AUTOSAR XML (schema 4-2-2)
package /DBC_SysDesc_Can_Network/Pkg_Cluster
  can cluster Can_Network: baudrate=500000, protocol-name=CAN, protocol-version=2023_3_9_163737
    can physical channel Can_Network_Channel: comm-connectors=Conn_Can_Network_CANNODE_0_RDCU
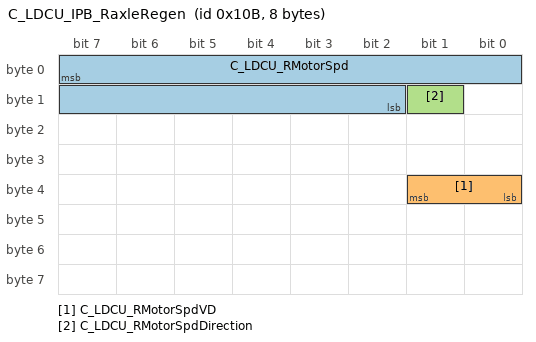
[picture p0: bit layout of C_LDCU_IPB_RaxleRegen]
      frame C_LDCU_IPB_RaxleRegen: id 0x10B, to RDCU, frame-length=8, can-addressing-mode=STANDARD, can-fd-frame-support=true, can-frame-rx-behavior=CAN-FD
        carries pdu C_LDCU_IPB_RaxleRegen: packing-byte-order=big-endian, start-position=7
        pdu C_LDCU_IPB_RaxleRegen: length=8
          transmission-mode-conditions:
            {data-filter={data-filter-type=NEW-IS-WITHIN, max=16000, min=0, offset=0}, i-signal-in-i-pdu=C_LDCU_RMotorSpd}
            {data-filter={data-filter-type=ALWAYS, max=1, min=0, offset=0}, i-signal-in-i-pdu=C_LDCU_RMotorSpdVD}
            {data-filter={data-filter-type=ALWAYS, max=1, min=0, offset=0}, i-signal-in-i-pdu=C_LDCU_RMotorSpdDirection}
            {data-filter={data-filter-type=NEW-IS-WITHIN, max=16000, min=0, offset=0}, i-signal-in-i-pdu=C_LDCU_RMotorSpd}
            {data-filter={data-filter-type=ALWAYS, max=1, min=0, offset=0}, i-signal-in-i-pdu=C_LDCU_RMotorSpdVD}
            {data-filter={data-filter-type=ALWAYS, max=1, min=0, offset=0}, i-signal-in-i-pdu=C_LDCU_RMotorSpdDirection}
          signal C_LDCU_RMotorSpd: start 7, 14 bit, big-endian, init-value=0, base-type=uint16, compu {raw=phys for phys 0..16000; unit rpm}, compu-method=CompuMethod_C_LDCU_RMotorSpd, update-indication-bit-position=-1, to RDCU(timeout 0.1 s)  # Motor speed request"
          signal C_LDCU_RMotorSpdVD: start 33, 2 bit, big-endian, init-value=0, base-type=uint8, compu {phys=raw for raw 0..1, 0=VALID, 1=INVALID}, compu-method=CompuMethod_C_LDCU_RMotorSpdVD, update-indication-bit-position=-1, to RDCU(timeout 0.1 s)
          signal C_LDCU_RMotorSpdDirection: start 9, 1 bit, big-endian, init-value=0, base-type=uint8, compu {phys=raw for raw 0..1, 0=NEGATIVE, 1=POSITIVE}, compu-method=CompuMethod_C_LDCU_RMotorSpdDirection, update-indication-bit-position=-1, to RDCU(timeout 0.1 s)
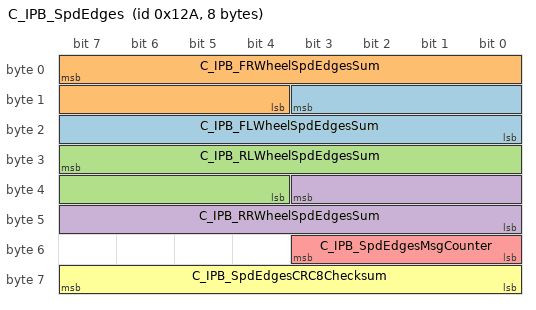
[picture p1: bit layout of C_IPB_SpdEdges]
      frame C_IPB_SpdEdges: id 0x12A, to RDCU, frame-length=8, can-addressing-mode=STANDARD, can-fd-frame-support=true, can-frame-rx-behavior=CAN-FD
        carries pdu C_IPB_SpdEdges: packing-byte-order=big-endian, start-position=7
        pdu C_IPB_SpdEdges: length=8
          transmission-mode-conditions:
            {data-filter={data-filter-type=NEW-IS-WITHIN, max=4095, min=0, offset=0}, i-signal-in-i-pdu=C_IPB_FLWheelSpdEdgesSum}
            {data-filter={data-filter-type=NEW-IS-WITHIN, max=4095, min=0, offset=0}, i-signal-in-i-pdu=C_IPB_FRWheelSpdEdgesSum}
            {data-filter={data-filter-type=NEW-IS-WITHIN, max=4095, min=0, offset=0}, i-signal-in-i-pdu=C_IPB_RLWheelSpdEdgesSum}
            {data-filter={data-filter-type=NEW-IS-WITHIN, max=4095, min=0, offset=0}, i-signal-in-i-pdu=C_IPB_RRWheelSpdEdgesSum}
            {data-filter={data-filter-type=ALWAYS, max=15, min=0, offset=0}, i-signal-in-i-pdu=C_IPB_SpdEdgesMsgCounter}
            {data-filter={data-filter-type=ALWAYS, max=255, min=0, offset=0}, i-signal-in-i-pdu=C_IPB_SpdEdgesCRC8Checksum}
            {data-filter={data-filter-type=NEW-IS-WITHIN, max=4095, min=0, offset=0}, i-signal-in-i-pdu=C_IPB_FLWheelSpdEdgesSum}
            {data-filter={data-filter-type=NEW-IS-WITHIN, max=4095, min=0, offset=0}, i-signal-in-i-pdu=C_IPB_FRWheelSpdEdgesSum}
            {data-filter={data-filter-type=NEW-IS-WITHIN, max=4095, min=0, offset=0}, i-signal-in-i-pdu=C_IPB_RLWheelSpdEdgesSum}
            {data-filter={data-filter-type=NEW-IS-WITHIN, max=4095, min=0, offset=0}, i-signal-in-i-pdu=C_IPB_RRWheelSpdEdgesSum}
            {data-filter={data-filter-type=ALWAYS, max=15, min=0, offset=0}, i-signal-in-i-pdu=C_IPB_SpdEdgesMsgCounter}
            {data-filter={data-filter-type=ALWAYS, max=255, min=0, offset=0}, i-signal-in-i-pdu=C_IPB_SpdEdgesCRC8Checksum}
          signal C_IPB_FLWheelSpdEdgesSum: start 11, 12 bit, big-endian, init-value=0, base-type=uint16, compu {raw=phys for phys 0..4095}, compu-method=CompuMethod_C_IPB_FLWheelSpdEdgesSum, update-indication-bit-position=-1, to RDCU(timeout 0.05 s)  # Accumulated sum of rising and falling edges of front left wheel speed sensor output¡¤since IGN ON,thevalidity/fault information of this signal is also judged by signal ESP_FLWheelSpdVD in ESP_SpdInfoF"
          signal C_IPB_FRWheelSpdEdgesSum: start 7, 12 bit, big-endian, init-value=0, base-type=uint16, compu {raw=phys for phys 0..4095}, compu-method=CompuMethod_C_IPB_FRWheelSpdEdgesSum, update-indication-bit-position=-1, to RDCU(timeout 0.05 s)  # Accumulated sum of rising and falling edges of front left wheel speed sensor output¡¤since IGN ON,thevalidity/fault information of this signal is also judged by signa ESP_FRWheelSpdVD in ESP_SpdInfoF"
          signal C_IPB_RLWheelSpdEdgesSum: start 31, 12 bit, big-endian, init-value=0, base-type=uint16, compu {raw=phys for phys 0..4095}, compu-method=CompuMethod_C_IPB_RLWheelSpdEdgesSum, update-indication-bit-position=-1, to RDCU(timeout 0.05 s)  # Accumulated sum of rising and falling edges of front left wheel speed sensor output¡¤since IGN ON,thevalidity/fault information of this signal is also judged by signa ESP_RLWheelSpdVD in ESP_SpdInfoR"
          signal C_IPB_RRWheelSpdEdgesSum: start 35, 12 bit, big-endian, init-value=0, base-type=uint16, compu {raw=phys for phys 0..4095}, compu-method=CompuMethod_C_IPB_RRWheelSpdEdgesSum, update-indication-bit-position=-1, to RDCU(timeout 0.05 s)  # Accumulated sum of rising and falling edges of front left wheel speed sensor output¡¤since IGN ON,thevalidity/fault information of this signal is also judged by signa ESP_RRWheelSpdVD in ESP_SpdInfoR"
          signal C_IPB_SpdEdgesMsgCounter: start 51, 4 bit, big-endian, init-value=0, base-type=uint8, compu {raw=phys for phys 0..15}, compu-method=CompuMethod_C_IPB_SpdEdgesMsgCounter, update-indication-bit-position=-1, to RDCU(timeout 0.05 s)  # The MessageCounter is a 0 _15 counter, increased of one unit on every message transmission"
          signal C_IPB_SpdEdgesCRC8Checksum: start 63, 8 bit, big-endian, init-value=0, base-type=uint8, compu {raw=phys for phys 0..255}, compu-method=CompuMethod_C_IPB_SpdEdgesCRC8Checksum, update-indication-bit-position=-1, to RDCU(timeout 0.05 s)  # CRC8"
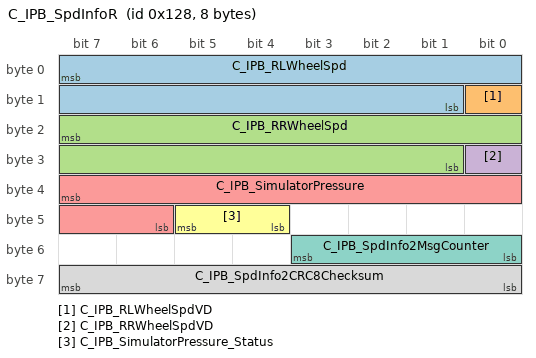
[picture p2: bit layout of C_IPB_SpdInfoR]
      frame C_IPB_SpdInfoR: id 0x128, to RDCU, frame-length=8, can-addressing-mode=STANDARD, can-fd-frame-support=true, can-frame-rx-behavior=CAN-FD
        carries pdu C_IPB_SpdInfoR: packing-byte-order=big-endian, start-position=7
        pdu C_IPB_SpdInfoR: length=8
          transmission-mode-conditions:
            {data-filter={data-filter-type=NEW-IS-WITHIN, max=23999, min=0, offset=0}, i-signal-in-i-pdu=C_IPB_RLWheelSpd}
            {data-filter={data-filter-type=ALWAYS, max=1, min=0, offset=0}, i-signal-in-i-pdu=C_IPB_RLWheelSpdVD}
            {data-filter={data-filter-type=NEW-IS-WITHIN, max=23999, min=0, offset=0}, i-signal-in-i-pdu=C_IPB_RRWheelSpd}
            {data-filter={data-filter-type=ALWAYS, max=1, min=0, offset=0}, i-signal-in-i-pdu=C_IPB_RRWheelSpdVD}
            {data-filter={data-filter-type=NEW-IS-WITHIN, max=1023, min=0}, i-signal-in-i-pdu=C_IPB_SimulatorPressure}
            {data-filter={data-filter-type=ALWAYS, max=3, min=0, offset=0}, i-signal-in-i-pdu=C_IPB_SimulatorPressure_Status}
            {data-filter={data-filter-type=ALWAYS, max=15, min=0, offset=0}, i-signal-in-i-pdu=C_IPB_SpdInfo2MsgCounter}
            {data-filter={data-filter-type=ALWAYS, max=255, min=0, offset=0}, i-signal-in-i-pdu=C_IPB_SpdInfo2CRC8Checksum}
            {data-filter={data-filter-type=NEW-IS-WITHIN, max=23999, min=0, offset=0}, i-signal-in-i-pdu=C_IPB_RLWheelSpd}
            {data-filter={data-filter-type=ALWAYS, max=1, min=0, offset=0}, i-signal-in-i-pdu=C_IPB_RLWheelSpdVD}
            {data-filter={data-filter-type=NEW-IS-WITHIN, max=23999, min=0, offset=0}, i-signal-in-i-pdu=C_IPB_RRWheelSpd}
            {data-filter={data-filter-type=ALWAYS, max=1, min=0, offset=0}, i-signal-in-i-pdu=C_IPB_RRWheelSpdVD}
            {data-filter={data-filter-type=NEW-IS-WITHIN, max=1023, min=0}, i-signal-in-i-pdu=C_IPB_SimulatorPressure}
            {data-filter={data-filter-type=ALWAYS, max=3, min=0, offset=0}, i-signal-in-i-pdu=C_IPB_SimulatorPressure_Status}
            {data-filter={data-filter-type=ALWAYS, max=15, min=0, offset=0}, i-signal-in-i-pdu=C_IPB_SpdInfo2MsgCounter}
            {data-filter={data-filter-type=ALWAYS, max=255, min=0, offset=0}, i-signal-in-i-pdu=C_IPB_SpdInfo2CRC8Checksum}
          signal C_IPB_RLWheelSpd: start 7, 15 bit, big-endian, init-value=0, base-type=uint16, compu {raw=phys*100 for phys 0..239.99; unit kmph}, compu-method=CompuMethod_C_IPB_RLWheelSpd, update-indication-bit-position=-1, to RDCU(timeout 0.05 s)  # valid:0x0~0x5DBF invalid valve/Default value: 7FFF"
          signal C_IPB_RLWheelSpdVD: start 8, 1 bit, big-endian, init-value=0, base-type=uint8, compu {phys=raw for raw 0..1, 0=NOTVALID, 1=VALID}, compu-method=CompuMethod_C_IPB_RLWheelSpdVD, update-indication-bit-position=-1, to RDCU(timeout 0.05 s)
          signal C_IPB_RRWheelSpd: start 23, 15 bit, big-endian, init-value=0, base-type=uint16, compu {raw=phys*100 for phys 0..239.99; unit kmph}, compu-method=CompuMethod_C_IPB_RRWheelSpd, update-indication-bit-position=-1, to RDCU(timeout 0.05 s)  # valid:0x0~0x5DBF invalid valve/Default value: 7FFF"
          signal C_IPB_RRWheelSpdVD: start 24, 1 bit, big-endian, init-value=0, base-type=uint8, compu {phys=raw for raw 0..1, 0=NOTVALID, 1=VALID}, compu-method=CompuMethod_C_IPB_RRWheelSpdVD, update-indication-bit-position=-1, to RDCU(timeout 0.05 s)
          signal C_IPB_SimulatorPressure: start 39, 10 bit, big-endian, init-value=17, base-type=uint16, compu {raw=phys*3.333333333+16.66666667 for phys -5..301.9; unit bar}, compu-method=CompuMethod_C_IPB_SimulatorPressure, update-indication-bit-position=-1, to RDCU(timeout 0.05 s)  # Master cylinder pressure Valid:0x00-0x0x3FE; invalid valve/Default value: 0x3FF;"
          signal C_IPB_SimulatorPressure_Status: start 45, 2 bit, big-endian, init-value=0, base-type=uint8, compu {phys=raw for raw 0..3, 1=VALID, 2=INVALID}, compu-method=CompuMethod_C_IPB_SimulatorPressure_Status, update-indication-bit-position=-1, to RDCU(timeout 0.05 s)
          signal C_IPB_SpdInfo2MsgCounter: start 51, 4 bit, big-endian, init-value=0, base-type=uint8, compu {raw=phys for phys 0..15}, compu-method=CompuMethod_C_IPB_SpdInfo2MsgCounter, update-indication-bit-position=-1, to RDCU(timeout 0.05 s)  # The MessageCounter is a 0 ~ 15 counter, increased of one unit on every message transmission"
          signal C_IPB_SpdInfo2CRC8Checksum: start 63, 8 bit, big-endian, init-value=0, base-type=uint8, compu {raw=phys for phys 0..255}, compu-method=CompuMethod_C_IPB_SpdInfo2CRC8Checksum, update-indication-bit-position=-1, to RDCU(timeout 0.05 s)  # CRC8"
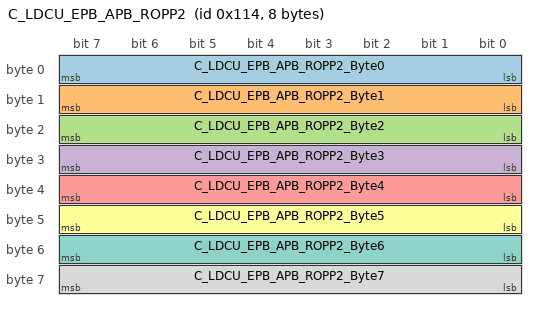
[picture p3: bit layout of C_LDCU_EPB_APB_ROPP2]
      frame C_LDCU_EPB_APB_ROPP2: id 0x114, to RDCU, frame-length=8, can-addressing-mode=STANDARD, can-fd-frame-support=true, can-frame-rx-behavior=CAN-FD  # E2E Profile1 Message"
        carries pdu C_LDCU_EPB_APB_ROPP2: packing-byte-order=big-endian, start-position=7
        pdu C_LDCU_EPB_APB_ROPP2: length=8  # E2E Profile1 Message
          transmission-mode-conditions:
            C_LDCU_EPB_APB_ROPP2_Byte{0..7}
            C_LDCU_EPB_APB_ROPP2_Byte{0..7}
          signal C_LDCU_EPB_APB_ROPP2_Byte0: start 7, 8 bit, big-endian, init-value=0, base-type=uint8, compu {raw=phys for phys 0..255}, compu-method=CompuMethod_C_LDCU_EPB_APB_ROPP2_Byte0, update-indication-bit-position=-1, to RDCU(timeout 0.1 s)
          signal C_LDCU_EPB_APB_ROPP2_Byte1: start 15, 8 bit, big-endian, init-value=0, base-type=uint8, compu {raw=phys for phys 0..255}, compu-method=CompuMethod_C_LDCU_EPB_APB_ROPP2_Byte1, update-indication-bit-position=-1, to RDCU(timeout 0.1 s)
          signal C_LDCU_EPB_APB_ROPP2_Byte2: start 23, 8 bit, big-endian, init-value=128, base-type=uint8, compu {raw=phys for phys 0..255}, compu-method=CompuMethod_C_LDCU_EPB_APB_ROPP2_Byte2, update-indication-bit-position=-1, to RDCU(timeout 0.1 s)
          signal C_LDCU_EPB_APB_ROPP2_Byte3: start 31, 8 bit, big-endian, init-value=0, base-type=uint8, compu {raw=phys for phys 0..255}, compu-method=CompuMethod_C_LDCU_EPB_APB_ROPP2_Byte3, update-indication-bit-position=-1, to RDCU(timeout 0.1 s)
          signal C_LDCU_EPB_APB_ROPP2_Byte4: start 39, 8 bit, big-endian, init-value=4, base-type=uint8, compu {raw=phys for phys 0..255}, compu-method=CompuMethod_C_LDCU_EPB_APB_ROPP2_Byte4, update-indication-bit-position=-1, to RDCU(timeout 0.1 s)
          signal C_LDCU_EPB_APB_ROPP2_Byte5: start 47, 8 bit, big-endian, init-value=0, base-type=uint8, compu {raw=phys for phys 0..255}, compu-method=CompuMethod_C_LDCU_EPB_APB_ROPP2_Byte5, update-indication-bit-position=-1, to RDCU(timeout 0.1 s)
          signal C_LDCU_EPB_APB_ROPP2_Byte6: start 55, 8 bit, big-endian, init-value=0, base-type=uint8, compu {raw=phys for phys 0..255}, compu-method=CompuMethod_C_LDCU_EPB_APB_ROPP2_Byte6, update-indication-bit-position=-1, to RDCU(timeout 0.1 s)
          signal C_LDCU_EPB_APB_ROPP2_Byte7: start 63, 8 bit, big-endian, init-value=0, base-type=uint8, compu {raw=phys for phys 0..255}, compu-method=CompuMethod_C_LDCU_EPB_APB_ROPP2_Byte7, update-indication-bit-position=-1, to RDCU(timeout 0.1 s)
          mapping ISignalToIPduMapping_ISigGrp_C_LDCU_EPB_APB_ROPP2: i-signal-group=ISigGrp_C_LDCU_EPB_APB_ROPP2
      frame C_IPB_SysSt_E2E: id 0x1A6, to RDCU, frame-length=12, can-addressing-mode=STANDARD, can-fd-frame-support=true, can-frame-rx-behavior=CAN-FD  # E2E Profile1 Message"
        carries pdu C_IPB_SysSt_E2E: packing-byte-order=big-endian, start-position=7
        pdu C_IPB_SysSt_E2E: length=12  # E2E Profile1 Message
          transmission-mode-conditions:
            C_IPB_SysSt_E2E_Byte{0..11}
            C_IPB_SysSt_E2E_Byte{0..11}
          signal C_IPB_SysSt_E2E_Byte0: start 7, 8 bit, big-endian, init-value=4, base-type=uint8, compu {raw=phys for phys 0..255}, compu-method=CompuMethod_C_IPB_SysSt_E2E_Byte0, update-indication-bit-position=-1, to RDCU(timeout 0.2 s)
          signal C_IPB_SysSt_E2E_Byte1: start 15, 8 bit, big-endian, init-value=34, base-type=uint8, compu {raw=phys for phys 0..255}, compu-method=CompuMethod_C_IPB_SysSt_E2E_Byte1, update-indication-bit-position=-1, to RDCU(timeout 0.2 s)
          signal C_IPB_SysSt_E2E_Byte2: start 23, 8 bit, big-endian, init-value=113, base-type=uint8, compu {raw=phys for phys 0..255}, compu-method=CompuMethod_C_IPB_SysSt_E2E_Byte2, update-indication-bit-position=-1, to RDCU(timeout 0.2 s)
          signal C_IPB_SysSt_E2E_Byte3: start 31, 8 bit, big-endian, init-value=39, base-type=uint8, compu {raw=phys for phys 0..255}, compu-method=CompuMethod_C_IPB_SysSt_E2E_Byte3, update-indication-bit-position=-1, to RDCU(timeout 0.2 s)
          signal C_IPB_SysSt_E2E_Byte4: start 39, 8 bit, big-endian, init-value=17, base-type=uint8, compu {raw=phys for phys 0..255}, compu-method=CompuMethod_C_IPB_SysSt_E2E_Byte4, update-indication-bit-position=-1, to RDCU(timeout 0.2 s)
          signal C_IPB_SysSt_E2E_Byte5: start 47, 8 bit, big-endian, init-value=116, base-type=uint8, compu {raw=phys for phys 0..255}, compu-method=CompuMethod_C_IPB_SysSt_E2E_Byte5, update-indication-bit-position=-1, to RDCU(timeout 0.2 s)
          signal C_IPB_SysSt_E2E_Byte6: start 55, 8 bit, big-endian, init-value=0, base-type=uint8, compu {raw=phys for phys 0..255}, compu-method=CompuMethod_C_IPB_SysSt_E2E_Byte6, update-indication-bit-position=-1, to RDCU(timeout 0.2 s)
          signal C_IPB_SysSt_E2E_Byte7: start 63, 8 bit, big-endian, init-value=0, base-type=uint8, compu {raw=phys for phys 0..255}, compu-method=CompuMethod_C_IPB_SysSt_E2E_Byte7, update-indication-bit-position=-1, to RDCU(timeout 0.2 s)
          signal C_IPB_SysSt_E2E_Byte8: start 71, 8 bit, big-endian, init-value=0, base-type=uint8, compu {raw=phys for phys 0..255}, compu-method=CompuMethod_C_IPB_SysSt_E2E_Byte8, update-indication-bit-position=-1, to RDCU(timeout 0.2 s)
          signal C_IPB_SysSt_E2E_Byte9: start 79, 8 bit, big-endian, init-value=0, base-type=uint8, compu {raw=phys for phys 0..255}, compu-method=CompuMethod_C_IPB_SysSt_E2E_Byte9, update-indication-bit-position=-1, to RDCU(timeout 0.2 s)
          signal C_IPB_SysSt_E2E_Byte10: start 87, 8 bit, big-endian, init-value=0, base-type=uint8, compu {raw=phys for phys 0..255}, compu-method=CompuMethod_C_IPB_SysSt_E2E_Byte10, update-indication-bit-position=-1, to RDCU(timeout 0.2 s)
          signal C_IPB_SysSt_E2E_Byte11: start 95, 8 bit, big-endian, init-value=0, base-type=uint8, compu {raw=phys for phys 0..255}, compu-method=CompuMethod_C_IPB_SysSt_E2E_Byte11, update-indication-bit-position=-1, to RDCU(timeout 0.2 s)
          mapping ISignalToIPduMapping_ISigGrp_C_IPB_SysSt_E2E: i-signal-group=ISigGrp_C_IPB_SysSt_E2E
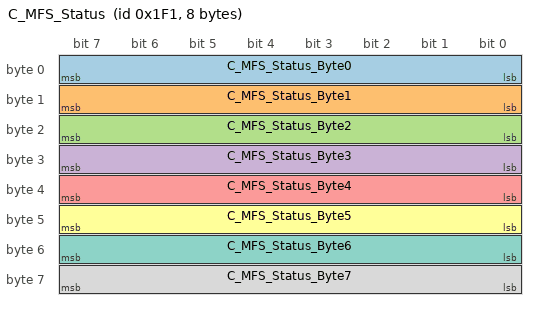
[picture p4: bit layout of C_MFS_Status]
      frame C_MFS_Status: id 0x1F1, to RDCU, frame-length=8, can-addressing-mode=STANDARD, can-fd-frame-support=true, can-frame-rx-behavior=CAN-FD  # E2E Profile1 Message"
        carries pdu C_MFS_Status: packing-byte-order=big-endian, start-position=7
        pdu C_MFS_Status: length=8  # E2E Profile1 Message
          transmission-mode-conditions:
            C_MFS_Status_Byte{0..7}
            C_MFS_Status_Byte{0..7}
          signal C_MFS_Status_Byte0: start 7, 8 bit, big-endian, init-value=0, base-type=uint8, compu {raw=phys for phys 0..255}, compu-method=CompuMethod_C_MFS_Status_Byte0, update-indication-bit-position=-1, to RDCU(timeout 0.2 s)
          signal C_MFS_Status_Byte1: start 15, 8 bit, big-endian, init-value=0, base-type=uint8, compu {raw=phys for phys 0..255}, compu-method=CompuMethod_C_MFS_Status_Byte1, update-indication-bit-position=-1, to RDCU(timeout 0.2 s)
          signal C_MFS_Status_Byte2: start 23, 8 bit, big-endian, init-value=0, base-type=uint8, compu {raw=phys for phys 0..255}, compu-method=CompuMethod_C_MFS_Status_Byte2, update-indication-bit-position=-1, to RDCU(timeout 0.2 s)
          signal C_MFS_Status_Byte3: start 31, 8 bit, big-endian, init-value=0, base-type=uint8, compu {raw=phys for phys 0..255}, compu-method=CompuMethod_C_MFS_Status_Byte3, update-indication-bit-position=-1, to RDCU(timeout 0.2 s)
          signal C_MFS_Status_Byte4: start 39, 8 bit, big-endian, init-value=0, base-type=uint8, compu {raw=phys for phys 0..255}, compu-method=CompuMethod_C_MFS_Status_Byte4, update-indication-bit-position=-1, to RDCU(timeout 0.2 s)
          signal C_MFS_Status_Byte5: start 47, 8 bit, big-endian, init-value=0, base-type=uint8, compu {raw=phys for phys 0..255}, compu-method=CompuMethod_C_MFS_Status_Byte5, update-indication-bit-position=-1, to RDCU(timeout 0.2 s)
          signal C_MFS_Status_Byte6: start 55, 8 bit, big-endian, init-value=0, base-type=uint8, compu {raw=phys for phys 0..255}, compu-method=CompuMethod_C_MFS_Status_Byte6, update-indication-bit-position=-1, to RDCU(timeout 0.2 s)
          signal C_MFS_Status_Byte7: start 63, 8 bit, big-endian, init-value=0, base-type=uint8, compu {raw=phys for phys 0..255}, compu-method=CompuMethod_C_MFS_Status_Byte7, update-indication-bit-position=-1, to RDCU(timeout 0.2 s)
          mapping ISignalToIPduMapping_ISigGrp_C_MFS_Status: i-signal-group=ISigGrp_C_MFS_Status
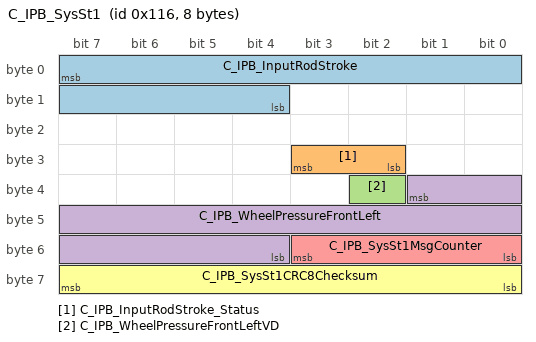
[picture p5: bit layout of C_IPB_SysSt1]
      frame C_IPB_SysSt1: id 0x116, to RDCU, frame-length=8, can-addressing-mode=STANDARD, can-fd-frame-support=true, can-frame-rx-behavior=CAN-FD
        carries pdu C_IPB_SysSt1: packing-byte-order=big-endian, start-position=7
        pdu C_IPB_SysSt1: length=8
          transmission-mode-conditions:
            {data-filter={data-filter-type=NEW-IS-WITHIN, max=1022, min=0}, i-signal-in-i-pdu=C_IPB_InputRodStroke}
            {data-filter={data-filter-type=ALWAYS, max=1, min=0, offset=0}, i-signal-in-i-pdu=C_IPB_InputRodStroke_Status}
            {data-filter={data-filter-type=ALWAYS, max=1, min=0, offset=0}, i-signal-in-i-pdu=C_IPB_WheelPressureFrontLeftVD}
            {data-filter={data-filter-type=NEW-IS-WITHIN, max=13440, min=0}, i-signal-in-i-pdu=C_IPB_WheelPressureFrontLeft}
            {data-filter={data-filter-type=ALWAYS, max=15, min=0, offset=0}, i-signal-in-i-pdu=C_IPB_SysSt1MsgCounter}
            {data-filter={data-filter-type=ALWAYS, max=255, min=0, offset=0}, i-signal-in-i-pdu=C_IPB_SysSt1CRC8Checksum}
            {data-filter={data-filter-type=NEW-IS-WITHIN, max=1022, min=0}, i-signal-in-i-pdu=C_IPB_InputRodStroke}
            {data-filter={data-filter-type=ALWAYS, max=1, min=0, offset=0}, i-signal-in-i-pdu=C_IPB_InputRodStroke_Status}
            {data-filter={data-filter-type=ALWAYS, max=1, min=0, offset=0}, i-signal-in-i-pdu=C_IPB_WheelPressureFrontLeftVD}
            {data-filter={data-filter-type=NEW-IS-WITHIN, max=13440, min=0}, i-signal-in-i-pdu=C_IPB_WheelPressureFrontLeft}
            {data-filter={data-filter-type=ALWAYS, max=15, min=0, offset=0}, i-signal-in-i-pdu=C_IPB_SysSt1MsgCounter}
            {data-filter={data-filter-type=ALWAYS, max=255, min=0, offset=0}, i-signal-in-i-pdu=C_IPB_SysSt1CRC8Checksum}
          signal C_IPB_InputRodStroke: start 7, 12 bit, big-endian, init-value=100, base-type=uint16, compu {raw=phys*20+100 for phys -5..46.15; unit mm}, compu-method=CompuMethod_C_IPB_InputRodStroke, update-indication-bit-position=-1, to RDCU(timeout 0.1 s)
          signal C_IPB_InputRodStroke_Status: start 27, 2 bit, big-endian, init-value=0, base-type=uint8, compu {phys=raw for raw 0..1, 0=VALID, 1=INVALID}, compu-method=CompuMethod_C_IPB_InputRodStroke_Status, update-indication-bit-position=-1, to RDCU(timeout 0.1 s)
          signal C_IPB_WheelPressureFrontLeftVD: start 34, 1 bit, big-endian, init-value=0, base-type=uint8, compu {phys=raw for raw 0..1, 0=NOTVALID, 1=VALID}, compu-method=CompuMethod_C_IPB_WheelPressureFrontLeftVD, update-indication-bit-position=-1, to RDCU(timeout 0.1 s)
          signal C_IPB_WheelPressureFrontLeft: start 33, 14 bit, big-endian, init-value=640, base-type=uint16, compu {raw=phys*32+640 for phys -20..400; unit bar}, compu-method=CompuMethod_C_IPB_WheelPressureFrontLeft, update-indication-bit-position=-1, to RDCU(timeout 0.1 s)  # Estimated or modeled wheel pressure of the rIPBective wheel brake. Modeled wheel pressure is needed in case of active hydraulic control"
          signal C_IPB_SysSt1MsgCounter: start 51, 4 bit, big-endian, init-value=0, base-type=uint8, compu {raw=phys for phys 0..15}, compu-method=CompuMethod_C_IPB_SysSt1MsgCounter, update-indication-bit-position=-1, to RDCU(timeout 0.1 s)  # Be incremented by 1 each time a CAN message has been transmitted by the sensor"
          signal C_IPB_SysSt1CRC8Checksum: start 63, 8 bit, big-endian, init-value=0, base-type=uint8, compu {raw=phys for phys 0..255}, compu-method=CompuMethod_C_IPB_SysSt1CRC8Checksum, update-indication-bit-position=-1, to RDCU(timeout 0.1 s)  # CRC8"
      frame C_AS_SysSt2: id 0x292, to RDCU, frame-length=48, can-addressing-mode=STANDARD, can-fd-frame-support=true, can-frame-rx-behavior=CAN-FD
        carries pdu C_AS_SysSt2: packing-byte-order=big-endian, start-position=7
        pdu C_AS_SysSt2: length=48
          transmission-mode-conditions:
            {data-filter={data-filter-type=NEW-IS-WITHIN, max=2000, min=0}, i-signal-in-i-pdu=C_AS_wheelPosFLFilt_mm}
            {data-filter={data-filter-type=NEW-IS-WITHIN, max=2000, min=0}, i-signal-in-i-pdu=C_AS_wheelPosFRFilt_mm}
            {data-filter={data-filter-type=NEW-IS-WITHIN, max=2000, min=0}, i-signal-in-i-pdu=C_AS_wheelPosRLFilt_mm}
            {data-filter={data-filter-type=NEW-IS-WITHIN, max=2000, min=0}, i-signal-in-i-pdu=C_AS_wheelPosRRFilt_mm}
            {data-filter={data-filter-type=NEW-IS-WITHIN, max=2000, min=0}, i-signal-in-i-pdu=C_AS_wheelPosFLFilt_mm}
            {data-filter={data-filter-type=NEW-IS-WITHIN, max=2000, min=0}, i-signal-in-i-pdu=C_AS_wheelPosFRFilt_mm}
            {data-filter={data-filter-type=NEW-IS-WITHIN, max=2000, min=0}, i-signal-in-i-pdu=C_AS_wheelPosRLFilt_mm}
            {data-filter={data-filter-type=NEW-IS-WITHIN, max=2000, min=0}, i-signal-in-i-pdu=C_AS_wheelPosRRFilt_mm}
          signal C_AS_wheelPosFLFilt_mm: start 7, 11 bit, big-endian, init-value=1000, base-type=uint16, compu {raw=phys+1000 for phys -1000..1000; unit mm}, compu-method=CompuMethod_C_AS_wheelPosFLFilt_mm, update-indication-bit-position=-1, to RDCU(timeout 0.2 s)  # Wheel position FL"
          signal C_AS_wheelPosFRFilt_mm: start 12, 11 bit, big-endian, init-value=1000, base-type=uint16, compu {raw=phys+1000 for phys -1000..1000; unit mm}, compu-method=CompuMethod_C_AS_wheelPosFRFilt_mm, update-indication-bit-position=-1, to RDCU(timeout 0.2 s)  # Wheel position FR"
          signal C_AS_wheelPosRLFilt_mm: start 17, 11 bit, big-endian, init-value=1000, base-type=uint16, compu {raw=phys+1000 for phys -1000..1000; unit mm}, compu-method=CompuMethod_C_AS_wheelPosRLFilt_mm, update-indication-bit-position=-1, to RDCU(timeout 0.2 s)  # Wheel position RL"
          signal C_AS_wheelPosRRFilt_mm: start 38, 11 bit, big-endian, init-value=1000, base-type=uint16, compu {raw=phys+1000 for phys -1000..1000; unit mm}, compu-method=CompuMethod_C_AS_wheelPosRRFilt_mm, update-indication-bit-position=-1, to RDCU(timeout 0.2 s)  # Wheel position RR"
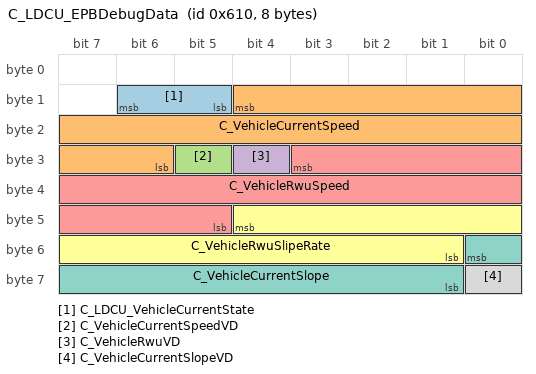
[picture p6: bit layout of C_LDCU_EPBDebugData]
      frame C_LDCU_EPBDebugData: id 0x610, to RDCU, frame-length=8, can-addressing-mode=STANDARD, can-fd-frame-support=true, can-frame-rx-behavior=CAN-FD
        carries pdu C_LDCU_EPBDebugData: packing-byte-order=big-endian, start-position=7
        pdu C_LDCU_EPBDebugData: length=8
          transmission-mode-conditions:
            {data-filter={data-filter-type=ALWAYS, max=3, min=0, offset=0}, i-signal-in-i-pdu=C_LDCU_VehicleCurrentState}
            {data-filter={data-filter-type=NEW-IS-WITHIN, max=23999, min=0, offset=0}, i-signal-in-i-pdu=C_VehicleCurrentSpeed}
            {data-filter={data-filter-type=ALWAYS, max=1, min=0, offset=0}, i-signal-in-i-pdu=C_VehicleCurrentSpeedVD}
            {data-filter={data-filter-type=ALWAYS, max=1, min=0, offset=0}, i-signal-in-i-pdu=C_VehicleRwuVD}
            {data-filter={data-filter-type=NEW-IS-WITHIN, max=23999, min=0, offset=0}, i-signal-in-i-pdu=C_VehicleRwuSpeed}
            {data-filter={data-filter-type=NEW-IS-WITHIN, max=1000, min=0, offset=0}, i-signal-in-i-pdu=C_VehicleRwuSlipeRate}
            {data-filter={data-filter-type=ALWAYS, max=80, min=0}, i-signal-in-i-pdu=C_VehicleCurrentSlope}
            {data-filter={data-filter-type=ALWAYS, max=1, min=0, offset=0}, i-signal-in-i-pdu=C_VehicleCurrentSlopeVD}
            {data-filter={data-filter-type=ALWAYS, max=3, min=0, offset=0}, i-signal-in-i-pdu=C_LDCU_VehicleCurrentState}
            {data-filter={data-filter-type=NEW-IS-WITHIN, max=23999, min=0, offset=0}, i-signal-in-i-pdu=C_VehicleCurrentSpeed}
            {data-filter={data-filter-type=ALWAYS, max=1, min=0, offset=0}, i-signal-in-i-pdu=C_VehicleCurrentSpeedVD}
            {data-filter={data-filter-type=ALWAYS, max=1, min=0, offset=0}, i-signal-in-i-pdu=C_VehicleRwuVD}
            {data-filter={data-filter-type=NEW-IS-WITHIN, max=23999, min=0, offset=0}, i-signal-in-i-pdu=C_VehicleRwuSpeed}
            {data-filter={data-filter-type=NEW-IS-WITHIN, max=1000, min=0, offset=0}, i-signal-in-i-pdu=C_VehicleRwuSlipeRate}
            {data-filter={data-filter-type=ALWAYS, max=80, min=0}, i-signal-in-i-pdu=C_VehicleCurrentSlope}
            {data-filter={data-filter-type=ALWAYS, max=1, min=0, offset=0}, i-signal-in-i-pdu=C_VehicleCurrentSlopeVD}
          signal C_LDCU_VehicleCurrentState: start 14, 2 bit, big-endian, init-value=0, base-type=uint8, compu {phys=raw for raw 0..3, 0=INVALID, 1=STANDSTILL, 2=MOTION, 3=RESERVED}, compu-method=CompuMethod_C_LDCU_VehicleCurrentState, update-indication-bit-position=-1, to RDCU(timeout 1 s)
          signal C_VehicleCurrentSpeed: start 12, 15 bit, big-endian, init-value=0, base-type=uint16, compu {raw=phys*100 for phys 0..239.99; unit kmph}, compu-method=CompuMethod_C_VehicleCurrentSpeed, update-indication-bit-position=-1, to RDCU(timeout 1 s)
          signal C_VehicleCurrentSpeedVD: start 29, 1 bit, big-endian, init-value=0, base-type=uint8, compu {phys=raw for raw 0..1, 0=NOTVALID, 1=VALID}, compu-method=CompuMethod_C_VehicleCurrentSpeedVD, update-indication-bit-position=-1, to RDCU(timeout 1 s)
          signal C_VehicleRwuVD: start 28, 1 bit, big-endian, init-value=0, base-type=uint8, compu {phys=raw for raw 0..1, 0=NOTVALID, 1=VALID}, compu-method=CompuMethod_C_VehicleRwuVD, update-indication-bit-position=-1, to RDCU(timeout 1 s)
          signal C_VehicleRwuSpeed: start 27, 15 bit, big-endian, init-value=0, base-type=uint16, compu {raw=phys*100 for phys 0..239.99; unit kmph}, compu-method=CompuMethod_C_VehicleRwuSpeed, update-indication-bit-position=-1, to RDCU(timeout 1 s)
          signal C_VehicleRwuSlipeRate: start 44, 12 bit, big-endian, init-value=0, base-type=uint16, compu {raw=phys*10 for phys 0..100; unit percent}, compu-method=CompuMethod_C_VehicleRwuSlipeRate, update-indication-bit-position=-1, to RDCU(timeout 1 s)
          signal C_VehicleCurrentSlope: start 48, 8 bit, big-endian, init-value=40, base-type=uint8, compu {raw=phys+40 for phys -40..40; unit percent}, compu-method=CompuMethod_C_VehicleCurrentSlope, update-indication-bit-position=-1, to RDCU(timeout 1 s)
          signal C_VehicleCurrentSlopeVD: start 56, 1 bit, big-endian, init-value=0, base-type=uint8, compu {phys=raw for raw 0..1, 0=NOTVALID, 1=VALID}, compu-method=CompuMethod_C_VehicleCurrentSlopeVD, update-indication-bit-position=-1, to RDCU(timeout 1 s)
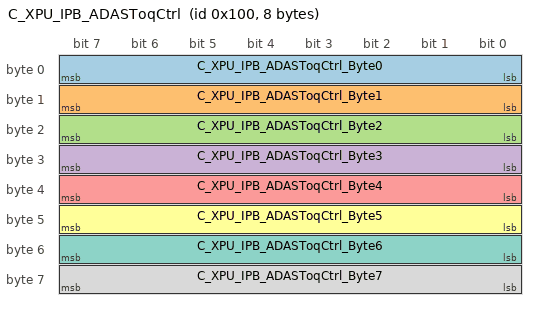
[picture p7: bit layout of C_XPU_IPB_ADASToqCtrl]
      frame C_XPU_IPB_ADASToqCtrl: id 0x100, to RDCU, frame-length=8, can-addressing-mode=STANDARD, can-fd-frame-support=true, can-frame-rx-behavior=CAN-FD  # E2E Profile1 Message"
        carries pdu C_XPU_IPB_ADASToqCtrl: packing-byte-order=big-endian, start-position=7
        pdu C_XPU_IPB_ADASToqCtrl: length=8  # E2E Profile1 Message
          transmission-mode-conditions:
            C_XPU_IPB_ADASToqCtrl_Byte{0..7}
            C_XPU_IPB_ADASToqCtrl_Byte{0..7}
          signal C_XPU_IPB_ADASToqCtrl_Byte0: start 7, 8 bit, big-endian, init-value=0, base-type=uint8, compu {raw=phys for phys 0..255}, compu-method=CompuMethod_C_XPU_IPB_ADASToqCtrl_Byte0, update-indication-bit-position=-1, to RDCU(timeout 0.1 s)
          signal C_XPU_IPB_ADASToqCtrl_Byte1: start 15, 8 bit, big-endian, init-value=4, base-type=uint8, compu {raw=phys for phys 0..255}, compu-method=CompuMethod_C_XPU_IPB_ADASToqCtrl_Byte1, update-indication-bit-position=-1, to RDCU(timeout 0.1 s)
          signal C_XPU_IPB_ADASToqCtrl_Byte2: start 23, 8 bit, big-endian, init-value=0, base-type=uint8, compu {raw=phys for phys 0..255}, compu-method=CompuMethod_C_XPU_IPB_ADASToqCtrl_Byte2, update-indication-bit-position=-1, to RDCU(timeout 0.1 s)
          signal C_XPU_IPB_ADASToqCtrl_Byte3: start 31, 8 bit, big-endian, init-value=0, base-type=uint8, compu {raw=phys for phys 0..255}, compu-method=CompuMethod_C_XPU_IPB_ADASToqCtrl_Byte3, update-indication-bit-position=-1, to RDCU(timeout 0.1 s)
          signal C_XPU_IPB_ADASToqCtrl_Byte4: start 39, 8 bit, big-endian, init-value=0, base-type=uint8, compu {raw=phys for phys 0..255}, compu-method=CompuMethod_C_XPU_IPB_ADASToqCtrl_Byte4, update-indication-bit-position=-1, to RDCU(timeout 0.1 s)
          signal C_XPU_IPB_ADASToqCtrl_Byte5: start 47, 8 bit, big-endian, init-value=0, base-type=uint8, compu {raw=phys for phys 0..255}, compu-method=CompuMethod_C_XPU_IPB_ADASToqCtrl_Byte5, update-indication-bit-position=-1, to RDCU(timeout 0.1 s)
          signal C_XPU_IPB_ADASToqCtrl_Byte6: start 55, 8 bit, big-endian, init-value=0, base-type=uint8, compu {raw=phys for phys 0..255}, compu-method=CompuMethod_C_XPU_IPB_ADASToqCtrl_Byte6, update-indication-bit-position=-1, to RDCU(timeout 0.1 s)
          signal C_XPU_IPB_ADASToqCtrl_Byte7: start 63, 8 bit, big-endian, init-value=0, base-type=uint8, compu {raw=phys for phys 0..255}, compu-method=CompuMethod_C_XPU_IPB_ADASToqCtrl_Byte7, update-indication-bit-position=-1, to RDCU(timeout 0.1 s)
          mapping ISignalToIPduMapping_ISigGrp_C_XPU_IPB_ADASToqCtrl: i-signal-group=ISigGrp_C_XPU_IPB_ADASToqCtrl
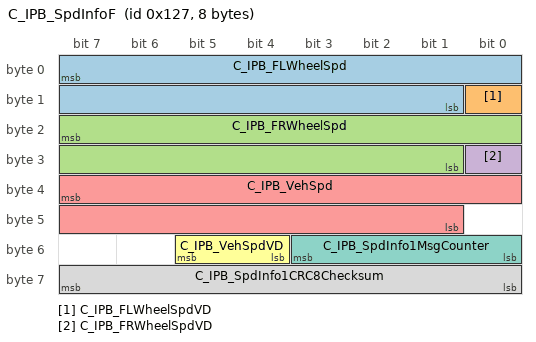
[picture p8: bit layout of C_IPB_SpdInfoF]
      frame C_IPB_SpdInfoF: id 0x127, to RDCU, frame-length=8, can-addressing-mode=STANDARD, can-fd-frame-support=true, can-frame-rx-behavior=CAN-FD  # IDS"
        carries pdu C_IPB_SpdInfoF: packing-byte-order=big-endian, start-position=7
        pdu C_IPB_SpdInfoF: length=8  # IDS
          transmission-mode-conditions:
            {data-filter={data-filter-type=NEW-IS-WITHIN, max=23999, min=0, offset=0}, i-signal-in-i-pdu=C_IPB_FLWheelSpd}
            {data-filter={data-filter-type=ALWAYS, max=1, min=0, offset=0}, i-signal-in-i-pdu=C_IPB_FLWheelSpdVD}
            {data-filter={data-filter-type=NEW-IS-WITHIN, max=23999, min=0, offset=0}, i-signal-in-i-pdu=C_IPB_FRWheelSpd}
            {data-filter={data-filter-type=ALWAYS, max=1, min=0, offset=0}, i-signal-in-i-pdu=C_IPB_FRWheelSpdVD}
            {data-filter={data-filter-type=NEW-IS-WITHIN, max=23999, min=0, offset=0}, i-signal-in-i-pdu=C_IPB_VehSpd}
            {data-filter={data-filter-type=ALWAYS, max=3, min=0, offset=0}, i-signal-in-i-pdu=C_IPB_VehSpdVD}
            {data-filter={data-filter-type=ALWAYS, max=15, min=0, offset=0}, i-signal-in-i-pdu=C_IPB_SpdInfo1MsgCounter}
            {data-filter={data-filter-type=ALWAYS, max=255, min=0, offset=0}, i-signal-in-i-pdu=C_IPB_SpdInfo1CRC8Checksum}
            {data-filter={data-filter-type=NEW-IS-WITHIN, max=23999, min=0, offset=0}, i-signal-in-i-pdu=C_IPB_FLWheelSpd}
            {data-filter={data-filter-type=ALWAYS, max=1, min=0, offset=0}, i-signal-in-i-pdu=C_IPB_FLWheelSpdVD}
            {data-filter={data-filter-type=NEW-IS-WITHIN, max=23999, min=0, offset=0}, i-signal-in-i-pdu=C_IPB_FRWheelSpd}
            {data-filter={data-filter-type=ALWAYS, max=1, min=0, offset=0}, i-signal-in-i-pdu=C_IPB_FRWheelSpdVD}
            {data-filter={data-filter-type=NEW-IS-WITHIN, max=23999, min=0, offset=0}, i-signal-in-i-pdu=C_IPB_VehSpd}
            {data-filter={data-filter-type=ALWAYS, max=3, min=0, offset=0}, i-signal-in-i-pdu=C_IPB_VehSpdVD}
            {data-filter={data-filter-type=ALWAYS, max=15, min=0, offset=0}, i-signal-in-i-pdu=C_IPB_SpdInfo1MsgCounter}
            {data-filter={data-filter-type=ALWAYS, max=255, min=0, offset=0}, i-signal-in-i-pdu=C_IPB_SpdInfo1CRC8Checksum}
          signal C_IPB_FLWheelSpd: start 7, 15 bit, big-endian, init-value=0, base-type=uint16, compu {raw=phys*100 for phys 0..239.99; unit kmph}, compu-method=CompuMethod_C_IPB_FLWheelSpd, update-indication-bit-position=-1, to RDCU(timeout 0.05 s)  # valid:0x0~0x5DBF invalid valve/Default value: 7FFF"
          signal C_IPB_FLWheelSpdVD: start 8, 1 bit, big-endian, init-value=0, base-type=uint8, compu {phys=raw for raw 0..1, 0=NOTVALID, 1=VALID}, compu-method=CompuMethod_C_IPB_FLWheelSpdVD, update-indication-bit-position=-1, to RDCU(timeout 0.05 s)
          signal C_IPB_FRWheelSpd: start 23, 15 bit, big-endian, init-value=0, base-type=uint16, compu {raw=phys*100 for phys 0..239.99; unit kmph}, compu-method=CompuMethod_C_IPB_FRWheelSpd, update-indication-bit-position=-1, to RDCU(timeout 0.05 s)  # valid:0x0~0x5DBF invalid valve/Default value: 7FFF"
          signal C_IPB_FRWheelSpdVD: start 24, 1 bit, big-endian, init-value=0, base-type=uint8, compu {phys=raw for raw 0..1, 0=NOTVALID, 1=VALID}, compu-method=CompuMethod_C_IPB_FRWheelSpdVD, update-indication-bit-position=-1, to RDCU(timeout 0.05 s)
          signal C_IPB_VehSpd: start 39, 15 bit, big-endian, init-value=0, base-type=uint16, compu {raw=phys*100 for phys 0..239.99; unit kmph}, compu-method=CompuMethod_C_IPB_VehSpd, update-indication-bit-position=-1, to RDCU(timeout 0.05 s)  # valid:0x0~0x5DBF invalid valve/Default value: 7FFF"
          signal C_IPB_VehSpdVD: start 53, 2 bit, big-endian, init-value=0, base-type=uint8, compu {phys=raw for raw 0..3, 0=NOTINITIALIZED, 1=VALID, 2=INVALID, 3=RESERVED}, compu-method=CompuMethod_C_IPB_VehSpdVD, update-indication-bit-position=-1, to RDCU(timeout 0.05 s)
          signal C_IPB_SpdInfo1MsgCounter: start 51, 4 bit, big-endian, init-value=0, base-type=uint8, compu {raw=phys for phys 0..15}, compu-method=CompuMethod_C_IPB_SpdInfo1MsgCounter, update-indication-bit-position=-1, to RDCU(timeout 0.05 s)  # The MessageCounter is a 0 ~ 15 counter, increased of one unit on every message transmission"
          signal C_IPB_SpdInfo1CRC8Checksum: start 63, 8 bit, big-endian, init-value=0, base-type=uint8, compu {raw=phys for phys 0..255}, compu-method=CompuMethod_C_IPB_SpdInfo1CRC8Checksum, update-indication-bit-position=-1, to RDCU(timeout 0.05 s)  # CRC8"
      frame C_IPB_SpdInfo_E2E: id 0x126, to RDCU, frame-length=16, can-addressing-mode=STANDARD, can-fd-frame-support=true, can-frame-rx-behavior=CAN-FD  # E2E Profile1 Message"
        carries pdu C_IPB_SpdInfo_E2E: packing-byte-order=big-endian, start-position=7
        pdu C_IPB_SpdInfo_E2E: length=16  # E2E Profile1 Message
          transmission-mode-conditions:
            C_IPB_SpdInfo_E2E_Byte{0..15}
            C_IPB_SpdInfo_E2E_Byte{0..15}
          signal C_IPB_SpdInfo_E2E_Byte0: start 7, 8 bit, big-endian, init-value=0, base-type=uint8, compu {raw=phys for phys 0..255}, compu-method=CompuMethod_C_IPB_SpdInfo_E2E_Byte0, update-indication-bit-position=-1, to RDCU(timeout 0.05 s)
          signal C_IPB_SpdInfo_E2E_Byte1: start 15, 8 bit, big-endian, init-value=0, base-type=uint8, compu {raw=phys for phys 0..255}, compu-method=CompuMethod_C_IPB_SpdInfo_E2E_Byte1, update-indication-bit-position=-1, to RDCU(timeout 0.05 s)
          signal C_IPB_SpdInfo_E2E_Byte2: start 23, 8 bit, big-endian, init-value=0, base-type=uint8, compu {raw=phys for phys 0..255}, compu-method=CompuMethod_C_IPB_SpdInfo_E2E_Byte2, update-indication-bit-position=-1, to RDCU(timeout 0.05 s)
          signal C_IPB_SpdInfo_E2E_Byte3: start 31, 8 bit, big-endian, init-value=0, base-type=uint8, compu {raw=phys for phys 0..255}, compu-method=CompuMethod_C_IPB_SpdInfo_E2E_Byte3, update-indication-bit-position=-1, to RDCU(timeout 0.05 s)
          signal C_IPB_SpdInfo_E2E_Byte4: start 39, 8 bit, big-endian, init-value=0, base-type=uint8, compu {raw=phys for phys 0..255}, compu-method=CompuMethod_C_IPB_SpdInfo_E2E_Byte4, update-indication-bit-position=-1, to RDCU(timeout 0.05 s)
          signal C_IPB_SpdInfo_E2E_Byte5: start 47, 8 bit, big-endian, init-value=0, base-type=uint8, compu {raw=phys for phys 0..255}, compu-method=CompuMethod_C_IPB_SpdInfo_E2E_Byte5, update-indication-bit-position=-1, to RDCU(timeout 0.05 s)
          signal C_IPB_SpdInfo_E2E_Byte6: start 55, 8 bit, big-endian, init-value=0, base-type=uint8, compu {raw=phys for phys 0..255}, compu-method=CompuMethod_C_IPB_SpdInfo_E2E_Byte6, update-indication-bit-position=-1, to RDCU(timeout 0.05 s)
          signal C_IPB_SpdInfo_E2E_Byte7: start 63, 8 bit, big-endian, init-value=0, base-type=uint8, compu {raw=phys for phys 0..255}, compu-method=CompuMethod_C_IPB_SpdInfo_E2E_Byte7, update-indication-bit-position=-1, to RDCU(timeout 0.05 s)
          signal C_IPB_SpdInfo_E2E_Byte8: start 71, 8 bit, big-endian, init-value=0, base-type=uint8, compu {raw=phys for phys 0..255}, compu-method=CompuMethod_C_IPB_SpdInfo_E2E_Byte8, update-indication-bit-position=-1, to RDCU(timeout 0.05 s)
          signal C_IPB_SpdInfo_E2E_Byte9: start 79, 8 bit, big-endian, init-value=0, base-type=uint8, compu {raw=phys for phys 0..255}, compu-method=CompuMethod_C_IPB_SpdInfo_E2E_Byte9, update-indication-bit-position=-1, to RDCU(timeout 0.05 s)
          signal C_IPB_SpdInfo_E2E_Byte10: start 87, 8 bit, big-endian, init-value=0, base-type=uint8, compu {raw=phys for phys 0..255}, compu-method=CompuMethod_C_IPB_SpdInfo_E2E_Byte10, update-indication-bit-position=-1, to RDCU(timeout 0.05 s)
          signal C_IPB_SpdInfo_E2E_Byte11: start 95, 8 bit, big-endian, init-value=0, base-type=uint8, compu {raw=phys for phys 0..255}, compu-method=CompuMethod_C_IPB_SpdInfo_E2E_Byte11, update-indication-bit-position=-1, to RDCU(timeout 0.05 s)
          signal C_IPB_SpdInfo_E2E_Byte12: start 103, 8 bit, big-endian, init-value=0, base-type=uint8, compu {raw=phys for phys 0..255}, compu-method=CompuMethod_C_IPB_SpdInfo_E2E_Byte12, update-indication-bit-position=-1, to RDCU(timeout 0.05 s)
          signal C_IPB_SpdInfo_E2E_Byte13: start 111, 8 bit, big-endian, init-value=0, base-type=uint8, compu {raw=phys for phys 0..255}, compu-method=CompuMethod_C_IPB_SpdInfo_E2E_Byte13, update-indication-bit-position=-1, to RDCU(timeout 0.05 s)
          signal C_IPB_SpdInfo_E2E_Byte14: start 119, 8 bit, big-endian, init-value=0, base-type=uint8, compu {raw=phys for phys 0..255}, compu-method=CompuMethod_C_IPB_SpdInfo_E2E_Byte14, update-indication-bit-position=-1, to RDCU(timeout 0.05 s)
          signal C_IPB_SpdInfo_E2E_Byte15: start 127, 8 bit, big-endian, init-value=0, base-type=uint8, compu {raw=phys for phys 0..255}, compu-method=CompuMethod_C_IPB_SpdInfo_E2E_Byte15, update-indication-bit-position=-1, to RDCU(timeout 0.05 s)
          mapping ISignalToIPduMapping_ISigGrp_C_IPB_SpdInfo_E2E: i-signal-group=ISigGrp_C_IPB_SpdInfo_E2E
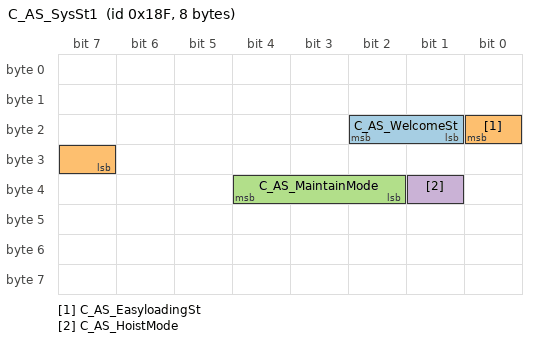
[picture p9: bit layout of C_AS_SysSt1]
      frame C_AS_SysSt1: id 0x18F, to RDCU, frame-length=8, can-addressing-mode=STANDARD, can-fd-frame-support=true, can-frame-rx-behavior=CAN-FD
        carries pdu C_AS_SysSt1: packing-byte-order=big-endian, start-position=7
        pdu C_AS_SysSt1: length=8
          transmission-mode-conditions:
            {data-filter={data-filter-type=ALWAYS, max=3, min=0, offset=0}, i-signal-in-i-pdu=C_AS_WelcomeSt}
            {data-filter={data-filter-type=ALWAYS, max=3, min=0, offset=0}, i-signal-in-i-pdu=C_AS_EasyloadingSt}
            {data-filter={data-filter-type=ALWAYS, max=7, min=0, offset=0}, i-signal-in-i-pdu=C_AS_MaintainMode}
            {data-filter={data-filter-type=ALWAYS, max=1, min=0, offset=0}, i-signal-in-i-pdu=C_AS_HoistMode}
            {data-filter={data-filter-type=ALWAYS, max=3, min=0, offset=0}, i-signal-in-i-pdu=C_AS_WelcomeSt}
            {data-filter={data-filter-type=ALWAYS, max=3, min=0, offset=0}, i-signal-in-i-pdu=C_AS_EasyloadingSt}
            {data-filter={data-filter-type=ALWAYS, max=7, min=0, offset=0}, i-signal-in-i-pdu=C_AS_MaintainMode}
            {data-filter={data-filter-type=ALWAYS, max=1, min=0, offset=0}, i-signal-in-i-pdu=C_AS_HoistMode}
          signal C_AS_WelcomeSt: start 18, 2 bit, big-endian, init-value=0, base-type=uint8, compu {phys=raw for raw 0..3, 0=INVALID, 1=NOTACTIVE, 2=ACTIVE, 3=RESERVED}, compu-method=CompuMethod_C_AS_WelcomeSt, update-indication-bit-position=-1, to RDCU(timeout 0.2 s)
          signal C_AS_EasyloadingSt: start 16, 2 bit, big-endian, init-value=0, base-type=uint8, compu {phys=raw for raw 0..3, 0=INVALID, 1=NOTACTIVE, 2=ACTIVE, 3=RESERVED}, compu-method=CompuMethod_C_AS_EasyloadingSt, update-indication-bit-position=-1, to RDCU(timeout 0.2 s)
          signal C_AS_MaintainMode: start 36, 3 bit, big-endian, init-value=4, base-type=uint8, compu {phys=raw for raw 0..7, 0=NOREQUEST, 1=MAINTENANCEMODE, 2=TRANSPORTMODE, 3=TRAILERMODE, 4=RESERVED, 5=RESERVED, 6=CAMPINGMODE}, compu-method=CompuMethod_C_AS_MaintainMode, update-indication-bit-position=-1, to RDCU(timeout 0.2 s)
          signal C_AS_HoistMode: start 33, 1 bit, big-endian, init-value=0, base-type=uint8, compu {phys=raw for raw 0..1, 0=NOTACTIVE, 1=ACTIVE}, compu-method=CompuMethod_C_AS_HoistMode, update-indication-bit-position=-1, to RDCU(timeout 0.2 s)
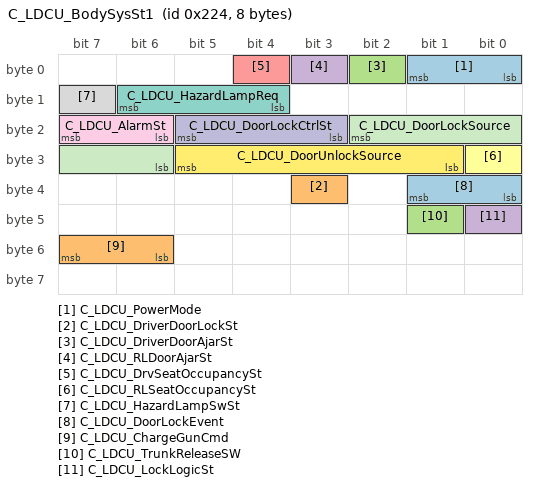
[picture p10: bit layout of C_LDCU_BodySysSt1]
      frame C_LDCU_BodySysSt1: id 0x224, to RDCU, frame-length=8, can-addressing-mode=STANDARD, can-fd-frame-support=true, can-frame-rx-behavior=CAN-FD
        carries pdu C_LDCU_BodySysSt1: packing-byte-order=big-endian, start-position=7
        pdu C_LDCU_BodySysSt1: length=8
          transmission-mode-conditions:
            {data-filter={data-filter-type=ALWAYS, max=3, min=0, offset=0}, i-signal-in-i-pdu=C_LDCU_PowerMode}
            {data-filter={data-filter-type=ALWAYS, max=1, min=0, offset=0}, i-signal-in-i-pdu=C_LDCU_DriverDoorLockSt}
            {data-filter={data-filter-type=ALWAYS, max=1, min=0, offset=0}, i-signal-in-i-pdu=C_LDCU_DriverDoorAjarSt}
            {data-filter={data-filter-type=ALWAYS, max=1, min=0, offset=0}, i-signal-in-i-pdu=C_LDCU_RLDoorAjarSt}
            {data-filter={data-filter-type=ALWAYS, max=1, min=0, offset=0}, i-signal-in-i-pdu=C_LDCU_DrvSeatOccupancySt}
            {data-filter={data-filter-type=ALWAYS, max=1, min=0, offset=0}, i-signal-in-i-pdu=C_LDCU_RLSeatOccupancySt}
            {data-filter={data-filter-type=ALWAYS, max=7, min=0, offset=0}, i-signal-in-i-pdu=C_LDCU_HazardLampReq}
            {data-filter={data-filter-type=ALWAYS, max=1, min=0, offset=0}, i-signal-in-i-pdu=C_LDCU_HazardLampSwSt}
            {data-filter={data-filter-type=ALWAYS, max=3, min=0, offset=0}, i-signal-in-i-pdu=C_LDCU_AlarmSt}
            {data-filter={data-filter-type=ALWAYS, max=7, min=0, offset=0}, i-signal-in-i-pdu=C_LDCU_DoorLockCtrlSt}
            {data-filter={data-filter-type=ALWAYS, max=31, min=0, offset=0}, i-signal-in-i-pdu=C_LDCU_DoorLockSource}
            {data-filter={data-filter-type=ALWAYS, max=31, min=0, offset=0}, i-signal-in-i-pdu=C_LDCU_DoorUnlockSource}
            {data-filter={data-filter-type=ALWAYS, max=3, min=0, offset=0}, i-signal-in-i-pdu=C_LDCU_DoorLockEvent}
            {data-filter={data-filter-type=ALWAYS, max=3, min=0, offset=0}, i-signal-in-i-pdu=C_LDCU_ChargeGunCmd}
            {data-filter={data-filter-type=ALWAYS, max=1, min=0, offset=0}, i-signal-in-i-pdu=C_LDCU_TrunkReleaseSW}
            {data-filter={data-filter-type=ALWAYS, max=1, min=0, offset=0}, i-signal-in-i-pdu=C_LDCU_LockLogicSt}
            {data-filter={data-filter-type=ALWAYS, max=3, min=0, offset=0}, i-signal-in-i-pdu=C_LDCU_PowerMode}
            {data-filter={data-filter-type=ALWAYS, max=1, min=0, offset=0}, i-signal-in-i-pdu=C_LDCU_DriverDoorLockSt}
            {data-filter={data-filter-type=ALWAYS, max=1, min=0, offset=0}, i-signal-in-i-pdu=C_LDCU_DriverDoorAjarSt}
            {data-filter={data-filter-type=ALWAYS, max=1, min=0, offset=0}, i-signal-in-i-pdu=C_LDCU_RLDoorAjarSt}
            {data-filter={data-filter-type=ALWAYS, max=1, min=0, offset=0}, i-signal-in-i-pdu=C_LDCU_DrvSeatOccupancySt}
            {data-filter={data-filter-type=ALWAYS, max=1, min=0, offset=0}, i-signal-in-i-pdu=C_LDCU_RLSeatOccupancySt}
            {data-filter={data-filter-type=ALWAYS, max=7, min=0, offset=0}, i-signal-in-i-pdu=C_LDCU_HazardLampReq}
            {data-filter={data-filter-type=ALWAYS, max=1, min=0, offset=0}, i-signal-in-i-pdu=C_LDCU_HazardLampSwSt}
            {data-filter={data-filter-type=ALWAYS, max=3, min=0, offset=0}, i-signal-in-i-pdu=C_LDCU_AlarmSt}
            {data-filter={data-filter-type=ALWAYS, max=7, min=0, offset=0}, i-signal-in-i-pdu=C_LDCU_DoorLockCtrlSt}
            {data-filter={data-filter-type=ALWAYS, max=31, min=0, offset=0}, i-signal-in-i-pdu=C_LDCU_DoorLockSource}
            {data-filter={data-filter-type=ALWAYS, max=31, min=0, offset=0}, i-signal-in-i-pdu=C_LDCU_DoorUnlockSource}
            {data-filter={data-filter-type=ALWAYS, max=3, min=0, offset=0}, i-signal-in-i-pdu=C_LDCU_DoorLockEvent}
            {data-filter={data-filter-type=ALWAYS, max=3, min=0, offset=0}, i-signal-in-i-pdu=C_LDCU_ChargeGunCmd}
            {data-filter={data-filter-type=ALWAYS, max=1, min=0, offset=0}, i-signal-in-i-pdu=C_LDCU_TrunkReleaseSW}
            {data-filter={data-filter-type=ALWAYS, max=1, min=0, offset=0}, i-signal-in-i-pdu=C_LDCU_LockLogicSt}
          signal C_LDCU_PowerMode: start 1, 2 bit, big-endian, init-value=0, base-type=uint8, compu {phys=raw for raw 0..3, 0=OFF, 1=LOCALON, 2=REMOTEON, 3=RESERVED}, compu-method=CompuMethod_C_LDCU_PowerMode, update-indication-bit-position=-1, to RDCU(timeout 0.4 s)
          signal C_LDCU_DriverDoorLockSt: start 35, 1 bit, big-endian, init-value=0, base-type=uint8, compu {phys=raw for raw 0..1, 0=UNLOCK, 1=LOCK}, compu-method=CompuMethod_C_LDCU_DriverDoorLockSt, update-indication-bit-position=-1, to RDCU(timeout 0.4 s)
          signal C_LDCU_DriverDoorAjarSt: start 2, 1 bit, big-endian, init-value=0, base-type=uint8, compu {phys=raw for raw 0..1, 0=CLOSED, 1=OPEN}, compu-method=CompuMethod_C_LDCU_DriverDoorAjarSt, update-indication-bit-position=-1, to RDCU(timeout 0.4 s)
          signal C_LDCU_RLDoorAjarSt: start 3, 1 bit, big-endian, init-value=0, base-type=uint8, compu {phys=raw for raw 0..1, 0=CLOSED, 1=OPEN}, compu-method=CompuMethod_C_LDCU_RLDoorAjarSt, update-indication-bit-position=-1, to RDCU(timeout 0.4 s)
          signal C_LDCU_DrvSeatOccupancySt: start 4, 1 bit, big-endian, init-value=0, base-type=uint8, compu {phys=raw for raw 0..1, 0=NOTOCCUPIED, 1=OCCUPIED}, compu-method=CompuMethod_C_LDCU_DrvSeatOccupancySt, update-indication-bit-position=-1, to RDCU(timeout 0.4 s)
          signal C_LDCU_RLSeatOccupancySt: start 24, 1 bit, big-endian, init-value=0, base-type=uint8, compu {phys=raw for raw 0..1, 0=NOTOCCUPIED, 1=OCCUPIED}, compu-method=CompuMethod_C_LDCU_RLSeatOccupancySt, update-indication-bit-position=-1, to RDCU(timeout 0.4 s)
          signal C_LDCU_HazardLampReq: start 14, 3 bit, big-endian, init-value=0, base-type=uint8, compu {phys=raw for raw 0..7, 0=NOCOMMAND, 1=ONCE, 2=TWICE, 3..7=RESERVED}, compu-method=CompuMethod_C_LDCU_HazardLampReq, update-indication-bit-position=-1, to RDCU(timeout 0.4 s)
          signal C_LDCU_HazardLampSwSt: start 15, 1 bit, big-endian, init-value=0, base-type=uint8, compu {phys=raw for raw 0..1, 0=OFF, 1=ON}, compu-method=CompuMethod_C_LDCU_HazardLampSwSt, update-indication-bit-position=-1, to RDCU(timeout 0.4 s)
          signal C_LDCU_AlarmSt: start 23, 2 bit, big-endian, init-value=0, base-type=uint8, compu {phys=raw for raw 0..3, 0=ARMED, 1=PREARMED, 2=DISARMED, 3=ALARM}, compu-method=CompuMethod_C_LDCU_AlarmSt, update-indication-bit-position=-1, to RDCU(timeout 0.4 s)  # Anti-theft warning status"
          signal C_LDCU_DoorLockCtrlSt: start 21, 3 bit, big-endian, init-value=0, base-type=uint8, compu {phys=raw for raw 0..7, 0=NOCOMMAND, 1=DRIVERDOORUNLOCK, 2=ALLUNLOCK, 3=ALLLOCK, 4..7=RESERVED}, compu-method=CompuMethod_C_LDCU_DoorLockCtrlSt, update-indication-bit-position=-1, to RDCU(timeout 0.4 s)
          signal C_LDCU_DoorLockSource: start 18, 5 bit, big-endian, init-value=0, base-type=uint8, compu {phys=raw for raw 0..31, 22..31=RESERVED, 10=SPEEDLOCK, 11=BLEPOLLINGLOCK, 12=OTALOCK, 13=XPULOCK, 14=FOURGTMPYLOCK, 15=BLETMPYLOCK, 16=SILENTLOCK, 17=UWBPELOCK, 18=UWBPOLLINGLOCK, 19=BLEWATCHLOCK, 0=NOCOMMAND, 1=RKELOCK, 2=POLLINGLOCK, 3=NFCLOCK, 4=BLELOCK, 5=FOURGLOCK, 6=CENTERSWLOCK, 7=CDCUSWLOCK, 8=PHYSICALLOCK, 9=SECONDLOCK, 20=SOALOCK, 21=RESERVED}, compu-method=CompuMethod_C_LDCU_DoorLockSource, update-indication-bit-position=-1, to RDCU(timeout 0.4 s)
          signal C_LDCU_DoorUnlockSource: start 29, 5 bit, big-endian, init-value=0, base-type=uint8, compu {phys=raw for raw 0..31, 22=FOURGREADYUNLOCK, 23=SOAUNLOCK, 24..31=RESERVED, 10=CRASHUNLOCK, 11=XPUUNLOCK, 12=BLEPOLLINGUNLOCK, 13=THERMALRUNAWAYUNLOCK, 14=ALM_UNLOCK, 15=MECHANICALANTI_MISLOCK, 16=DOOROPENUNLOCK, 17=SILENTUNLOCK, 18=BLEENABLEUNLOCK, 19=UWBPEUNLOCK, 0=NOCOMMAND, 1=RKEUNLOCK, 2=POLLINGUNLOCK, 3=NFCUNLOCK, 4=BLEUNLOCK, 5=FOURGUNLOCK, 6=CENTERSWUNLOCK, 7=CDCUSWUNLOCK, 8=PHYSICALUNLOCK, 9=PARKINGUNLOCK, 20=UWBPOLLINGUNLOCK, 21=BLEWATCHUNLOCK}, compu-method=CompuMethod_C_LDCU_DoorUnlockSource, update-indication-bit-position=-1, to RDCU(timeout 0.4 s)
          signal C_LDCU_DoorLockEvent: start 33, 2 bit, big-endian, init-value=0, base-type=uint8, compu {phys=raw for raw 0..3, 0=NOEVENT, 1=LOCK, 2=UNLOCK, 3=RESERVED}, compu-method=CompuMethod_C_LDCU_DoorLockEvent, update-indication-bit-position=-1, to RDCU(timeout 0.4 s)
          signal C_LDCU_ChargeGunCmd: start 55, 2 bit, big-endian, init-value=0, base-type=uint8, compu {phys=raw for raw 0..3, 0=NOCOMMAND, 1=LOCKT, 2=UNLOCK, 3=NOTUSED}, compu-method=CompuMethod_C_LDCU_ChargeGunCmd, update-indication-bit-position=-1, to RDCU(timeout 0.4 s)
          signal C_LDCU_TrunkReleaseSW: start 41, 1 bit, big-endian, init-value=0, base-type=uint8, compu {phys=raw for raw 0..1, 0=NOTPRESSED, 1=PRESSED}, compu-method=CompuMethod_C_LDCU_TrunkReleaseSW, update-indication-bit-position=-1, to RDCU(timeout 0.4 s)
          signal C_LDCU_LockLogicSt: start 40, 1 bit, big-endian, init-value=0, base-type=uint8, compu {phys=raw for raw 0..1, 0=UNLOCK, 1=LOCK}, compu-method=CompuMethod_C_LDCU_LockLogicSt, update-indication-bit-position=-1, to RDCU(timeout 0.4 s)
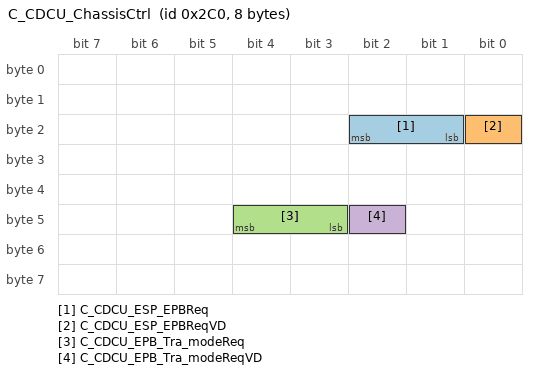
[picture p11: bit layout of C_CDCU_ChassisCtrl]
      frame C_CDCU_ChassisCtrl: id 0x2C0, to RDCU, frame-length=8, can-addressing-mode=STANDARD, can-fd-frame-support=true, can-frame-rx-behavior=CAN-FD
        carries pdu C_CDCU_ChassisCtrl: packing-byte-order=big-endian, start-position=7
        pdu C_CDCU_ChassisCtrl: length=8
          transmission-mode-conditions:
            {data-filter={data-filter-type=ALWAYS, max=3, min=0, offset=0}, i-signal-in-i-pdu=C_CDCU_ESP_EPBReq}
            {data-filter={data-filter-type=ALWAYS, max=1, min=0, offset=0}, i-signal-in-i-pdu=C_CDCU_ESP_EPBReqVD}
            {data-filter={data-filter-type=ALWAYS, max=3, min=0, offset=0}, i-signal-in-i-pdu=C_CDCU_EPB_Tra_modeReq}
            {data-filter={data-filter-type=ALWAYS, max=1, min=0, offset=0}, i-signal-in-i-pdu=C_CDCU_EPB_Tra_modeReqVD}
            {data-filter={data-filter-type=ALWAYS, max=3, min=0, offset=0}, i-signal-in-i-pdu=C_CDCU_ESP_EPBReq}
            {data-filter={data-filter-type=ALWAYS, max=1, min=0, offset=0}, i-signal-in-i-pdu=C_CDCU_ESP_EPBReqVD}
            {data-filter={data-filter-type=ALWAYS, max=3, min=0, offset=0}, i-signal-in-i-pdu=C_CDCU_EPB_Tra_modeReq}
            {data-filter={data-filter-type=ALWAYS, max=1, min=0, offset=0}, i-signal-in-i-pdu=C_CDCU_EPB_Tra_modeReqVD}
          signal C_CDCU_ESP_EPBReq: start 18, 2 bit, big-endian, init-value=0, base-type=uint8, compu {phys=raw for raw 0..3, 0=NOCOMMAND, 1=RELEASE, 2=APPLY, 3=RESERVED}, compu-method=CompuMethod_C_CDCU_ESP_EPBReq, update-indication-bit-position=-1, to RDCU(timeout 1 s)
          signal C_CDCU_ESP_EPBReqVD: start 16, 1 bit, big-endian, init-value=1, base-type=uint8, compu {phys=raw for raw 0..1, 0=NOTVALID, 1=VALID}, compu-method=CompuMethod_C_CDCU_ESP_EPBReqVD, update-indication-bit-position=-1, to RDCU(timeout 1 s)
          signal C_CDCU_EPB_Tra_modeReq: start 44, 2 bit, big-endian, init-value=0, base-type=uint8, compu {phys=raw for raw 0..3, 0=NOCOMMAND, 1=TRAMODE, 2=RESERVED, 3=RESERVED}, compu-method=CompuMethod_C_CDCU_EPB_Tra_modeReq, update-indication-bit-position=-1, to RDCU(timeout 1 s)
          signal C_CDCU_EPB_Tra_modeReqVD: start 42, 1 bit, big-endian, init-value=0, base-type=uint8, compu {phys=raw for raw 0..1, 0=NOTVALID, 1=VALID}, compu-method=CompuMethod_C_CDCU_EPB_Tra_modeReqVD, update-indication-bit-position=-1, to RDCU(timeout 1 s)
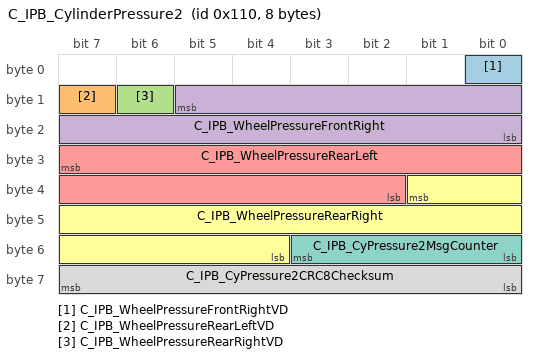
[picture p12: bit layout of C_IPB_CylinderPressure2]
      frame C_IPB_CylinderPressure2: id 0x110, to RDCU, frame-length=8, can-addressing-mode=STANDARD, can-fd-frame-support=true, can-frame-rx-behavior=CAN-FD
        carries pdu C_IPB_CylinderPressure2: packing-byte-order=big-endian, start-position=7
        pdu C_IPB_CylinderPressure2: length=8
          transmission-mode-conditions:
            {data-filter={data-filter-type=ALWAYS, max=1, min=0, offset=0}, i-signal-in-i-pdu=C_IPB_WheelPressureFrontRightVD}
            {data-filter={data-filter-type=ALWAYS, max=1, min=0, offset=0}, i-signal-in-i-pdu=C_IPB_WheelPressureRearLeftVD}
            {data-filter={data-filter-type=ALWAYS, max=1, min=0, offset=0}, i-signal-in-i-pdu=C_IPB_WheelPressureRearRightVD}
            {data-filter={data-filter-type=NEW-IS-WITHIN, max=13440, min=0}, i-signal-in-i-pdu=C_IPB_WheelPressureFrontRight}
            {data-filter={data-filter-type=NEW-IS-WITHIN, max=13440, min=0}, i-signal-in-i-pdu=C_IPB_WheelPressureRearLeft}
            {data-filter={data-filter-type=NEW-IS-WITHIN, max=13440, min=0}, i-signal-in-i-pdu=C_IPB_WheelPressureRearRight}
            {data-filter={data-filter-type=ALWAYS, max=15, min=0, offset=0}, i-signal-in-i-pdu=C_IPB_CyPressure2MsgCounter}
            {data-filter={data-filter-type=ALWAYS, max=255, min=0, offset=0}, i-signal-in-i-pdu=C_IPB_CyPressure2CRC8Checksum}
            {data-filter={data-filter-type=ALWAYS, max=1, min=0, offset=0}, i-signal-in-i-pdu=C_IPB_WheelPressureFrontRightVD}
            {data-filter={data-filter-type=ALWAYS, max=1, min=0, offset=0}, i-signal-in-i-pdu=C_IPB_WheelPressureRearLeftVD}
            {data-filter={data-filter-type=ALWAYS, max=1, min=0, offset=0}, i-signal-in-i-pdu=C_IPB_WheelPressureRearRightVD}
            {data-filter={data-filter-type=NEW-IS-WITHIN, max=13440, min=0}, i-signal-in-i-pdu=C_IPB_WheelPressureFrontRight}
            {data-filter={data-filter-type=NEW-IS-WITHIN, max=13440, min=0}, i-signal-in-i-pdu=C_IPB_WheelPressureRearLeft}
            {data-filter={data-filter-type=NEW-IS-WITHIN, max=13440, min=0}, i-signal-in-i-pdu=C_IPB_WheelPressureRearRight}
            {data-filter={data-filter-type=ALWAYS, max=15, min=0, offset=0}, i-signal-in-i-pdu=C_IPB_CyPressure2MsgCounter}
            {data-filter={data-filter-type=ALWAYS, max=255, min=0, offset=0}, i-signal-in-i-pdu=C_IPB_CyPressure2CRC8Checksum}
          signal C_IPB_WheelPressureFrontRightVD: start 0, 1 bit, big-endian, init-value=0, base-type=uint8, compu {phys=raw for raw 0..1, 0=NOTVALID, 1=VALID}, compu-method=CompuMethod_C_IPB_WheelPressureFrontRightVD, update-indication-bit-position=-1, to RDCU(timeout 0.1 s)
          signal C_IPB_WheelPressureRearLeftVD: start 15, 1 bit, big-endian, init-value=0, base-type=uint8, compu {phys=raw for raw 0..1, 0=NOTVALID, 1=VALID}, compu-method=CompuMethod_C_IPB_WheelPressureRearLeftVD, update-indication-bit-position=-1, to RDCU(timeout 0.1 s)
          signal C_IPB_WheelPressureRearRightVD: start 14, 1 bit, big-endian, init-value=0, base-type=uint8, compu {phys=raw for raw 0..1, 0=NOTVALID, 1=VALID}, compu-method=CompuMethod_C_IPB_WheelPressureRearRightVD, update-indication-bit-position=-1, to RDCU(timeout 0.1 s)
          signal C_IPB_WheelPressureFrontRight: start 13, 14 bit, big-endian, init-value=640, base-type=uint16, compu {raw=phys*32+640 for phys -20..400; unit bar}, compu-method=CompuMethod_C_IPB_WheelPressureFrontRight, update-indication-bit-position=-1, to RDCU(timeout 0.1 s)  # Estimated or modeled wheel pressure of the rIPBective wheel brake. Modeled wheel pressure is needed in case of active hydraulic control"
          signal C_IPB_WheelPressureRearLeft: start 31, 14 bit, big-endian, init-value=640, base-type=uint16, compu {raw=phys*32+640 for phys -20..400; unit bar}, compu-method=CompuMethod_C_IPB_WheelPressureRearLeft, update-indication-bit-position=-1, to RDCU(timeout 0.1 s)  # Estimated or modeled wheel pressure of the rIPBective wheel brake. Modeled wheel pressure is needed in case of active hydraulic control"
          signal C_IPB_WheelPressureRearRight: start 33, 14 bit, big-endian, init-value=640, base-type=uint16, compu {raw=phys*32+640 for phys -20..400; unit bar}, compu-method=CompuMethod_C_IPB_WheelPressureRearRight, update-indication-bit-position=-1, to RDCU(timeout 0.1 s)  # Estimated or modeled wheel pressure of the rIPBective wheel brake. Modeled wheel pressure is needed in case of active hydraulic control"
          signal C_IPB_CyPressure2MsgCounter: start 51, 4 bit, big-endian, init-value=0, base-type=uint8, compu {raw=phys for phys 0..15}, compu-method=CompuMethod_C_IPB_CyPressure2MsgCounter, update-indication-bit-position=-1, to RDCU(timeout 0.1 s)  # The MessageCounter is a 0 _15 counter, increased of one unit on every message transmission"
          signal C_IPB_CyPressure2CRC8Checksum: start 63, 8 bit, big-endian, init-value=0, base-type=uint8, compu {raw=phys for phys 0..255}, compu-method=CompuMethod_C_IPB_CyPressure2CRC8Checksum, update-indication-bit-position=-1, to RDCU(timeout 0.1 s)  # CRC8"
      frame C_IPB_SysSt: id 0x1A7, to RDCU, frame-length=8, can-addressing-mode=STANDARD, can-fd-frame-support=true, can-frame-rx-behavior=CAN-FD  # IDS"
        carries pdu C_IPB_SysSt: packing-byte-order=big-endian, start-position=7
        pdu C_IPB_SysSt: length=8  # IDS
          transmission-mode-conditions:
            {data-filter={data-filter-type=ALWAYS, max=1, min=0, offset=0}, i-signal-in-i-pdu=C_IPB_ABSFault}
            {data-filter={data-filter-type=ALWAYS, max=1, min=0, offset=0}, i-signal-in-i-pdu=C_IPB_ABSActSt}
            {data-filter={data-filter-type=ALWAYS, max=1, min=0, offset=0}, i-signal-in-i-pdu=C_IPB_EBDFault}
            {data-filter={data-filter-type=ALWAYS, max=1, min=0, offset=0}, i-signal-in-i-pdu=C_IPB_EBDActSt}
            {data-filter={data-filter-type=ALWAYS, max=1, min=0, offset=0}, i-signal-in-i-pdu=C_IPB_VDCActSt}
            {data-filter={data-filter-type=ALWAYS, max=3, min=0, offset=0}, i-signal-in-i-pdu=C_IPB_XPedalAVHActSt}
            {data-filter={data-filter-type=ALWAYS, max=1, min=0, offset=0}, i-signal-in-i-pdu=C_IPB_BrkLightOnReq}
            {data-filter={data-filter-type=ALWAYS, max=1, min=0, offset=0}, i-signal-in-i-pdu=C_IPB_TCSActSt}
            {data-filter={data-filter-type=ALWAYS, max=1, min=0, offset=0}, i-signal-in-i-pdu=C_IPB_HHCFault}
            {data-filter={data-filter-type=ALWAYS, max=1, min=0, offset=0}, i-signal-in-i-pdu=C_IPB_HHCActSt}
            {data-filter={data-filter-type=ALWAYS, max=1, min=0, offset=0}, i-signal-in-i-pdu=C_IPB_AVHFault}
            {data-filter={data-filter-type=ALWAYS, max=1, min=0, offset=0}, i-signal-in-i-pdu=C_IPB_EBAAct}
            {data-filter={data-filter-type=ALWAYS, max=3, min=0, offset=0}, i-signal-in-i-pdu=C_IPB_AVHActSt}
            {data-filter={data-filter-type=ALWAYS, max=1, min=0, offset=0}, i-signal-in-i-pdu=C_IPB_HpsAcknowledge}
            {data-filter={data-filter-type=ALWAYS, max=1, min=0, offset=0}, i-signal-in-i-pdu=C_IPB_HpsAvailability}
            {data-filter={data-filter-type=ALWAYS, max=3, min=0, offset=0}, i-signal-in-i-pdu=C_IPB_ESPPATA}
            {data-filter={data-filter-type=ALWAYS, max=1, min=0, offset=0}, i-signal-in-i-pdu=C_IPB_ESPFault}
            {data-filter={data-filter-type=ALWAYS, max=1, min=0, offset=0}, i-signal-in-i-pdu=C_IPB_CDPAvl}
            {data-filter={data-filter-type=ALWAYS, max=1, min=0, offset=0}, i-signal-in-i-pdu=C_IPB_CDPIntervention}
            {data-filter={data-filter-type=ALWAYS, max=1, min=0, offset=0}, i-signal-in-i-pdu=C_IPB_AEBAvl}
            {data-filter={data-filter-type=ALWAYS, max=1, min=0, offset=0}, i-signal-in-i-pdu=C_IPB_AEBAct}
            {data-filter={data-filter-type=ALWAYS, max=1, min=0, offset=0}, i-signal-in-i-pdu=C_IPB_CddSt}
            {data-filter={data-filter-type=ALWAYS, max=1, min=0, offset=0}, i-signal-in-i-pdu=C_IPB_CddAvl}
            {data-filter={data-filter-type=ALWAYS, max=3, min=0, offset=0}, i-signal-in-i-pdu=C_IPB_StandStillSt}
            {data-filter={data-filter-type=ALWAYS, max=1, min=0, offset=0}, i-signal-in-i-pdu=C_IPB_ABAAvl}
            {data-filter={data-filter-type=ALWAYS, max=1, min=0, offset=0}, i-signal-in-i-pdu=C_IPB_ABAAct}
            {data-filter={data-filter-type=ALWAYS, max=1, min=0, offset=0}, i-signal-in-i-pdu=C_IPB_ABPAvl}
            {data-filter={data-filter-type=ALWAYS, max=1, min=0, offset=0}, i-signal-in-i-pdu=C_IPB_ABPAct}
            {data-filter={data-filter-type=ALWAYS, max=1, min=0, offset=0}, i-signal-in-i-pdu=C_IPB_AWBAvl}
            {data-filter={data-filter-type=ALWAYS, max=1, min=0, offset=0}, i-signal-in-i-pdu=C_IPB_AWBAct}
            {data-filter={data-filter-type=ALWAYS, max=1, min=0, offset=0}, i-signal-in-i-pdu=C_IPB_CDDBrkTempOff}
            {data-filter={data-filter-type=ALWAYS, max=1, min=0, offset=0}, i-signal-in-i-pdu=C_IPB_CDDFaultSt}
            {data-filter={data-filter-type=ALWAYS, max=1, min=0, offset=0}, i-signal-in-i-pdu=C_IPB_BrkPedalSt}
            {data-filter={data-filter-type=ALWAYS, max=1, min=0, offset=0}, i-signal-in-i-pdu=C_IPB_BrkPedalStVD}
            {data-filter={data-filter-type=ALWAYS, max=1, min=0, offset=0}, i-signal-in-i-pdu=C_IPB_EmerLightReq}
            {data-filter={data-filter-type=ALWAYS, max=1, min=0, offset=0}, i-signal-in-i-pdu=C_IPB_DTCActSt}
            {data-filter={data-filter-type=ALWAYS, max=1, min=0, offset=0}, i-signal-in-i-pdu=C_IPB_DTCFault}
            {data-filter={data-filter-type=ALWAYS, max=1, min=0, offset=0}, i-signal-in-i-pdu=C_IPB_SCMSt}
            {data-filter={data-filter-type=ALWAYS, max=1, min=0, offset=0}, i-signal-in-i-pdu=C_IPB_SCMFault}
            {data-filter={data-filter-type=ALWAYS, max=1, min=0, offset=0}, i-signal-in-i-pdu=C_IPB_EBAAvl}
            {data-filter={data-filter-type=ALWAYS, max=15, min=0, offset=0}, i-signal-in-i-pdu=C_IPB_SysStMsgCounter}
            {data-filter={data-filter-type=ALWAYS, max=255, min=0, offset=0}, i-signal-in-i-pdu=C_IPB_SysStCRC8Checksum}
            {data-filter={data-filter-type=ALWAYS, max=1, min=0, offset=0}, i-signal-in-i-pdu=C_IPB_ABSFault}
            {data-filter={data-filter-type=ALWAYS, max=1, min=0, offset=0}, i-signal-in-i-pdu=C_IPB_ABSActSt}
            {data-filter={data-filter-type=ALWAYS, max=1, min=0, offset=0}, i-signal-in-i-pdu=C_IPB_EBDFault}
            {data-filter={data-filter-type=ALWAYS, max=1, min=0, offset=0}, i-signal-in-i-pdu=C_IPB_EBDActSt}
            {data-filter={data-filter-type=ALWAYS, max=1, min=0, offset=0}, i-signal-in-i-pdu=C_IPB_VDCActSt}
            {data-filter={data-filter-type=ALWAYS, max=3, min=0, offset=0}, i-signal-in-i-pdu=C_IPB_XPedalAVHActSt}
            {data-filter={data-filter-type=ALWAYS, max=1, min=0, offset=0}, i-signal-in-i-pdu=C_IPB_BrkLightOnReq}
            {data-filter={data-filter-type=ALWAYS, max=1, min=0, offset=0}, i-signal-in-i-pdu=C_IPB_TCSActSt}
            {data-filter={data-filter-type=ALWAYS, max=1, min=0, offset=0}, i-signal-in-i-pdu=C_IPB_HHCFault}
            {data-filter={data-filter-type=ALWAYS, max=1, min=0, offset=0}, i-signal-in-i-pdu=C_IPB_HHCActSt}
            {data-filter={data-filter-type=ALWAYS, max=1, min=0, offset=0}, i-signal-in-i-pdu=C_IPB_AVHFault}
            {data-filter={data-filter-type=ALWAYS, max=1, min=0, offset=0}, i-signal-in-i-pdu=C_IPB_EBAAct}
            {data-filter={data-filter-type=ALWAYS, max=3, min=0, offset=0}, i-signal-in-i-pdu=C_IPB_AVHActSt}
            {data-filter={data-filter-type=ALWAYS, max=1, min=0, offset=0}, i-signal-in-i-pdu=C_IPB_HpsAcknowledge}
            {data-filter={data-filter-type=ALWAYS, max=1, min=0, offset=0}, i-signal-in-i-pdu=C_IPB_HpsAvailability}
            {data-filter={data-filter-type=ALWAYS, max=3, min=0, offset=0}, i-signal-in-i-pdu=C_IPB_ESPPATA}
            {data-filter={data-filter-type=ALWAYS, max=1, min=0, offset=0}, i-signal-in-i-pdu=C_IPB_ESPFault}
            {data-filter={data-filter-type=ALWAYS, max=1, min=0, offset=0}, i-signal-in-i-pdu=C_IPB_CDPAvl}
            {data-filter={data-filter-type=ALWAYS, max=1, min=0, offset=0}, i-signal-in-i-pdu=C_IPB_CDPIntervention}
            {data-filter={data-filter-type=ALWAYS, max=1, min=0, offset=0}, i-signal-in-i-pdu=C_IPB_AEBAvl}
            {data-filter={data-filter-type=ALWAYS, max=1, min=0, offset=0}, i-signal-in-i-pdu=C_IPB_AEBAct}
            {data-filter={data-filter-type=ALWAYS, max=1, min=0, offset=0}, i-signal-in-i-pdu=C_IPB_CddSt}
            {data-filter={data-filter-type=ALWAYS, max=1, min=0, offset=0}, i-signal-in-i-pdu=C_IPB_CddAvl}
            {data-filter={data-filter-type=ALWAYS, max=3, min=0, offset=0}, i-signal-in-i-pdu=C_IPB_StandStillSt}
            {data-filter={data-filter-type=ALWAYS, max=1, min=0, offset=0}, i-signal-in-i-pdu=C_IPB_ABAAvl}
            {data-filter={data-filter-type=ALWAYS, max=1, min=0, offset=0}, i-signal-in-i-pdu=C_IPB_ABAAct}
            {data-filter={data-filter-type=ALWAYS, max=1, min=0, offset=0}, i-signal-in-i-pdu=C_IPB_ABPAvl}
            {data-filter={data-filter-type=ALWAYS, max=1, min=0, offset=0}, i-signal-in-i-pdu=C_IPB_ABPAct}
            {data-filter={data-filter-type=ALWAYS, max=1, min=0, offset=0}, i-signal-in-i-pdu=C_IPB_AWBAvl}
            {data-filter={data-filter-type=ALWAYS, max=1, min=0, offset=0}, i-signal-in-i-pdu=C_IPB_AWBAct}
            {data-filter={data-filter-type=ALWAYS, max=1, min=0, offset=0}, i-signal-in-i-pdu=C_IPB_CDDBrkTempOff}
            {data-filter={data-filter-type=ALWAYS, max=1, min=0, offset=0}, i-signal-in-i-pdu=C_IPB_CDDFaultSt}
            {data-filter={data-filter-type=ALWAYS, max=1, min=0, offset=0}, i-signal-in-i-pdu=C_IPB_BrkPedalSt}
            {data-filter={data-filter-type=ALWAYS, max=1, min=0, offset=0}, i-signal-in-i-pdu=C_IPB_BrkPedalStVD}
            {data-filter={data-filter-type=ALWAYS, max=1, min=0, offset=0}, i-signal-in-i-pdu=C_IPB_EmerLightReq}
            {data-filter={data-filter-type=ALWAYS, max=1, min=0, offset=0}, i-signal-in-i-pdu=C_IPB_DTCActSt}
            {data-filter={data-filter-type=ALWAYS, max=1, min=0, offset=0}, i-signal-in-i-pdu=C_IPB_DTCFault}
            {data-filter={data-filter-type=ALWAYS, max=1, min=0, offset=0}, i-signal-in-i-pdu=C_IPB_SCMSt}
            {data-filter={data-filter-type=ALWAYS, max=1, min=0, offset=0}, i-signal-in-i-pdu=C_IPB_SCMFault}
            {data-filter={data-filter-type=ALWAYS, max=1, min=0, offset=0}, i-signal-in-i-pdu=C_IPB_EBAAvl}
            {data-filter={data-filter-type=ALWAYS, max=15, min=0, offset=0}, i-signal-in-i-pdu=C_IPB_SysStMsgCounter}
            {data-filter={data-filter-type=ALWAYS, max=255, min=0, offset=0}, i-signal-in-i-pdu=C_IPB_SysStCRC8Checksum}
          signal C_IPB_ABSFault: start 7, 1 bit, big-endian, init-value=1, base-type=uint8, compu {phys=raw for raw 0..1, 0=NOTFAULT, 1=FAULT}, compu-method=CompuMethod_C_IPB_ABSFault, update-indication-bit-position=-1, to RDCU(timeout 0.2 s)  # ABS system has detected a failure which does no allow a reliable ABS regulation and is therefore switched off"
          signal C_IPB_ABSActSt: start 6, 1 bit, big-endian, init-value=0, base-type=uint8, compu {phys=raw for raw 0..1, 0=NOTACTIVE, 1=ACTIVE}, compu-method=CompuMethod_C_IPB_ABSActSt, update-indication-bit-position=-1, to RDCU(timeout 0.2 s)  # Indication that ABS system currently performs a brake intervention"
          signal C_IPB_EBDFault: start 5, 1 bit, big-endian, init-value=1, base-type=uint8, compu {phys=raw for raw 0..1, 0=NOTFAULT, 1=FAULT}, compu-method=CompuMethod_C_IPB_EBDFault, update-indication-bit-position=-1, to RDCU(timeout 0.2 s)  # EBD system has detected a heavy fault, which does not even allow a reliable electronic brake distribution and is therefore completely shut down"
          signal C_IPB_EBDActSt: start 4, 1 bit, big-endian, init-value=1, base-type=uint8, compu {phys=raw for raw 0..1, 0=NOTACTIVE, 1=ACTIVE}, compu-method=CompuMethod_C_IPB_EBDActSt, update-indication-bit-position=-1, to RDCU(timeout 0.2 s)  # Indication that EBD system currently performs a brakeorengine intervention"
          signal C_IPB_VDCActSt: start 3, 1 bit, big-endian, init-value=0, base-type=uint8, compu {phys=raw for raw 0..1, 0=NOTACTIVE, 1=ACTIVE}, compu-method=CompuMethod_C_IPB_VDCActSt, update-indication-bit-position=-1, to RDCU(timeout 0.2 s)  # Indicates VDC in active or not"
          signal C_IPB_XPedalAVHActSt: start 2, 2 bit, big-endian, init-value=0, base-type=uint8, compu {phys=raw for raw 0..3, 0=NOTACTIVE, 1=HOLDING, 2=ACTIVE, 3=NOTAVAILABLE}, compu-method=CompuMethod_C_IPB_XPedalAVHActSt, update-indication-bit-position=-1, to RDCU(timeout 0.2 s)
          signal C_IPB_BrkLightOnReq: start 0, 1 bit, big-endian, init-value=0, base-type=uint8, compu {phys=raw for raw 0..1, 0=OFF, 1=ON}, compu-method=CompuMethod_C_IPB_BrkLightOnReq, update-indication-bit-position=-1, to RDCU(timeout 0.2 s)  # Request to ignite the brake light"
          signal C_IPB_TCSActSt: start 15, 1 bit, big-endian, init-value=0, base-type=uint8, compu {phys=raw for raw 0..1, 0=NOTACTIVE, 1=ACTIVE}, compu-method=CompuMethod_C_IPB_TCSActSt, update-indication-bit-position=-1, to RDCU(timeout 0.2 s)  # Indicates TCS in active or not"
          signal C_IPB_HHCFault: start 13, 1 bit, big-endian, init-value=1, base-type=uint8, compu {phys=raw for raw 0..1, 0=NOTFAULT, 1=FAULT}, compu-method=CompuMethod_C_IPB_HHCFault, update-indication-bit-position=-1, to RDCU(timeout 0.2 s)  # HHC(Hill Hold Control) error status"
          signal C_IPB_HHCActSt: start 12, 1 bit, big-endian, init-value=0, base-type=uint8, compu {phys=raw for raw 0..1, 0=NOTACTIVE, 1=ACTIVE}, compu-method=CompuMethod_C_IPB_HHCActSt, update-indication-bit-position=-1, to RDCU(timeout 0.2 s)  # HHC(Hill Hold Control) control status"
          signal C_IPB_AVHFault: start 23, 1 bit, big-endian, init-value=1, base-type=uint8, compu {phys=raw for raw 0..1, 0=NOTFAULT, 1=FAULT}, compu-method=CompuMethod_C_IPB_AVHFault, update-indication-bit-position=-1, to RDCU(timeout 0.2 s)  # HMI rESPonsible, can get degrate AVH(Auto Vehicle Hold) statement from DSW and send out"
          signal C_IPB_EBAAct: start 20, 1 bit, big-endian, init-value=0, base-type=uint8, compu {phys=raw for raw 0..1, 0=NOTACTIVE, 1=ACTIVE}, compu-method=CompuMethod_C_IPB_EBAAct, update-indication-bit-position=-1, to RDCU(timeout 0.2 s)  # indicates EBA is active or not"
          signal C_IPB_AVHActSt: start 22, 2 bit, big-endian, init-value=0, base-type=uint8, compu {phys=raw for raw 0..3, 0=NOTACTIVE, 1=STANDBY, 2=ACTIVE, 3=RESERVED}, compu-method=CompuMethod_C_IPB_AVHActSt, update-indication-bit-position=-1, to RDCU(timeout 0.2 s)  # Indicates AVH current status,including not active,standby,active"
          signal C_IPB_HpsAcknowledge: start 10, 1 bit, big-endian, init-value=0, base-type=uint8, compu {phys=raw for raw 0..1, 0=NOTACKNOWLEDGED, 1=ACKNOWLEDGED}, compu-method=CompuMethod_C_IPB_HpsAcknowledge, update-indication-bit-position=-1, to RDCU(timeout 0.2 s)  # Confirmation that hydraulic pressure support (HPS) is achieved by the hydraulics"
          signal C_IPB_HpsAvailability: start 11, 1 bit, big-endian, init-value=0, base-type=uint8, compu {phys=raw for raw 0..1, 0=NOTAVAILABLE, 1=AVAILABLE}, compu-method=CompuMethod_C_IPB_HpsAvailability, update-indication-bit-position=-1, to RDCU(timeout 0.2 s)  # Availability of hydraulic pressure support (HPS)"
          signal C_IPB_ESPPATA: start 19, 2 bit, big-endian, init-value=2, base-type=uint8, compu {phys=raw for raw 0..3, 0=NORMAL, 1=SPORT, 2=OFF, 3=RESERVED}, compu-method=CompuMethod_C_IPB_ESPPATA, update-indication-bit-position=-1, to RDCU(timeout 0.2 s)  # indicate PATA pressed,when ESP function is deactivated£¬ESP_ESPPATA=0x2:Off, when ESP function is in Sport Mode ESP_ESPPATA=0x1:sport;"
          signal C_IPB_ESPFault: start 17, 1 bit, big-endian, init-value=1, base-type=uint8, compu {phys=raw for raw 0..1, 0=NOTFAULT, 1=FAULT}, compu-method=CompuMethod_C_IPB_ESPFault, update-indication-bit-position=-1, to RDCU(timeout 0.2 s)  # indicate TCS/VDC/DTC is fault"
          signal C_IPB_CDPAvl: start 16, 1 bit, big-endian, init-value=0, base-type=uint8, compu {phys=raw for raw 0..1, 0=NOTAVAILABLE, 1=AVAILABLE}, compu-method=CompuMethod_C_IPB_CDPAvl, update-indication-bit-position=-1, to RDCU(timeout 0.2 s)  # CDP(Controlled Deceleration for Parking brake) interface available"
          signal C_IPB_CDPIntervention: start 31, 1 bit, big-endian, init-value=0, base-type=uint8, compu {phys=raw for raw 0..1, 0=NOTINTERVENTION, 1=INTERVENTION}, compu-method=CompuMethod_C_IPB_CDPIntervention, update-indication-bit-position=-1, to RDCU(timeout 0.2 s)  # CDP(Controlled Deceleration for Parking brake) intervention"
          signal C_IPB_AEBAvl: start 29, 1 bit, big-endian, init-value=0, base-type=uint8, compu {phys=raw for raw 0..1, 0=NOTAVAILABLE, 1=AVAILABLE}, compu-method=CompuMethod_C_IPB_AEBAvl, update-indication-bit-position=-1, to RDCU(timeout 0.2 s)  # indicates AEB is available or not"
          signal C_IPB_AEBAct: start 28, 1 bit, big-endian, init-value=0, base-type=uint8, compu {phys=raw for raw 0..1, 0=NOTACTIVE, 1=ACTIVE}, compu-method=CompuMethod_C_IPB_AEBAct, update-indication-bit-position=-1, to RDCU(timeout 0.2 s)  # indicates AEB is active or not"
          signal C_IPB_CddSt: start 27, 1 bit, big-endian, init-value=0, base-type=uint8, compu {phys=raw for raw 0..1, 0=NOTACTIVE, 1=ACTIVE}, compu-method=CompuMethod_C_IPB_CddSt, update-indication-bit-position=-1, to RDCU(timeout 0.2 s)  # indicates CDD is active or not"
          signal C_IPB_CddAvl: start 26, 1 bit, big-endian, init-value=0, base-type=uint8, compu {phys=raw for raw 0..1, 0=NOTAVAILABLE, 1=AVAILABLE}, compu-method=CompuMethod_C_IPB_CddAvl, update-indication-bit-position=-1, to RDCU(timeout 0.2 s)  # indicates CDD is available or not"
          signal C_IPB_StandStillSt: start 25, 2 bit, big-endian, init-value=0, base-type=uint8, compu {phys=raw for raw 0..3, 0=NOTSTANDSTILL, 1=STANDSTILL, 2=INVALID, 3=RESERVED}, compu-method=CompuMethod_C_IPB_StandStillSt, update-indication-bit-position=-1, to RDCU(timeout 0.2 s)  # ndicates if CDD-S can hold the vehicle in standstill"
          signal C_IPB_ABAAvl: start 39, 1 bit, big-endian, init-value=0, base-type=uint8, compu {phys=raw for raw 0..1, 0=NOTAVAILABLE, 1=AVAILABLE}, compu-method=CompuMethod_C_IPB_ABAAvl, update-indication-bit-position=-1, to RDCU(timeout 0.2 s)  # indicates ABA is available or not"
          signal C_IPB_ABAAct: start 38, 1 bit, big-endian, init-value=0, base-type=uint8, compu {phys=raw for raw 0..1, 0=NOTACTIVE, 1=ACTIVE}, compu-method=CompuMethod_C_IPB_ABAAct, update-indication-bit-position=-1, to RDCU(timeout 0.2 s)  # indicates ABA is active or not"
          signal C_IPB_ABPAvl: start 37, 1 bit, big-endian, init-value=0, base-type=uint8, compu {phys=raw for raw 0..1, 0=NOTAVAILABLE, 1=AVAILABLE}, compu-method=CompuMethod_C_IPB_ABPAvl, update-indication-bit-position=-1, to RDCU(timeout 0.2 s)  # indicates ABP is available or not"
          signal C_IPB_ABPAct: start 36, 1 bit, big-endian, init-value=0, base-type=uint8, compu {phys=raw for raw 0..1, 0=NOTACTIVE, 1=ACTIVE}, compu-method=CompuMethod_C_IPB_ABPAct, update-indication-bit-position=-1, to RDCU(timeout 0.2 s)  # indicates ABP is active or not"
          signal C_IPB_AWBAvl: start 35, 1 bit, big-endian, init-value=0, base-type=uint8, compu {phys=raw for raw 0..1, 0=NOTAVAILABLE, 1=AVAILABLE}, compu-method=CompuMethod_C_IPB_AWBAvl, update-indication-bit-position=-1, to RDCU(timeout 0.2 s)  # indicates AWB is available or not"
          signal C_IPB_AWBAct: start 34, 1 bit, big-endian, init-value=0, base-type=uint8, compu {phys=raw for raw 0..1, 0=NOTACTIVE, 1=ACTIVE}, compu-method=CompuMethod_C_IPB_AWBAct, update-indication-bit-position=-1, to RDCU(timeout 0.2 s)  # indicates AWB is active or not"
          signal C_IPB_CDDBrkTempOff: start 33, 1 bit, big-endian, init-value=0, base-type=uint8, compu {phys=raw for raw 0..1, 0=NOTTOOHIGH, 1=TEMPERATURETOOHIGH}, compu-method=CompuMethod_C_IPB_CDDBrkTempOff, update-indication-bit-position=-1, to RDCU(timeout 0.2 s)  # Indicating brake temperature too high or not"
          signal C_IPB_CDDFaultSt: start 32, 1 bit, big-endian, init-value=1, base-type=uint8, compu {phys=raw for raw 0..1, 0=NOTFAULT, 1=FAULT}, compu-method=CompuMethod_C_IPB_CDDFaultSt, update-indication-bit-position=-1, to RDCU(timeout 0.2 s)  # indicates CDD error"
          signal C_IPB_BrkPedalSt: start 54, 1 bit, big-endian, init-value=0, base-type=uint8, compu {phys=raw for raw 0..1, 0=NOTPRESSED, 1=PRESSED}, compu-method=CompuMethod_C_IPB_BrkPedalSt, update-indication-bit-position=-1, to RDCU(timeout 0.2 s)
          signal C_IPB_BrkPedalStVD: start 53, 1 bit, big-endian, init-value=0, base-type=uint8, compu {phys=raw for raw 0..1, 0=NOTVALID, 1=VALID}, compu-method=CompuMethod_C_IPB_BrkPedalStVD, update-indication-bit-position=-1, to RDCU(timeout 0.2 s)
          signal C_IPB_EmerLightReq: start 52, 1 bit, big-endian, init-value=0, base-type=uint8, compu {phys=raw for raw 0..1, 0=OFF, 1=ON}, compu-method=CompuMethod_C_IPB_EmerLightReq, update-indication-bit-position=-1, to RDCU(timeout 0.2 s)
          signal C_IPB_DTCActSt: start 47, 1 bit, big-endian, init-value=0, base-type=uint8, compu {phys=raw for raw 0..1, 0=NOTACTIVE, 1=ACTIVE}, compu-method=CompuMethod_C_IPB_DTCActSt, update-indication-bit-position=-1, to RDCU(timeout 0.2 s)
          signal C_IPB_DTCFault: start 46, 1 bit, big-endian, init-value=1, base-type=uint8, compu {phys=raw for raw 0..1, 0=NOTFAULT, 1=FAULT}, compu-method=CompuMethod_C_IPB_DTCFault, update-indication-bit-position=-1, to RDCU(timeout 0.2 s)
          signal C_IPB_SCMSt: start 45, 1 bit, big-endian, init-value=0, base-type=uint8, compu {phys=raw for raw 0..1, 0=NOTACTIVE, 1=ACTIVE}, compu-method=CompuMethod_C_IPB_SCMSt, update-indication-bit-position=-1, to RDCU(timeout 0.2 s)  # Indicates SCM in active or not"
          signal C_IPB_SCMFault: start 44, 1 bit, big-endian, init-value=0, base-type=uint8, compu {phys=raw for raw 0..1, 0=NOTAVAILABLE, 1=AVAILABLE}, compu-method=CompuMethod_C_IPB_SCMFault, update-indication-bit-position=-1, to RDCU(timeout 0.2 s)  # HMI Responsible,CAN get degrateAVH statement from DSW and send out"
          signal C_IPB_EBAAvl: start 43, 1 bit, big-endian, init-value=0, base-type=uint8, compu {phys=raw for raw 0..1, 0=NOTAVAILABLE, 1=AVAILABLE}, compu-method=CompuMethod_C_IPB_EBAAvl, update-indication-bit-position=-1, to RDCU(timeout 0.2 s)  # Indicates EBA is available or not"
          signal C_IPB_SysStMsgCounter: start 51, 4 bit, big-endian, init-value=0, base-type=uint8, compu {raw=phys for phys 0..15}, compu-method=CompuMethod_C_IPB_SysStMsgCounter, update-indication-bit-position=-1, to RDCU(timeout 0.2 s)  # The MessageCounter is a 0 ~ 15 counter, increased of one unit on every message transmission"
          signal C_IPB_SysStCRC8Checksum: start 63, 8 bit, big-endian, init-value=0, base-type=uint8, compu {raw=phys for phys 0..255}, compu-method=CompuMethod_C_IPB_SysStCRC8Checksum, update-indication-bit-position=-1, to RDCU(timeout 0.2 s)  # CRC8"
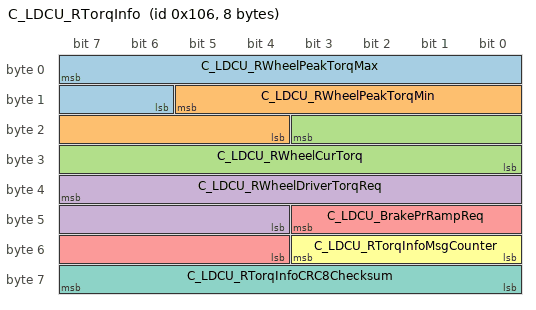
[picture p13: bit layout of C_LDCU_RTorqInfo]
      frame C_LDCU_RTorqInfo: id 0x106, to RDCU, frame-length=8, can-addressing-mode=STANDARD, can-fd-frame-support=true, can-frame-rx-behavior=CAN-FD
        carries pdu C_LDCU_RTorqInfo: packing-byte-order=big-endian, start-position=7
        pdu C_LDCU_RTorqInfo: length=8
          transmission-mode-conditions:
            {data-filter={data-filter-type=NEW-IS-WITHIN, max=1000, min=0, offset=0}, i-signal-in-i-pdu=C_LDCU_RWheelPeakTorqMax}
            {data-filter={data-filter-type=NEW-IS-WITHIN, max=875, min=0}, i-signal-in-i-pdu=C_LDCU_RWheelPeakTorqMin}
            {data-filter={data-filter-type=NEW-IS-WITHIN, max=3000, min=0}, i-signal-in-i-pdu=C_LDCU_RWheelCurTorq}
            {data-filter={data-filter-type=NEW-IS-WITHIN, max=3000, min=0}, i-signal-in-i-pdu=C_LDCU_RWheelDriverTorqReq}
            {data-filter={data-filter-type=ALWAYS, max=250, min=0, offset=0}, i-signal-in-i-pdu=C_LDCU_BrakePrRampReq}
            {data-filter={data-filter-type=ALWAYS, max=15, min=0, offset=0}, i-signal-in-i-pdu=C_LDCU_RTorqInfoMsgCounter}
            {data-filter={data-filter-type=ALWAYS, max=255, min=0, offset=0}, i-signal-in-i-pdu=C_LDCU_RTorqInfoCRC8Checksum}
            {data-filter={data-filter-type=NEW-IS-WITHIN, max=1000, min=0, offset=0}, i-signal-in-i-pdu=C_LDCU_RWheelPeakTorqMax}
            {data-filter={data-filter-type=NEW-IS-WITHIN, max=875, min=0}, i-signal-in-i-pdu=C_LDCU_RWheelPeakTorqMin}
            {data-filter={data-filter-type=NEW-IS-WITHIN, max=3000, min=0}, i-signal-in-i-pdu=C_LDCU_RWheelCurTorq}
            {data-filter={data-filter-type=NEW-IS-WITHIN, max=3000, min=0}, i-signal-in-i-pdu=C_LDCU_RWheelDriverTorqReq}
            {data-filter={data-filter-type=ALWAYS, max=250, min=0, offset=0}, i-signal-in-i-pdu=C_LDCU_BrakePrRampReq}
            {data-filter={data-filter-type=ALWAYS, max=15, min=0, offset=0}, i-signal-in-i-pdu=C_LDCU_RTorqInfoMsgCounter}
            {data-filter={data-filter-type=ALWAYS, max=255, min=0, offset=0}, i-signal-in-i-pdu=C_LDCU_RTorqInfoCRC8Checksum}
          signal C_LDCU_RWheelPeakTorqMax: start 7, 10 bit, big-endian, init-value=0, base-type=uint16, compu {raw=phys*0.2 for phys 0..5000; unit Nm}, compu-method=CompuMethod_C_LDCU_RWheelPeakTorqMax, update-indication-bit-position=-1, to RDCU(timeout 0.1 s)
          signal C_LDCU_RWheelPeakTorqMin: start 13, 10 bit, big-endian, init-value=875, base-type=uint16, compu {raw=phys*0.25+875 for phys -3500..0; unit Nm}, compu-method=CompuMethod_C_LDCU_RWheelPeakTorqMin, update-indication-bit-position=-1, to RDCU(timeout 0.1 s)
          signal C_LDCU_RWheelCurTorq: start 19, 12 bit, big-endian, init-value=1500, base-type=uint16, compu {raw=phys*0.25+1500 for phys -6000..6000; unit Nm}, compu-method=CompuMethod_C_LDCU_RWheelCurTorq, update-indication-bit-position=-1, to RDCU(timeout 0.1 s)  # 0x0~0xBB8:valid value 0xBB9~FFF:invalid valve Motor Current torque"
          signal C_LDCU_RWheelDriverTorqReq: start 39, 12 bit, big-endian, init-value=1500, base-type=uint16, compu {raw=phys*0.25+1500 for phys -6000..6000; unit Nm}, compu-method=CompuMethod_C_LDCU_RWheelDriverTorqReq, update-indication-bit-position=-1, to RDCU(timeout 0.1 s)  # 0x0~0xBB8:valid value 0xBB9~FFF:invalid valve Driver Request Motor torque"
          signal C_LDCU_BrakePrRampReq: start 43, 8 bit, big-endian, init-value=0, base-type=uint8, compu {raw=phys*0.25 for phys 0..1000; unit barps}, compu-method=CompuMethod_C_LDCU_BrakePrRampReq, update-indication-bit-position=-1, to RDCU(timeout 0.1 s)  # Pressure Ramp Request"
          signal C_LDCU_RTorqInfoMsgCounter: start 51, 4 bit, big-endian, init-value=0, base-type=uint8, compu {raw=phys for phys 0..15}, compu-method=CompuMethod_C_LDCU_RTorqInfoMsgCounter, update-indication-bit-position=-1, to RDCU(timeout 0.1 s)  # The MessageCounter is a 0 ~ 15 counter, increased of one unit on every message transmission"
          signal C_LDCU_RTorqInfoCRC8Checksum: start 63, 8 bit, big-endian, init-value=0, base-type=uint8, compu {raw=phys for phys 0..255}, compu-method=CompuMethod_C_LDCU_RTorqInfoCRC8Checksum, update-indication-bit-position=-1, to RDCU(timeout 0.1 s)  # CRC8"
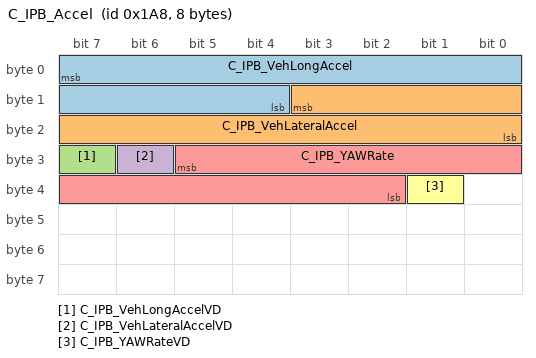
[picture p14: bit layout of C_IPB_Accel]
      frame C_IPB_Accel: id 0x1A8, to RDCU, frame-length=8, can-addressing-mode=STANDARD, can-fd-frame-support=true, can-frame-rx-behavior=CAN-FD
        carries pdu C_IPB_Accel: packing-byte-order=big-endian, start-position=7
        pdu C_IPB_Accel: length=8
          transmission-mode-conditions:
            {data-filter={data-filter-type=NEW-IS-WITHIN, max=1250, min=0}, i-signal-in-i-pdu=C_IPB_VehLongAccel}
            {data-filter={data-filter-type=NEW-IS-WITHIN, max=1250, min=0}, i-signal-in-i-pdu=C_IPB_VehLateralAccel}
            {data-filter={data-filter-type=ALWAYS, max=1, min=0, offset=0}, i-signal-in-i-pdu=C_IPB_VehLongAccelVD}
            {data-filter={data-filter-type=ALWAYS, max=1, min=0, offset=0}, i-signal-in-i-pdu=C_IPB_VehLateralAccelVD}
            {data-filter={data-filter-type=NEW-IS-WITHIN, max=2976, min=0}, i-signal-in-i-pdu=C_IPB_YAWRate}
            {data-filter={data-filter-type=ALWAYS, max=1, min=0, offset=0}, i-signal-in-i-pdu=C_IPB_YAWRateVD}
            {data-filter={data-filter-type=NEW-IS-WITHIN, max=1250, min=0}, i-signal-in-i-pdu=C_IPB_VehLongAccel}
            {data-filter={data-filter-type=NEW-IS-WITHIN, max=1250, min=0}, i-signal-in-i-pdu=C_IPB_VehLateralAccel}
            {data-filter={data-filter-type=ALWAYS, max=1, min=0, offset=0}, i-signal-in-i-pdu=C_IPB_VehLongAccelVD}
            {data-filter={data-filter-type=ALWAYS, max=1, min=0, offset=0}, i-signal-in-i-pdu=C_IPB_VehLateralAccelVD}
            {data-filter={data-filter-type=NEW-IS-WITHIN, max=2976, min=0}, i-signal-in-i-pdu=C_IPB_YAWRate}
            {data-filter={data-filter-type=ALWAYS, max=1, min=0, offset=0}, i-signal-in-i-pdu=C_IPB_YAWRateVD}
          signal C_IPB_VehLongAccel: start 7, 12 bit, big-endian, init-value=625, base-type=uint16, compu {raw=phys*361.2716763+625 for phys -1.73..1.73; unit g}, compu-method=CompuMethod_C_IPB_VehLongAccel, update-indication-bit-position=-1, to RDCU(timeout 0.2 s)  # 0x0~0x4E2:valid value invalid valve/Default value: FFF vehicle longitudinal acceleration after offset(the direction of vehicle move)when ESP_ActVehLongAccelVD=0x0:Not valid;ESP_VehLongAccel=0xFFF rear of vehicle=negative front of vehicle=positive"
          signal C_IPB_VehLateralAccel: start 11, 12 bit, big-endian, init-value=625, base-type=uint16, compu {raw=phys*361.2716763+625 for phys -1.73..1.73; unit g}, compu-method=CompuMethod_C_IPB_VehLateralAccel, update-indication-bit-position=-1, to RDCU(timeout 0.2 s)  # 0x0~0x4E2:valid value invalid valve/Default value: FFF vehicle longitudinal acceleration after offset(the direction of vehicle move)when ESP_ActVehLongAccelVD=0x0:Not valid;ESP_VehLongAccel=0xFFF Wheel position to left=negative Wheel position to right=positive Wheel position straightforward=0(positive)"
          signal C_IPB_VehLongAccelVD: start 31, 1 bit, big-endian, init-value=0, base-type=uint8, compu {phys=raw for raw 0..1, 0=NOTVALID, 1=VALID}, compu-method=CompuMethod_C_IPB_VehLongAccelVD, update-indication-bit-position=-1, to RDCU(timeout 0.2 s)
          signal C_IPB_VehLateralAccelVD: start 30, 1 bit, big-endian, init-value=0, base-type=uint8, compu {phys=raw for raw 0..1, 0=NOTVALID, 1=VALID}, compu-method=CompuMethod_C_IPB_VehLateralAccelVD, update-indication-bit-position=-1, to RDCU(timeout 0.2 s)
          signal C_IPB_YAWRate: start 29, 12 bit, big-endian, init-value=1488, base-type=uint16, compu {raw=phys*16+1488 for phys -93..93; unit degps}, compu-method=CompuMethod_C_IPB_YAWRate, update-indication-bit-position=-1, to RDCU(timeout 0.2 s)  # 0x0~0xBA0:valid value invalid valve/Default value: FFF this data indicates information regarding digital filtered yaw rate signal,when ESP_YAWVD=0x0:Not valid;ESP_YAW=0xFFF Wheel position to left=negative Wheel position to right=positive Wheel position straightforward=0(positive)"
          signal C_IPB_YAWRateVD: start 33, 1 bit, big-endian, init-value=0, base-type=uint8, compu {phys=raw for raw 0..1, 0=NOTVALID, 1=VALID}, compu-method=CompuMethod_C_IPB_YAWRateVD, update-indication-bit-position=-1, to RDCU(timeout 0.2 s)
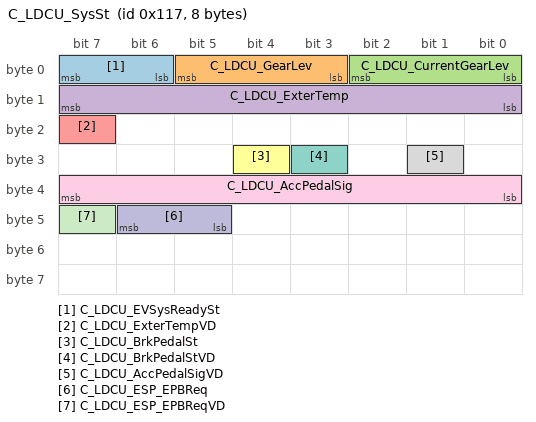
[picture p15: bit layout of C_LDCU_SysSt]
      frame C_LDCU_SysSt: id 0x117, to RDCU, frame-length=8, can-addressing-mode=STANDARD, can-fd-frame-support=true, can-frame-rx-behavior=CAN-FD  # IDS"
        carries pdu C_LDCU_SysSt: packing-byte-order=big-endian, start-position=7
        pdu C_LDCU_SysSt: length=8  # IDS
          transmission-mode-conditions:
            {data-filter={data-filter-type=ALWAYS, max=3, min=0, offset=0}, i-signal-in-i-pdu=C_LDCU_EVSysReadySt}
            {data-filter={data-filter-type=ALWAYS, max=7, min=0, offset=0}, i-signal-in-i-pdu=C_LDCU_GearLev}
            {data-filter={data-filter-type=ALWAYS, max=7, min=0, offset=0}, i-signal-in-i-pdu=C_LDCU_CurrentGearLev}
            {data-filter={data-filter-type=ALWAYS, max=255, min=0}, i-signal-in-i-pdu=C_LDCU_ExterTemp}
            {data-filter={data-filter-type=ALWAYS, max=1, min=0, offset=0}, i-signal-in-i-pdu=C_LDCU_ExterTempVD}
            {data-filter={data-filter-type=ALWAYS, max=1, min=0, offset=0}, i-signal-in-i-pdu=C_LDCU_BrkPedalSt}
            {data-filter={data-filter-type=ALWAYS, max=1, min=0, offset=0}, i-signal-in-i-pdu=C_LDCU_BrkPedalStVD}
            {data-filter={data-filter-type=ALWAYS, max=1, min=0, offset=0}, i-signal-in-i-pdu=C_LDCU_AccPedalSigVD}
            {data-filter={data-filter-type=ALWAYS, max=100, min=0, offset=0}, i-signal-in-i-pdu=C_LDCU_AccPedalSig}
            {data-filter={data-filter-type=ALWAYS, max=3, min=0, offset=0}, i-signal-in-i-pdu=C_LDCU_ESP_EPBReq}
            {data-filter={data-filter-type=ALWAYS, max=1, min=0, offset=0}, i-signal-in-i-pdu=C_LDCU_ESP_EPBReqVD}
            {data-filter={data-filter-type=ALWAYS, max=3, min=0, offset=0}, i-signal-in-i-pdu=C_LDCU_EVSysReadySt}
            {data-filter={data-filter-type=ALWAYS, max=7, min=0, offset=0}, i-signal-in-i-pdu=C_LDCU_GearLev}
            {data-filter={data-filter-type=ALWAYS, max=7, min=0, offset=0}, i-signal-in-i-pdu=C_LDCU_CurrentGearLev}
            {data-filter={data-filter-type=ALWAYS, max=255, min=0}, i-signal-in-i-pdu=C_LDCU_ExterTemp}
            {data-filter={data-filter-type=ALWAYS, max=1, min=0, offset=0}, i-signal-in-i-pdu=C_LDCU_ExterTempVD}
            {data-filter={data-filter-type=ALWAYS, max=1, min=0, offset=0}, i-signal-in-i-pdu=C_LDCU_BrkPedalSt}
            {data-filter={data-filter-type=ALWAYS, max=1, min=0, offset=0}, i-signal-in-i-pdu=C_LDCU_BrkPedalStVD}
            {data-filter={data-filter-type=ALWAYS, max=1, min=0, offset=0}, i-signal-in-i-pdu=C_LDCU_AccPedalSigVD}
            {data-filter={data-filter-type=ALWAYS, max=100, min=0, offset=0}, i-signal-in-i-pdu=C_LDCU_AccPedalSig}
            {data-filter={data-filter-type=ALWAYS, max=3, min=0, offset=0}, i-signal-in-i-pdu=C_LDCU_ESP_EPBReq}
            {data-filter={data-filter-type=ALWAYS, max=1, min=0, offset=0}, i-signal-in-i-pdu=C_LDCU_ESP_EPBReqVD}
          signal C_LDCU_EVSysReadySt: start 7, 2 bit, big-endian, init-value=0, base-type=uint8, compu {phys=raw for raw 0..3, 0=NOTREADY, 1=HIGHVOLTAGEON, 2=READY}, compu-method=CompuMethod_C_LDCU_EVSysReadySt, update-indication-bit-position=-1, to RDCU(timeout 0.1 s)  # EV system ready status"
          signal C_LDCU_GearLev: start 5, 3 bit, big-endian, init-value=0, base-type=uint8, compu {phys=raw for raw 0..7, 0=INVALID, 1=DGEAR, 2=NGEAR, 3=RGEAR, 4=PGEAR, 5=RESERVED, 6=RESERVED, 7=RESERVED}, compu-method=CompuMethod_C_LDCU_GearLev, update-indication-bit-position=-1, to RDCU(timeout 0.1 s)  # Gear lever "
          signal C_LDCU_CurrentGearLev: start 2, 3 bit, big-endian, init-value=0, base-type=uint8, compu {phys=raw for raw 0..7, 0=INVALID, 1=D, 2=N, 3=R, 4=P, 5=RESERVED, 6=RESERVED, 7=RESERVED}, compu-method=CompuMethod_C_LDCU_CurrentGearLev, update-indication-bit-position=-1, to RDCU(timeout 0.1 s)  # Current Gear lever"
          signal C_LDCU_ExterTemp: start 15, 8 bit, big-endian, init-value=120, base-type=uint8, compu {raw=phys*2+80 for phys -40..87.5; unit degC}, compu-method=CompuMethod_C_LDCU_ExterTemp, update-indication-bit-position=-1, to RDCU(timeout 0.1 s)  # External temperature"
          signal C_LDCU_ExterTempVD: start 23, 1 bit, big-endian, init-value=0, base-type=uint8, compu {phys=raw for raw 0..1, 0=NOTVALID, 1=VALID}, compu-method=CompuMethod_C_LDCU_ExterTempVD, update-indication-bit-position=-1, to RDCU(timeout 0.1 s)
          signal C_LDCU_BrkPedalSt: start 28, 1 bit, big-endian, init-value=0, base-type=uint8, compu {phys=raw for raw 0..1, 0=NOTPRESSED, 1=PRESSED}, compu-method=CompuMethod_C_LDCU_BrkPedalSt, update-indication-bit-position=-1, to RDCU(timeout 0.1 s)  # Braking Signal for APB"
          signal C_LDCU_BrkPedalStVD: start 27, 1 bit, big-endian, init-value=0, base-type=uint8, compu {phys=raw for raw 0..1, 0=NOTVALID, 1=VALID}, compu-method=CompuMethod_C_LDCU_BrkPedalStVD, update-indication-bit-position=-1, to RDCU(timeout 0.1 s)
          signal C_LDCU_AccPedalSigVD: start 25, 1 bit, big-endian, init-value=0, base-type=uint8, compu {phys=raw for raw 0..1, 0=NOTVALID, 1=VALID}, compu-method=CompuMethod_C_LDCU_AccPedalSigVD, update-indication-bit-position=-1, to RDCU(timeout 0.1 s)  # the validity of Accelerator Pedal Sensor Signal"
          signal C_LDCU_AccPedalSig: start 39, 8 bit, big-endian, init-value=0, base-type=uint8, compu {raw=phys for phys 0..100}, compu-method=CompuMethod_C_LDCU_AccPedalSig, update-indication-bit-position=-1, to RDCU(timeout 0.1 s)  # Accelerator Pedal Sensor Signal"
          signal C_LDCU_ESP_EPBReq: start 46, 2 bit, big-endian, init-value=0, base-type=uint8, compu {phys=raw for raw 0..3, 0=NOCOMMAND, 1=RELEASE, 2=APPLY, 3=RESERVED}, compu-method=CompuMethod_C_LDCU_ESP_EPBReq, update-indication-bit-position=-1, to RDCU(timeout 0.1 s)
          signal C_LDCU_ESP_EPBReqVD: start 47, 1 bit, big-endian, init-value=0, base-type=uint8, compu {phys=raw for raw 0..1, 0=NOTVALID, 1=VALID}, compu-method=CompuMethod_C_LDCU_ESP_EPBReqVD, update-indication-bit-position=-1, to RDCU(timeout 0.1 s)
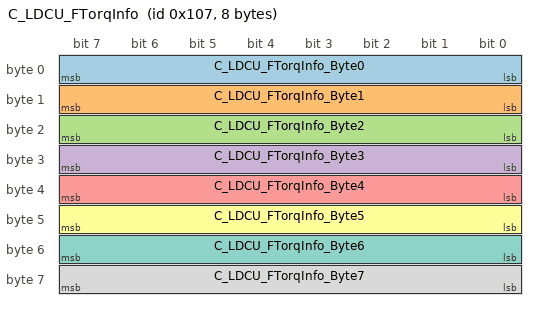
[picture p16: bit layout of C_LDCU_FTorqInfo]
      frame C_LDCU_FTorqInfo: id 0x107, to RDCU, frame-length=8, can-addressing-mode=STANDARD, can-fd-frame-support=true, can-frame-rx-behavior=CAN-FD  # E2E Profile1 Message"
        carries pdu C_LDCU_FTorqInfo: packing-byte-order=big-endian, start-position=7
        pdu C_LDCU_FTorqInfo: length=8  # E2E Profile1 Message
          transmission-mode-conditions:
            C_LDCU_FTorqInfo_Byte{0..7}
            C_LDCU_FTorqInfo_Byte{0..7}
          signal C_LDCU_FTorqInfo_Byte0: start 7, 8 bit, big-endian, init-value=0, base-type=uint8, compu {raw=phys for phys 0..255}, compu-method=CompuMethod_C_LDCU_FTorqInfo_Byte0, update-indication-bit-position=-1, to RDCU(timeout 0.1 s)
          signal C_LDCU_FTorqInfo_Byte1: start 15, 8 bit, big-endian, init-value=54, base-type=uint8, compu {raw=phys for phys 0..255}, compu-method=CompuMethod_C_LDCU_FTorqInfo_Byte1, update-indication-bit-position=-1, to RDCU(timeout 0.1 s)
          signal C_LDCU_FTorqInfo_Byte2: start 23, 8 bit, big-endian, init-value=181, base-type=uint8, compu {raw=phys for phys 0..255}, compu-method=CompuMethod_C_LDCU_FTorqInfo_Byte2, update-indication-bit-position=-1, to RDCU(timeout 0.1 s)
          signal C_LDCU_FTorqInfo_Byte3: start 31, 8 bit, big-endian, init-value=220, base-type=uint8, compu {raw=phys for phys 0..255}, compu-method=CompuMethod_C_LDCU_FTorqInfo_Byte3, update-indication-bit-position=-1, to RDCU(timeout 0.1 s)
          signal C_LDCU_FTorqInfo_Byte4: start 39, 8 bit, big-endian, init-value=93, base-type=uint8, compu {raw=phys for phys 0..255}, compu-method=CompuMethod_C_LDCU_FTorqInfo_Byte4, update-indication-bit-position=-1, to RDCU(timeout 0.1 s)
          signal C_LDCU_FTorqInfo_Byte5: start 47, 8 bit, big-endian, init-value=192, base-type=uint8, compu {raw=phys for phys 0..255}, compu-method=CompuMethod_C_LDCU_FTorqInfo_Byte5, update-indication-bit-position=-1, to RDCU(timeout 0.1 s)
          signal C_LDCU_FTorqInfo_Byte6: start 55, 8 bit, big-endian, init-value=0, base-type=uint8, compu {raw=phys for phys 0..255}, compu-method=CompuMethod_C_LDCU_FTorqInfo_Byte6, update-indication-bit-position=-1, to RDCU(timeout 0.1 s)
          signal C_LDCU_FTorqInfo_Byte7: start 63, 8 bit, big-endian, init-value=0, base-type=uint8, compu {raw=phys for phys 0..255}, compu-method=CompuMethod_C_LDCU_FTorqInfo_Byte7, update-indication-bit-position=-1, to RDCU(timeout 0.1 s)
          mapping ISignalToIPduMapping_ISigGrp_C_LDCU_FTorqInfo: i-signal-group=ISigGrp_C_LDCU_FTorqInfo
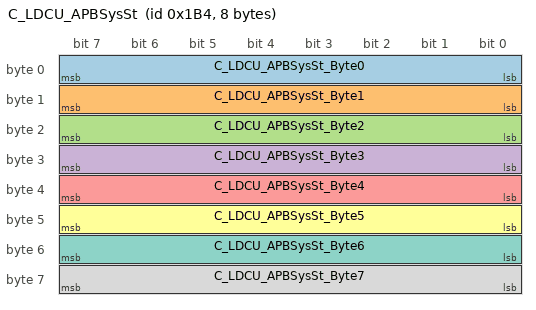
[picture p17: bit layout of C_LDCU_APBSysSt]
      frame C_LDCU_APBSysSt: id 0x1B4, to RDCU, frame-length=8, can-addressing-mode=STANDARD, can-fd-frame-support=true, can-frame-rx-behavior=CAN-FD  # E2E Profile1 Message"
        carries pdu C_LDCU_APBSysSt: packing-byte-order=big-endian, start-position=7
        pdu C_LDCU_APBSysSt: length=8  # E2E Profile1 Message
          transmission-mode-conditions:
            C_LDCU_APBSysSt_Byte{0..7}
            C_LDCU_APBSysSt_Byte{0..7}
          signal C_LDCU_APBSysSt_Byte0: start 7, 8 bit, big-endian, init-value=0, base-type=uint8, compu {raw=phys for phys 0..255}, compu-method=CompuMethod_C_LDCU_APBSysSt_Byte0, update-indication-bit-position=-1, to RDCU(timeout 0.2 s)
          signal C_LDCU_APBSysSt_Byte1: start 15, 8 bit, big-endian, init-value=0, base-type=uint8, compu {raw=phys for phys 0..255}, compu-method=CompuMethod_C_LDCU_APBSysSt_Byte1, update-indication-bit-position=-1, to RDCU(timeout 0.2 s)
          signal C_LDCU_APBSysSt_Byte2: start 23, 8 bit, big-endian, init-value=0, base-type=uint8, compu {raw=phys for phys 0..255}, compu-method=CompuMethod_C_LDCU_APBSysSt_Byte2, update-indication-bit-position=-1, to RDCU(timeout 0.2 s)
          signal C_LDCU_APBSysSt_Byte3: start 31, 8 bit, big-endian, init-value=0, base-type=uint8, compu {raw=phys for phys 0..255}, compu-method=CompuMethod_C_LDCU_APBSysSt_Byte3, update-indication-bit-position=-1, to RDCU(timeout 0.2 s)
          signal C_LDCU_APBSysSt_Byte4: start 39, 8 bit, big-endian, init-value=0, base-type=uint8, compu {raw=phys for phys 0..255}, compu-method=CompuMethod_C_LDCU_APBSysSt_Byte4, update-indication-bit-position=-1, to RDCU(timeout 0.2 s)
          signal C_LDCU_APBSysSt_Byte5: start 47, 8 bit, big-endian, init-value=0, base-type=uint8, compu {raw=phys for phys 0..255}, compu-method=CompuMethod_C_LDCU_APBSysSt_Byte5, update-indication-bit-position=-1, to RDCU(timeout 0.2 s)
          signal C_LDCU_APBSysSt_Byte6: start 55, 8 bit, big-endian, init-value=0, base-type=uint8, compu {raw=phys for phys 0..255}, compu-method=CompuMethod_C_LDCU_APBSysSt_Byte6, update-indication-bit-position=-1, to RDCU(timeout 0.2 s)
          signal C_LDCU_APBSysSt_Byte7: start 63, 8 bit, big-endian, init-value=0, base-type=uint8, compu {raw=phys for phys 0..255}, compu-method=CompuMethod_C_LDCU_APBSysSt_Byte7, update-indication-bit-position=-1, to RDCU(timeout 0.2 s)
          mapping ISignalToIPduMapping_ISigGrp_C_LDCU_APBSysSt: i-signal-group=ISigGrp_C_LDCU_APBSysSt
      frame C_IPB_SysSt2: id 0x18A, to RDCU, frame-length=8, can-addressing-mode=STANDARD, can-fd-frame-support=true, can-frame-rx-behavior=CAN-FD
        carries pdu C_IPB_SysSt2: packing-byte-order=big-endian, start-position=7
        pdu C_IPB_SysSt2: length=8
          transmission-mode-conditions:
            {data-filter={data-filter-type=NEW-IS-WITHIN, max=1022, min=0}, i-signal-in-i-pdu=C_IPB_PlungerPressure}
            {data-filter={data-filter-type=ALWAYS, max=1, min=0, offset=0}, i-signal-in-i-pdu=C_IPB_PlungerPressure_Status}
            {data-filter={data-filter-type=NEW-IS-WITHIN, max=1022, min=0}, i-signal-in-i-pdu=C_IPB_PlungerPressure}
            {data-filter={data-filter-type=ALWAYS, max=1, min=0, offset=0}, i-signal-in-i-pdu=C_IPB_PlungerPressure_Status}
          signal C_IPB_PlungerPressure: start 28, 12 bit, big-endian, init-value=17, base-type=uint16, compu {raw=phys*3.333333333+16.66666667 for phys -5..301.6; unit bar}, compu-method=CompuMethod_C_IPB_PlungerPressure, update-indication-bit-position=-1, to RDCU(timeout 0.2 s)  # Indicate plunger pressure"
          signal C_IPB_PlungerPressure_Status: start 32, 1 bit, big-endian, init-value=0, base-type=uint8, compu {phys=raw for raw 0..1, 0=NOTVALID, 1=VALID}, compu-method=CompuMethod_C_IPB_PlungerPressure_Status, update-indication-bit-position=-1, to RDCU(timeout 0.2 s)  # Indicate plunger pressure"
      frame C_AS_SysSt3: id 0x293, to RDCU, frame-length=8, can-addressing-mode=STANDARD, can-fd-frame-support=true, can-frame-rx-behavior=CAN-FD
        carries pdu C_AS_SysSt3: packing-byte-order=big-endian, start-position=7
        pdu C_AS_SysSt3: length=8
          transmission-mode-conditions:
            {data-filter={data-filter-type=ALWAYS, max=1, min=0, offset=0}, i-signal-in-i-pdu=C_AS_LvlSnsrCalSts}
            {data-filter={data-filter-type=ALWAYS, max=1, min=0, offset=0}, i-signal-in-i-pdu=C_AS_LvlSnsrCalSts}
          signal C_AS_LvlSnsrCalSts: start 18, 1 bit, big-endian, init-value=1, base-type=uint8, compu {phys=raw for raw 0..1, 0=INVALID, 1=VALID}, compu-method=CompuMethod_C_AS_LvlSnsrCalSts, update-indication-bit-position=-1, to RDCU(timeout 1 s)  # Level Sensor Calibration Status Signal"
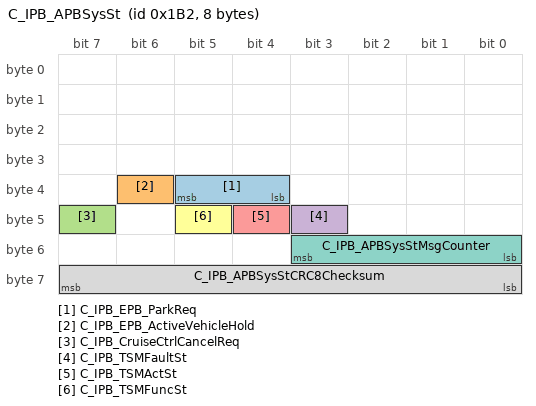
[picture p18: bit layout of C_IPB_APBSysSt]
      frame C_IPB_APBSysSt: id 0x1B2, to RDCU, frame-length=8, can-addressing-mode=STANDARD, can-fd-frame-support=true, can-frame-rx-behavior=CAN-FD  # IDS"
        carries pdu C_IPB_APBSysSt: packing-byte-order=big-endian, start-position=7
        pdu C_IPB_APBSysSt: length=8  # IDS
          transmission-mode-conditions:
            {data-filter={data-filter-type=ALWAYS, max=3, min=0, offset=0}, i-signal-in-i-pdu=C_IPB_EPB_ParkReq}
            {data-filter={data-filter-type=ALWAYS, max=1, min=0, offset=0}, i-signal-in-i-pdu=C_IPB_EPB_ActiveVehicleHold}
            {data-filter={data-filter-type=ALWAYS, max=1, min=0, offset=0}, i-signal-in-i-pdu=C_IPB_CruiseCtrlCancelReq}
            {data-filter={data-filter-type=ALWAYS, max=1, min=0, offset=0}, i-signal-in-i-pdu=C_IPB_TSMFaultSt}
            {data-filter={data-filter-type=ALWAYS, max=1, min=0, offset=0}, i-signal-in-i-pdu=C_IPB_TSMActSt}
            {data-filter={data-filter-type=ALWAYS, max=1, min=0, offset=0}, i-signal-in-i-pdu=C_IPB_TSMFuncSt}
            {data-filter={data-filter-type=ALWAYS, max=15, min=0, offset=0}, i-signal-in-i-pdu=C_IPB_APBSysStMsgCounter}
            {data-filter={data-filter-type=ALWAYS, max=255, min=0, offset=0}, i-signal-in-i-pdu=C_IPB_APBSysStCRC8Checksum}
            {data-filter={data-filter-type=ALWAYS, max=3, min=0, offset=0}, i-signal-in-i-pdu=C_IPB_EPB_ParkReq}
            {data-filter={data-filter-type=ALWAYS, max=1, min=0, offset=0}, i-signal-in-i-pdu=C_IPB_EPB_ActiveVehicleHold}
            {data-filter={data-filter-type=ALWAYS, max=1, min=0, offset=0}, i-signal-in-i-pdu=C_IPB_CruiseCtrlCancelReq}
            {data-filter={data-filter-type=ALWAYS, max=1, min=0, offset=0}, i-signal-in-i-pdu=C_IPB_TSMFaultSt}
            {data-filter={data-filter-type=ALWAYS, max=1, min=0, offset=0}, i-signal-in-i-pdu=C_IPB_TSMActSt}
            {data-filter={data-filter-type=ALWAYS, max=1, min=0, offset=0}, i-signal-in-i-pdu=C_IPB_TSMFuncSt}
            {data-filter={data-filter-type=ALWAYS, max=15, min=0, offset=0}, i-signal-in-i-pdu=C_IPB_APBSysStMsgCounter}
            {data-filter={data-filter-type=ALWAYS, max=255, min=0, offset=0}, i-signal-in-i-pdu=C_IPB_APBSysStCRC8Checksum}
          signal C_IPB_EPB_ParkReq: start 37, 2 bit, big-endian, init-value=0, base-type=uint8, compu {phys=raw for raw 0..3, 0=NOREQUEST, 1=RELESEBAKEREQUEST, 2=LOCKBAKEREQUEST, 3=INVAILID}, compu-method=CompuMethod_C_IPB_EPB_ParkReq, update-indication-bit-position=-1, to RDCU(timeout 0.2 s)
          signal C_IPB_EPB_ActiveVehicleHold: start 38, 1 bit, big-endian, init-value=0, base-type=uint8, compu {phys=raw for raw 0..1, 0=NOTACTIVEVEHICLEHOLD_, 1=ACTIVEVEHILCEHOLD_}, compu-method=CompuMethod_C_IPB_EPB_ActiveVehicleHold, update-indication-bit-position=-1, to RDCU(timeout 0.2 s)
          signal C_IPB_CruiseCtrlCancelReq: start 47, 1 bit, big-endian, init-value=0, base-type=uint8, compu {phys=raw for raw 0..1, 0=NOREQUEST, 1=REQUEST}, compu-method=CompuMethod_C_IPB_CruiseCtrlCancelReq, update-indication-bit-position=-1, to RDCU(timeout 0.2 s)  # ESP request LDCU to cancel cruise control"
          signal C_IPB_TSMFaultSt: start 43, 1 bit, big-endian, init-value=1, base-type=uint8, compu {phys=raw for raw 0..1, 0=NOTFAULT, 1=FAULT}, compu-method=CompuMethod_C_IPB_TSMFaultSt, update-indication-bit-position=-1, to RDCU(timeout 0.2 s)
          signal C_IPB_TSMActSt: start 44, 1 bit, big-endian, init-value=1, base-type=uint8, compu {phys=raw for raw 0..1, 0=NOTACTIVE, 1=ACTIVE}, compu-method=CompuMethod_C_IPB_TSMActSt, update-indication-bit-position=-1, to RDCU(timeout 0.2 s)
          signal C_IPB_TSMFuncSt: start 45, 1 bit, big-endian, init-value=1, base-type=uint8, compu {phys=raw for raw 0..1, 0=OFF, 1=ON}, compu-method=CompuMethod_C_IPB_TSMFuncSt, update-indication-bit-position=-1, to RDCU(timeout 0.2 s)
          signal C_IPB_APBSysStMsgCounter: start 51, 4 bit, big-endian, init-value=0, base-type=uint8, compu {raw=phys for phys 0..15}, compu-method=CompuMethod_C_IPB_APBSysStMsgCounter, update-indication-bit-position=-1, to RDCU(timeout 0.2 s)  # The MessageCounter is a 0 ~ 15 counter, increased of one unit on every message transmission"
          signal C_IPB_APBSysStCRC8Checksum: start 63, 8 bit, big-endian, init-value=0, base-type=uint8, compu {raw=phys for phys 0..255}, compu-method=CompuMethod_C_IPB_APBSysStCRC8Checksum, update-indication-bit-position=-1, to RDCU(timeout 0.2 s)  # CRC8"
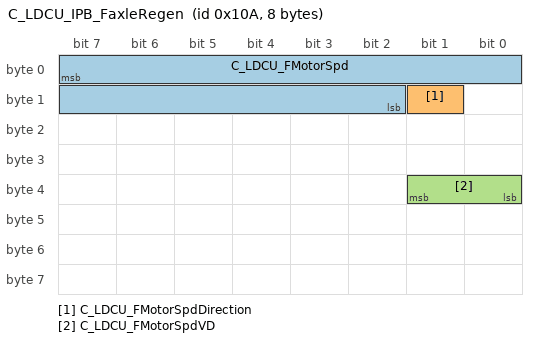
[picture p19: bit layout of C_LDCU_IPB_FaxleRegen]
      frame C_LDCU_IPB_FaxleRegen: id 0x10A, to RDCU, frame-length=8, can-addressing-mode=STANDARD, can-fd-frame-support=true, can-frame-rx-behavior=CAN-FD
        carries pdu C_LDCU_IPB_FaxleRegen: packing-byte-order=big-endian, start-position=7
        pdu C_LDCU_IPB_FaxleRegen: length=8
          transmission-mode-conditions:
            {data-filter={data-filter-type=NEW-IS-WITHIN, max=16000, min=0, offset=0}, i-signal-in-i-pdu=C_LDCU_FMotorSpd}
            {data-filter={data-filter-type=ALWAYS, max=1, min=0, offset=0}, i-signal-in-i-pdu=C_LDCU_FMotorSpdDirection}
            {data-filter={data-filter-type=ALWAYS, max=1, min=0, offset=0}, i-signal-in-i-pdu=C_LDCU_FMotorSpdVD}
            {data-filter={data-filter-type=NEW-IS-WITHIN, max=16000, min=0, offset=0}, i-signal-in-i-pdu=C_LDCU_FMotorSpd}
            {data-filter={data-filter-type=ALWAYS, max=1, min=0, offset=0}, i-signal-in-i-pdu=C_LDCU_FMotorSpdDirection}
            {data-filter={data-filter-type=ALWAYS, max=1, min=0, offset=0}, i-signal-in-i-pdu=C_LDCU_FMotorSpdVD}
          signal C_LDCU_FMotorSpd: start 7, 14 bit, big-endian, init-value=0, base-type=uint16, compu {raw=phys for phys 0..16000; unit rpm}, compu-method=CompuMethod_C_LDCU_FMotorSpd, update-indication-bit-position=-1, to RDCU(timeout 0.1 s)  # Motor speed request"
          signal C_LDCU_FMotorSpdDirection: start 9, 1 bit, big-endian, init-value=0, base-type=uint8, compu {phys=raw for raw 0..1, 0=NEGATIVE, 1=POSITIVE}, compu-method=CompuMethod_C_LDCU_FMotorSpdDirection, update-indication-bit-position=-1, to RDCU(timeout 0.1 s)
          signal C_LDCU_FMotorSpdVD: start 33, 2 bit, big-endian, init-value=0, base-type=uint8, compu {phys=raw for raw 0..1, 0=VALID, 1=INVALID}, compu-method=CompuMethod_C_LDCU_FMotorSpdVD, update-indication-bit-position=-1, to RDCU(timeout 0.1 s)
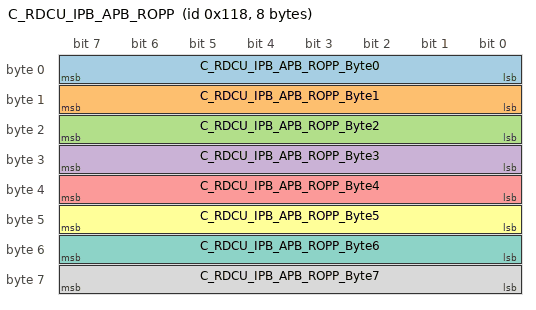
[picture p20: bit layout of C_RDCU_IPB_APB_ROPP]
      frame C_RDCU_IPB_APB_ROPP: id 0x118, from RDCU, frame-length=8, can-addressing-mode=STANDARD, can-fd-frame-support=true, can-frame-tx-behavior=CAN-FD  # E2E Profile1 Message"
        carries pdu C_RDCU_IPB_APB_ROPP: packing-byte-order=big-endian, start-position=7
        pdu C_RDCU_IPB_APB_ROPP: length=8  # E2E Profile1 Message
          transmission-mode-conditions:
            C_RDCU_IPB_APB_ROPP_Byte{0..7}
            C_RDCU_IPB_APB_ROPP_Byte{0..7}
          signal C_RDCU_IPB_APB_ROPP_Byte0: start 7, 8 bit, big-endian, init-value=0, base-type=uint8, compu {raw=phys for phys 0..255}, compu-method=CompuMethod_C_RDCU_IPB_APB_ROPP_Byte0, update-indication-bit-position=-1
          signal C_RDCU_IPB_APB_ROPP_Byte1: start 15, 8 bit, big-endian, init-value=0, base-type=uint8, compu {raw=phys for phys 0..255}, compu-method=CompuMethod_C_RDCU_IPB_APB_ROPP_Byte1, update-indication-bit-position=-1
          signal C_RDCU_IPB_APB_ROPP_Byte2: start 23, 8 bit, big-endian, init-value=0, base-type=uint8, compu {raw=phys for phys 0..255}, compu-method=CompuMethod_C_RDCU_IPB_APB_ROPP_Byte2, update-indication-bit-position=-1
          signal C_RDCU_IPB_APB_ROPP_Byte3: start 31, 8 bit, big-endian, init-value=128, base-type=uint8, compu {raw=phys for phys 0..255}, compu-method=CompuMethod_C_RDCU_IPB_APB_ROPP_Byte3, update-indication-bit-position=-1
          signal C_RDCU_IPB_APB_ROPP_Byte4: start 39, 8 bit, big-endian, init-value=0, base-type=uint8, compu {raw=phys for phys 0..255}, compu-method=CompuMethod_C_RDCU_IPB_APB_ROPP_Byte4, update-indication-bit-position=-1
          signal C_RDCU_IPB_APB_ROPP_Byte5: start 47, 8 bit, big-endian, init-value=0, base-type=uint8, compu {raw=phys for phys 0..255}, compu-method=CompuMethod_C_RDCU_IPB_APB_ROPP_Byte5, update-indication-bit-position=-1
          signal C_RDCU_IPB_APB_ROPP_Byte6: start 55, 8 bit, big-endian, init-value=0, base-type=uint8, compu {raw=phys for phys 0..255}, compu-method=CompuMethod_C_RDCU_IPB_APB_ROPP_Byte6, update-indication-bit-position=-1
          signal C_RDCU_IPB_APB_ROPP_Byte7: start 63, 8 bit, big-endian, init-value=0, base-type=uint8, compu {raw=phys for phys 0..255}, compu-method=CompuMethod_C_RDCU_IPB_APB_ROPP_Byte7, update-indication-bit-position=-1
          mapping ISignalToIPduMapping_ISigGrp_C_RDCU_IPB_APB_ROPP: i-signal-group=ISigGrp_C_RDCU_IPB_APB_ROPP
      frame C_RDCU_RLIN3Info: id 0x23F, from RDCU, frame-length=24, can-addressing-mode=STANDARD, can-fd-frame-support=true, can-frame-tx-behavior=CAN-FD
        carries pdu C_RDCU_RLIN3Info: packing-byte-order=big-endian, start-position=7
        pdu C_RDCU_RLIN3Info: length=24
          transmission-mode-conditions:
            {data-filter={data-filter-type=ALWAYS, max=255, min=0, offset=0}, i-signal-in-i-pdu=C_RDCU_FWiperAngle}
            {data-filter={data-filter-type=ALWAYS, max=255, min=0, offset=0}, i-signal-in-i-pdu=C_RDCU_FWiperMotorAngle}
            {data-filter={data-filter-type=ALWAYS, max=15, min=0, offset=0}, i-signal-in-i-pdu=C_RDCU_FWiperSpd}
            {data-filter={data-filter-type=ALWAYS, max=1, min=0, offset=0}, i-signal-in-i-pdu=C_RDCU_FWiperActiveSt}
            {data-filter={data-filter-type=ALWAYS, max=1, min=0, offset=0}, i-signal-in-i-pdu=C_RDCU_FWiperParkARSt}
            {data-filter={data-filter-type=ALWAYS, max=1, min=0, offset=0}, i-signal-in-i-pdu=C_RDCU_FWiperTurnPosSt}
            {data-filter={data-filter-type=ALWAYS, max=1, min=0, offset=0}, i-signal-in-i-pdu=C_RDCU_FWiperServicePosSt}
            {data-filter={data-filter-type=ALWAYS, max=1, min=0, offset=0}, i-signal-in-i-pdu=C_RDCU_FWiperBlkPosSt}
            {data-filter={data-filter-type=ALWAYS, max=3, min=0, offset=0}, i-signal-in-i-pdu=C_RDCU_FWiperMoveDir}
            {data-filter={data-filter-type=ALWAYS, max=3, min=0, offset=0}, i-signal-in-i-pdu=C_RDCU_FWiperVoltErr}
            {data-filter={data-filter-type=ALWAYS, max=1, min=0, offset=0}, i-signal-in-i-pdu=C_RDCU_FWiperMotorErr}
            {data-filter={data-filter-type=ALWAYS, max=1, min=0, offset=0}, i-signal-in-i-pdu=C_RDCU_FWiperLinErr}
            {data-filter={data-filter-type=ALWAYS, max=1, min=0, offset=0}, i-signal-in-i-pdu=C_RDCU_FWiperTempProtectSt}
            {data-filter={data-filter-type=ALWAYS, max=1, min=0, offset=0}, i-signal-in-i-pdu=C_RDCU_FWiperOverLoadSt}
            {data-filter={data-filter-type=ALWAYS, max=15, min=0, offset=0}, i-signal-in-i-pdu=C_RDCU_RLSRQWiperSPD}
            {data-filter={data-filter-type=ALWAYS, max=1, min=0, offset=0}, i-signal-in-i-pdu=C_RDCU_RLSFaultRain}
            {data-filter={data-filter-type=ALWAYS, max=1, min=0, offset=0}, i-signal-in-i-pdu=C_RDCU_RLSREPError}
            {data-filter={data-filter-type=ALWAYS, max=3, min=0, offset=0}, i-signal-in-i-pdu=C_RDCU_RLSVOLTError}
            {data-filter={data-filter-type=ALWAYS, max=50, min=0, offset=0}, i-signal-in-i-pdu=C_RDCU_RLSRainIntensity}
            {data-filter={data-filter-type=NEW-IS-WITHIN, max=1023, min=0, offset=0}, i-signal-in-i-pdu=C_RDCU_RLSBrightnessFW}
            {data-filter={data-filter-type=NEW-IS-WITHIN, max=65535, min=0, offset=0}, i-signal-in-i-pdu=C_RDCU_RLSDCbreA}
            {data-filter={data-filter-type=NEW-IS-WITHIN, max=65535, min=0, offset=0}, i-signal-in-i-pdu=C_RDCU_RLSADCA}
            {data-filter={data-filter-type=NEW-IS-WITHIN, max=65535, min=0, offset=0}, i-signal-in-i-pdu=C_RDCU_RLSDCbreB}
            {data-filter={data-filter-type=NEW-IS-WITHIN, max=65535, min=0, offset=0}, i-signal-in-i-pdu=C_RDCU_RLSADCB}
            {data-filter={data-filter-type=ALWAYS, max=1, min=0, offset=0}, i-signal-in-i-pdu=C_FWiperSysFaultWarning}
            {data-filter={data-filter-type=ALWAYS, max=255, min=0, offset=0}, i-signal-in-i-pdu=C_RDCU_FWiperAngle}
            {data-filter={data-filter-type=ALWAYS, max=255, min=0, offset=0}, i-signal-in-i-pdu=C_RDCU_FWiperMotorAngle}
            {data-filter={data-filter-type=ALWAYS, max=15, min=0, offset=0}, i-signal-in-i-pdu=C_RDCU_FWiperSpd}
            {data-filter={data-filter-type=ALWAYS, max=1, min=0, offset=0}, i-signal-in-i-pdu=C_RDCU_FWiperActiveSt}
            {data-filter={data-filter-type=ALWAYS, max=1, min=0, offset=0}, i-signal-in-i-pdu=C_RDCU_FWiperParkARSt}
            {data-filter={data-filter-type=ALWAYS, max=1, min=0, offset=0}, i-signal-in-i-pdu=C_RDCU_FWiperTurnPosSt}
            {data-filter={data-filter-type=ALWAYS, max=1, min=0, offset=0}, i-signal-in-i-pdu=C_RDCU_FWiperServicePosSt}
            {data-filter={data-filter-type=ALWAYS, max=1, min=0, offset=0}, i-signal-in-i-pdu=C_RDCU_FWiperBlkPosSt}
            {data-filter={data-filter-type=ALWAYS, max=3, min=0, offset=0}, i-signal-in-i-pdu=C_RDCU_FWiperMoveDir}
            {data-filter={data-filter-type=ALWAYS, max=3, min=0, offset=0}, i-signal-in-i-pdu=C_RDCU_FWiperVoltErr}
            {data-filter={data-filter-type=ALWAYS, max=1, min=0, offset=0}, i-signal-in-i-pdu=C_RDCU_FWiperMotorErr}
            {data-filter={data-filter-type=ALWAYS, max=1, min=0, offset=0}, i-signal-in-i-pdu=C_RDCU_FWiperLinErr}
            {data-filter={data-filter-type=ALWAYS, max=1, min=0, offset=0}, i-signal-in-i-pdu=C_RDCU_FWiperTempProtectSt}
            {data-filter={data-filter-type=ALWAYS, max=1, min=0, offset=0}, i-signal-in-i-pdu=C_RDCU_FWiperOverLoadSt}
            {data-filter={data-filter-type=ALWAYS, max=15, min=0, offset=0}, i-signal-in-i-pdu=C_RDCU_RLSRQWiperSPD}
            {data-filter={data-filter-type=ALWAYS, max=1, min=0, offset=0}, i-signal-in-i-pdu=C_RDCU_RLSFaultRain}
            {data-filter={data-filter-type=ALWAYS, max=1, min=0, offset=0}, i-signal-in-i-pdu=C_RDCU_RLSREPError}
            {data-filter={data-filter-type=ALWAYS, max=3, min=0, offset=0}, i-signal-in-i-pdu=C_RDCU_RLSVOLTError}
            {data-filter={data-filter-type=ALWAYS, max=50, min=0, offset=0}, i-signal-in-i-pdu=C_RDCU_RLSRainIntensity}
            {data-filter={data-filter-type=NEW-IS-WITHIN, max=1023, min=0, offset=0}, i-signal-in-i-pdu=C_RDCU_RLSBrightnessFW}
            {data-filter={data-filter-type=NEW-IS-WITHIN, max=65535, min=0, offset=0}, i-signal-in-i-pdu=C_RDCU_RLSDCbreA}
            {data-filter={data-filter-type=NEW-IS-WITHIN, max=65535, min=0, offset=0}, i-signal-in-i-pdu=C_RDCU_RLSADCA}
            {data-filter={data-filter-type=NEW-IS-WITHIN, max=65535, min=0, offset=0}, i-signal-in-i-pdu=C_RDCU_RLSDCbreB}
            {data-filter={data-filter-type=NEW-IS-WITHIN, max=65535, min=0, offset=0}, i-signal-in-i-pdu=C_RDCU_RLSADCB}
            {data-filter={data-filter-type=ALWAYS, max=1, min=0, offset=0}, i-signal-in-i-pdu=C_FWiperSysFaultWarning}
          signal C_RDCU_FWiperAngle: start 7, 8 bit, big-endian, init-value=0, base-type=uint8, compu {raw=phys for phys 0..255; unit deg}, compu-method=CompuMethod_C_RDCU_FWiperAngle, update-indication-bit-position=-1  # H93 doesn't use"
          signal C_RDCU_FWiperMotorAngle: start 15, 8 bit, big-endian, init-value=0, base-type=uint8, compu {raw=phys for phys 0..255; unit deg}, compu-method=CompuMethod_C_RDCU_FWiperMotorAngle, update-indication-bit-position=-1
          signal C_RDCU_FWiperSpd: start 23, 4 bit, big-endian, init-value=0, base-type=uint8, compu {phys=raw for raw 0..15, 0=SPEED0_MIN, 11=SPEED60_MIN_HIGHSPD_, 1=SPEED40_MIN_LOWSPD_, 2=SPEED42_MIN, 3=SPEED44_MIN, 4=SPEED46_MIN, 5=SPEED48_MIN, 6=SPEED50_MIN, 7=SPEED52_MIN, 8=SPEED54_MIN, 9=SPEED56_MIN, 10=SPEED58MIN}, compu-method=CompuMethod_C_RDCU_FWiperSpd, update-indication-bit-position=-1
          signal C_RDCU_FWiperActiveSt: start 19, 1 bit, big-endian, init-value=0, base-type=uint8, compu {phys=raw for raw 0..1, 0=NOTACTIVE, 1=ACTIVE}, compu-method=CompuMethod_C_RDCU_FWiperActiveSt, update-indication-bit-position=-1
          signal C_RDCU_FWiperParkARSt: start 18, 1 bit, big-endian, init-value=0, base-type=uint8, compu {phys=raw for raw 0..1, 0=NOTINPARKINGAREA, 1=INPARKINGAREA}, compu-method=CompuMethod_C_RDCU_FWiperParkARSt, update-indication-bit-position=-1
          signal C_RDCU_FWiperTurnPosSt: start 17, 1 bit, big-endian, init-value=0, base-type=uint8, compu {phys=raw for raw 0..1, 0=NOTINTURNINGAREA, 1=INTURNINGAREA}, compu-method=CompuMethod_C_RDCU_FWiperTurnPosSt, update-indication-bit-position=-1
          signal C_RDCU_FWiperServicePosSt: start 16, 1 bit, big-endian, init-value=0, base-type=uint8, compu {phys=raw for raw 0..1, 0=NOTINSERVICEPOSITION, 1=INSERVICEPOSITION}, compu-method=CompuMethod_C_RDCU_FWiperServicePosSt, update-indication-bit-position=-1
          signal C_RDCU_FWiperBlkPosSt: start 31, 1 bit, big-endian, init-value=0, base-type=uint8, compu {phys=raw for raw 0..1, 0=NOBLOCKDETECTED, 1=BLOCKDETECTED}, compu-method=CompuMethod_C_RDCU_FWiperBlkPosSt, update-indication-bit-position=-1
          signal C_RDCU_FWiperMoveDir: start 30, 2 bit, big-endian, init-value=0, base-type=uint8, compu {phys=raw for raw 0..3, 0=NOMOVE, 1=UPPER, 2=DOWN, 3=RESERVED}, compu-method=CompuMethod_C_RDCU_FWiperMoveDir, update-indication-bit-position=-1
          signal C_RDCU_FWiperVoltErr: start 28, 2 bit, big-endian, init-value=0, base-type=uint8, compu {phys=raw for raw 0..3, 0=NOERR, 1=OVERVOLTAGE, 2=UNDERVOLTAGE}, compu-method=CompuMethod_C_RDCU_FWiperVoltErr, update-indication-bit-position=-1
          signal C_RDCU_FWiperMotorErr: start 26, 1 bit, big-endian, init-value=0, base-type=uint8, compu {phys=raw for raw 0..1, 0=NOERR, 1=ERR}, compu-method=CompuMethod_C_RDCU_FWiperMotorErr, update-indication-bit-position=-1
          signal C_RDCU_FWiperLinErr: start 25, 1 bit, big-endian, init-value=0, base-type=uint8, compu {phys=raw for raw 0..1, 0=NOERR, 1=ERR}, compu-method=CompuMethod_C_RDCU_FWiperLinErr, update-indication-bit-position=-1
          signal C_RDCU_FWiperTempProtectSt: start 24, 1 bit, big-endian, init-value=0, base-type=uint8, compu {phys=raw for raw 0..1, 0=NOTACTIVE, 1=ACTIVE}, compu-method=CompuMethod_C_RDCU_FWiperTempProtectSt, update-indication-bit-position=-1
          signal C_RDCU_FWiperOverLoadSt: start 39, 1 bit, big-endian, init-value=0, base-type=uint8, compu {phys=raw for raw 0..1, 0=NOTACTIVE, 1=ACTIVE}, compu-method=CompuMethod_C_RDCU_FWiperOverLoadSt, update-indication-bit-position=-1
          signal C_RDCU_RLSRQWiperSPD: start 38, 4 bit, big-endian, init-value=0, base-type=uint8, compu {phys=raw for raw 0..15, 0=SPEED0_MIN, 11=SPEED60_MIN_HIGHSPD_, 1=SPEED40_MIN_LOWSPD_, 2=SPEED42_MIN, 3=SPEED44_MIN, 4=SPEED46_MIN, 5=SPEED48_MIN, 6=SPEED50_MIN, 7=SPEED52_MIN, 8=SPEED54_MIN, 9=SPEED56_MIN, 10=SPEED58MIN}, compu-method=CompuMethod_C_RDCU_RLSRQWiperSPD, update-indication-bit-position=-1
          signal C_RDCU_RLSFaultRain: start 34, 1 bit, big-endian, init-value=0, base-type=uint8, compu {phys=raw for raw 0..1, 0=NORMALSTATUS, 1=STATUSFAULT}, compu-method=CompuMethod_C_RDCU_RLSFaultRain, update-indication-bit-position=-1
          signal C_RDCU_RLSREPError: start 33, 1 bit, big-endian, init-value=0, base-type=uint8, compu {phys=raw for raw 0..1, 0=NOERROR, 1=ERROR}, compu-method=CompuMethod_C_RDCU_RLSREPError, update-indication-bit-position=-1
          signal C_RDCU_RLSVOLTError: start 32, 2 bit, big-endian, init-value=0, base-type=uint8, compu {phys=raw for raw 0..3, 0=NOERROR, 1=VOLT_LOW, 2=VOLT_HIGH, 3=NOTUSED}, compu-method=CompuMethod_C_RDCU_RLSVOLTError, update-indication-bit-position=-1
          signal C_RDCU_RLSRainIntensity: start 46, 6 bit, big-endian, init-value=0, base-type=uint8, compu {raw=phys*0.5 for phys 0..100; unit percent}, compu-method=CompuMethod_C_RDCU_RLSRainIntensity, update-indication-bit-position=-1
          signal C_RDCU_RLSBrightnessFW: start 48, 10 bit, big-endian, init-value=1023, base-type=uint16, compu {raw=phys/6 for phys 0..6138; unit LUX}, compu-method=CompuMethod_C_RDCU_RLSBrightnessFW, update-indication-bit-position=-1
          signal C_RDCU_RLSDCbreA: start 70, 16 bit, big-endian, init-value=0, base-type=uint16, compu {raw=phys for phys 0..65535}, compu-method=CompuMethod_C_RDCU_RLSDCbreA, update-indication-bit-position=-1
          signal C_RDCU_RLSADCA: start 86, 16 bit, big-endian, init-value=0, base-type=uint16, compu {raw=phys for phys 0..65535}, compu-method=CompuMethod_C_RDCU_RLSADCA, update-indication-bit-position=-1
          signal C_RDCU_RLSDCbreB: start 102, 16 bit, big-endian, init-value=0, base-type=uint16, compu {raw=phys for phys 0..65535}, compu-method=CompuMethod_C_RDCU_RLSDCbreB, update-indication-bit-position=-1
          signal C_RDCU_RLSADCB: start 118, 16 bit, big-endian, init-value=0, base-type=uint16, compu {raw=phys for phys 0..65535}, compu-method=CompuMethod_C_RDCU_RLSADCB, update-indication-bit-position=-1
          signal C_FWiperSysFaultWarning: start 40, 1 bit, big-endian, init-value=0, base-type=uint8, compu {phys=raw for raw 0..1, 0=NORMAL, 1=WARNING}, compu-method=CompuMethod_C_FWiperSysFaultWarning, update-indication-bit-position=-1
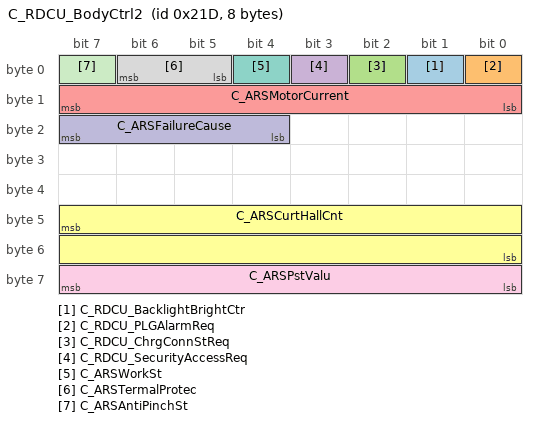
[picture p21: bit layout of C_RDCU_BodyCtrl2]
      frame C_RDCU_BodyCtrl2: id 0x21D, from RDCU, frame-length=8, can-addressing-mode=STANDARD, can-fd-frame-support=true, can-frame-tx-behavior=CAN-FD
        carries pdu C_RDCU_BodyCtrl2: packing-byte-order=big-endian, start-position=7
        pdu C_RDCU_BodyCtrl2: length=8
          transmission-mode-conditions:
            {data-filter={data-filter-type=ALWAYS, max=1, min=0, offset=0}, i-signal-in-i-pdu=C_RDCU_BacklightBrightCtr}
            {data-filter={data-filter-type=ALWAYS, max=1, min=0, offset=0}, i-signal-in-i-pdu=C_RDCU_PLGAlarmReq}
            {data-filter={data-filter-type=ALWAYS, max=1, min=0, offset=0}, i-signal-in-i-pdu=C_RDCU_ChrgConnStReq}
            {data-filter={data-filter-type=ALWAYS, max=1, min=0, offset=0}, i-signal-in-i-pdu=C_RDCU_SecurityAccessReq}
            {data-filter={data-filter-type=ALWAYS, max=255, min=0, offset=0}, i-signal-in-i-pdu=C_ARSMotorCurrent}
            {data-filter={data-filter-type=NEW-IS-WITHIN, max=65535, min=0, offset=0}, i-signal-in-i-pdu=C_ARSCurtHallCnt}
            {data-filter={data-filter-type=ALWAYS, max=1, min=0, offset=0}, i-signal-in-i-pdu=C_ARSWorkSt}
            {data-filter={data-filter-type=ALWAYS, max=3, min=0, offset=0}, i-signal-in-i-pdu=C_ARSTermalProtec}
            {data-filter={data-filter-type=ALWAYS, max=255, min=0, offset=0}, i-signal-in-i-pdu=C_ARSPstValu}
            {data-filter={data-filter-type=ALWAYS, max=15, min=0, offset=0}, i-signal-in-i-pdu=C_ARSFailureCause}
            {data-filter={data-filter-type=ALWAYS, max=1, min=0, offset=0}, i-signal-in-i-pdu=C_ARSAntiPinchSt}
            {data-filter={data-filter-type=ALWAYS, max=1, min=0, offset=0}, i-signal-in-i-pdu=C_RDCU_BacklightBrightCtr}
            {data-filter={data-filter-type=ALWAYS, max=1, min=0, offset=0}, i-signal-in-i-pdu=C_RDCU_PLGAlarmReq}
            {data-filter={data-filter-type=ALWAYS, max=1, min=0, offset=0}, i-signal-in-i-pdu=C_RDCU_ChrgConnStReq}
            {data-filter={data-filter-type=ALWAYS, max=1, min=0, offset=0}, i-signal-in-i-pdu=C_RDCU_SecurityAccessReq}
            {data-filter={data-filter-type=ALWAYS, max=255, min=0, offset=0}, i-signal-in-i-pdu=C_ARSMotorCurrent}
            {data-filter={data-filter-type=NEW-IS-WITHIN, max=65535, min=0, offset=0}, i-signal-in-i-pdu=C_ARSCurtHallCnt}
            {data-filter={data-filter-type=ALWAYS, max=1, min=0, offset=0}, i-signal-in-i-pdu=C_ARSWorkSt}
            {data-filter={data-filter-type=ALWAYS, max=3, min=0, offset=0}, i-signal-in-i-pdu=C_ARSTermalProtec}
            {data-filter={data-filter-type=ALWAYS, max=255, min=0, offset=0}, i-signal-in-i-pdu=C_ARSPstValu}
            {data-filter={data-filter-type=ALWAYS, max=15, min=0, offset=0}, i-signal-in-i-pdu=C_ARSFailureCause}
            {data-filter={data-filter-type=ALWAYS, max=1, min=0, offset=0}, i-signal-in-i-pdu=C_ARSAntiPinchSt}
          signal C_RDCU_BacklightBrightCtr: start 1, 1 bit, big-endian, init-value=0, base-type=uint8, compu {phys=raw for raw 0..1, 0=NOTACTIVE, 1=ACTIVE}, compu-method=CompuMethod_C_RDCU_BacklightBrightCtr, update-indication-bit-position=-1
          signal C_RDCU_PLGAlarmReq: start 0, 1 bit, big-endian, init-value=0, base-type=uint8, compu {phys=raw for raw 0..1, 0=INACTIVE, 1=ACTIVE}, compu-method=CompuMethod_C_RDCU_PLGAlarmReq, update-indication-bit-position=-1
          signal C_RDCU_ChrgConnStReq: start 2, 1 bit, big-endian, init-value=0, base-type=uint8, compu {phys=raw for raw 0..1, 0=NOREQUEST, 1=REQUEST}, compu-method=CompuMethod_C_RDCU_ChrgConnStReq, update-indication-bit-position=-1
          signal C_RDCU_SecurityAccessReq: start 3, 1 bit, big-endian, init-value=0, base-type=uint8, compu {phys=raw for raw 0..1, 0=NOREQUEST, 1=REQUEST}, compu-method=CompuMethod_C_RDCU_SecurityAccessReq, update-indication-bit-position=-1
          signal C_ARSMotorCurrent: start 15, 8 bit, big-endian, init-value=0, base-type=uint8, compu {raw=phys*10 for phys 0..25.5}, compu-method=CompuMethod_C_ARSMotorCurrent, update-indication-bit-position=-1
          signal C_ARSCurtHallCnt: start 47, 16 bit, big-endian, init-value=0, base-type=uint16, compu {raw=phys for phys 0..65535}, compu-method=CompuMethod_C_ARSCurtHallCnt, update-indication-bit-position=-1
          signal C_ARSWorkSt: start 4, 1 bit, big-endian, init-value=0, base-type=uint8, compu {phys=raw for raw 0..1, 0=NORMAL, 1=ERROR}, compu-method=CompuMethod_C_ARSWorkSt, update-indication-bit-position=-1
          signal C_ARSTermalProtec: start 6, 2 bit, big-endian, init-value=0, base-type=uint8, compu {phys=raw for raw 0..3, 0=INVALID, 1=ACTIVE, 2=PROTCNOTOPEN, 3=RESERVED}, compu-method=CompuMethod_C_ARSTermalProtec, update-indication-bit-position=-1
          signal C_ARSPstValu: start 63, 8 bit, big-endian, init-value=0, base-type=uint8, compu {phys=raw for raw 0..255, 230=UNKNOWN, 110=UNKNOWN, 231=UNKNOWN, 111=UNKNOWN, 232=UNKNOWN, 112=UNKNOWN, 233=UNKNOWN, 113=UNKNOWN, 234=UNKNOWN, 114=UNKNOWN, 235=UNKNOWN, 115=UNKNOWN, 236=UNKNOWN, 116=UNKNOWN, 237=UNKNOWN, 117=UNKNOWN, 238=UNKNOWN, 118=UNKNOWN, 239=UNKNOWN, 119=UNKNOWN, 10..19=HALF_FOLD, 240=UNKNOWN, 120=UNKNOWN, 241=UNKNOWN, 0=FULLFOLDED, 121=UNKNOWN, 242=UNKNOWN, 1=HALF_FOLD, 122=UNKNOWN, 243=UNKNOWN, 2=HALF_FOLD, 123=UNKNOWN, 244=UNKNOWN, 3=HALF_FOLD, 124=UNKNOWN, 245=UNKNOWN, 4=HALF_FOLD, 125=UNKNOWN, 246=UNKNOWN, 5=HALF_FOLD, 126=UNKNOWN, 247=UNKNOWN, 6=HALF_FOLD, 127=UNKNOWN, 248=UNKNOWN, 7=HALF_FOLD, 128=UNKNOWN, 249=UNKNOWN, 8=HALF_FOLD, 129=UNKNOWN, 9=HALF_FOLD, 20..29=HALF_FOLD, 250=UNKNOWN, 130=UNKNOWN, 251=UNKNOWN, 131=UNKNOWN, 252=UNKNOWN, 132=UNKNOWN, 253=UNKNOWN, 133=UNKNOWN, 254=UNKNOWN, 134=UNKNOWN, 255=UNKNOWN, 135..139=UNKNOWN, 30..39=HALF_FOLD, 140..149=UNKNOWN, 40..49=HALF_FOLD, 150..159=UNKNOWN, 50..59=HALF_FOLD, 160..169=UNKNOWN, 60..69=HALF_FOLD, 170..179=UNKNOWN, 70..79=HALF_FOLD, 180..189=UNKNOWN, 80..89=HALF_FOLD, 190..199=UNKNOWN, 90..99=HALF_FOLD, 200..220=UNKNOWN, 100=FULLUNFOLDED, 221=UNKNOWN, 101=UNKNOWN, 222=UNKNOWN, 102=UNKNOWN, 223=UNKNOWN, 103=UNKNOWN, 224=UNKNOWN, 104=UNKNOWN, 225=UNKNOWN, 105=UNKNOWN, 226=UNKNOWN, 106=UNKNOWN, 227=UNKNOWN, 107=UNKNOWN, 228=UNKNOWN, 108=UNKNOWN, 229=UNKNOWN, 109=UNKNOWN}, compu-method=CompuMethod_C_ARSPstValu, update-indication-bit-position=-1
          signal C_ARSFailureCause: start 23, 4 bit, big-endian, init-value=0, base-type=uint8, compu {phys=raw for raw 0..15, 0=RESERVED, 1=PSTOVERVALUE, 2=PSTFAIL, 3=MAXARSHALLCNTFAIL, 4=CALIBRATIONHALLCOUNTFAIL, 5=ARSHALLERR, 6=NVMFAILZEROPOSLEARNINGFAIL, 7=STALLDECTECTIONTIMEOUT, 8=ZEROPOSLEARNINGFAIL, 9=ARSMOTORSTALL, 10=RESERVED}, compu-method=CompuMethod_C_ARSFailureCause, update-indication-bit-position=-1
          signal C_ARSAntiPinchSt: start 7, 1 bit, big-endian, init-value=0, base-type=uint8, compu {phys=raw for raw 0..1, 0=NOT_ACTIVE, 1=ACTIVE}, compu-method=CompuMethod_C_ARSAntiPinchSt, update-indication-bit-position=-1
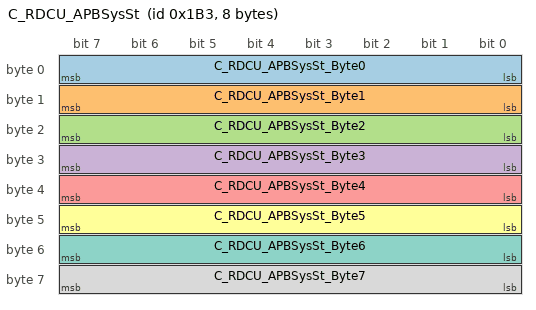
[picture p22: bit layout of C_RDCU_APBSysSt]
      frame C_RDCU_APBSysSt: id 0x1B3, from RDCU, frame-length=8, can-addressing-mode=STANDARD, can-fd-frame-support=true, can-frame-tx-behavior=CAN-FD  # E2E Profile1 Message"
        carries pdu C_RDCU_APBSysSt: packing-byte-order=big-endian, start-position=7
        pdu C_RDCU_APBSysSt: length=8  # E2E Profile1 Message
          transmission-mode-conditions:
            C_RDCU_APBSysSt_Byte{0..7}
            C_RDCU_APBSysSt_Byte{0..7}
          signal C_RDCU_APBSysSt_Byte0: start 7, 8 bit, big-endian, init-value=0, base-type=uint8, compu {raw=phys for phys 0..255}, compu-method=CompuMethod_C_RDCU_APBSysSt_Byte0, update-indication-bit-position=-1
          signal C_RDCU_APBSysSt_Byte1: start 15, 8 bit, big-endian, init-value=0, base-type=uint8, compu {raw=phys for phys 0..255}, compu-method=CompuMethod_C_RDCU_APBSysSt_Byte1, update-indication-bit-position=-1
          signal C_RDCU_APBSysSt_Byte2: start 23, 8 bit, big-endian, init-value=0, base-type=uint8, compu {raw=phys for phys 0..255}, compu-method=CompuMethod_C_RDCU_APBSysSt_Byte2, update-indication-bit-position=-1
          signal C_RDCU_APBSysSt_Byte3: start 31, 8 bit, big-endian, init-value=0, base-type=uint8, compu {raw=phys for phys 0..255}, compu-method=CompuMethod_C_RDCU_APBSysSt_Byte3, update-indication-bit-position=-1
          signal C_RDCU_APBSysSt_Byte4: start 39, 8 bit, big-endian, init-value=0, base-type=uint8, compu {raw=phys for phys 0..255}, compu-method=CompuMethod_C_RDCU_APBSysSt_Byte4, update-indication-bit-position=-1
          signal C_RDCU_APBSysSt_Byte5: start 47, 8 bit, big-endian, init-value=0, base-type=uint8, compu {raw=phys for phys 0..255}, compu-method=CompuMethod_C_RDCU_APBSysSt_Byte5, update-indication-bit-position=-1
          signal C_RDCU_APBSysSt_Byte6: start 55, 8 bit, big-endian, init-value=0, base-type=uint8, compu {raw=phys for phys 0..255}, compu-method=CompuMethod_C_RDCU_APBSysSt_Byte6, update-indication-bit-position=-1
          signal C_RDCU_APBSysSt_Byte7: start 63, 8 bit, big-endian, init-value=0, base-type=uint8, compu {raw=phys for phys 0..255}, compu-method=CompuMethod_C_RDCU_APBSysSt_Byte7, update-indication-bit-position=-1
          mapping ISignalToIPduMapping_ISigGrp_C_RDCU_APBSysSt: i-signal-group=ISigGrp_C_RDCU_APBSysSt
  can cluster Can_Network_0: protocol-name=CAN, protocol-version=2023_3_9_163737
    can physical channel Can_Network_0_Channel: comm-connectors=Conn_Can_Network_0_CANNODE_0_RDCU
      frame C_LDCU_IPB_RaxleRegen: id 0x10B, to RDCU, frame-length=8, can-addressing-mode=STANDARD, can-fd-frame-support=true, can-frame-rx-behavior=CAN-FD
        carries pdu C_LDCU_IPB_RaxleRegen: packing-byte-order=big-endian, start-position=7
      frame C_IPB_SpdEdges: id 0x12A, to RDCU, frame-length=8, can-addressing-mode=STANDARD, can-fd-frame-support=true, can-frame-rx-behavior=CAN-FD
        carries pdu C_IPB_SpdEdges: packing-byte-order=big-endian, start-position=7
      frame C_IPB_SpdInfoR: id 0x128, to RDCU, frame-length=8, can-addressing-mode=STANDARD, can-fd-frame-support=true, can-frame-rx-behavior=CAN-FD
        carries pdu C_IPB_SpdInfoR: packing-byte-order=big-endian, start-position=7
      frame C_LDCU_EPB_APB_ROPP2: id 0x114, to RDCU, frame-length=8, can-addressing-mode=STANDARD, can-fd-frame-support=true, can-frame-rx-behavior=CAN-FD  # E2E Profile1 Message"
        carries pdu C_LDCU_EPB_APB_ROPP2: packing-byte-order=big-endian, start-position=7
      frame C_IPB_SysSt_E2E: id 0x1A6, to RDCU, frame-length=12, can-addressing-mode=STANDARD, can-fd-frame-support=true, can-frame-rx-behavior=CAN-FD  # E2E Profile1 Message"
        carries pdu C_IPB_SysSt_E2E: packing-byte-order=big-endian, start-position=7
      frame C_MFS_Status: id 0x1F1, to RDCU, frame-length=8, can-addressing-mode=STANDARD, can-fd-frame-support=true, can-frame-rx-behavior=CAN-FD  # E2E Profile1 Message"
        carries pdu C_MFS_Status: packing-byte-order=big-endian, start-position=7
      frame C_IPB_SysSt1: id 0x116, to RDCU, frame-length=8, can-addressing-mode=STANDARD, can-fd-frame-support=true, can-frame-rx-behavior=CAN-FD
        carries pdu C_IPB_SysSt1: packing-byte-order=big-endian, start-position=7
      frame C_AS_SysSt2: id 0x292, to RDCU, frame-length=48, can-addressing-mode=STANDARD, can-fd-frame-support=true, can-frame-rx-behavior=CAN-FD
        carries pdu C_AS_SysSt2: packing-byte-order=big-endian, start-position=7
      frame C_LDCU_EPBDebugData: id 0x610, to RDCU, frame-length=8, can-addressing-mode=STANDARD, can-fd-frame-support=true, can-frame-rx-behavior=CAN-FD
        carries pdu C_LDCU_EPBDebugData: packing-byte-order=big-endian, start-position=7
      frame C_XPU_IPB_ADASToqCtrl: id 0x100, to RDCU, frame-length=8, can-addressing-mode=STANDARD, can-fd-frame-support=true, can-frame-rx-behavior=CAN-FD  # E2E Profile1 Message"
        carries pdu C_XPU_IPB_ADASToqCtrl: packing-byte-order=big-endian, start-position=7
      frame C_IPB_SpdInfoF: id 0x127, to RDCU, frame-length=8, can-addressing-mode=STANDARD, can-fd-frame-support=true, can-frame-rx-behavior=CAN-FD  # IDS"
        carries pdu C_IPB_SpdInfoF: packing-byte-order=big-endian, start-position=7
      frame C_IPB_SpdInfo_E2E: id 0x126, to RDCU, frame-length=16, can-addressing-mode=STANDARD, can-fd-frame-support=true, can-frame-rx-behavior=CAN-FD  # E2E Profile1 Message"
        carries pdu C_IPB_SpdInfo_E2E: packing-byte-order=big-endian, start-position=7
      frame C_AS_SysSt1: id 0x18F, to RDCU, frame-length=8, can-addressing-mode=STANDARD, can-fd-frame-support=true, can-frame-rx-behavior=CAN-FD
        carries pdu C_AS_SysSt1: packing-byte-order=big-endian, start-position=7
      frame C_LDCU_BodySysSt1: id 0x224, to RDCU, frame-length=8, can-addressing-mode=STANDARD, can-fd-frame-support=true, can-frame-rx-behavior=CAN-FD
        carries pdu C_LDCU_BodySysSt1: packing-byte-order=big-endian, start-position=7
      frame C_CDCU_ChassisCtrl: id 0x2C0, to RDCU, frame-length=8, can-addressing-mode=STANDARD, can-fd-frame-support=true, can-frame-rx-behavior=CAN-FD
        carries pdu C_CDCU_ChassisCtrl: packing-byte-order=big-endian, start-position=7
      frame C_IPB_CylinderPressure2: id 0x110, to RDCU, frame-length=8, can-addressing-mode=STANDARD, can-fd-frame-support=true, can-frame-rx-behavior=CAN-FD
        carries pdu C_IPB_CylinderPressure2: packing-byte-order=big-endian, start-position=7
      frame C_IPB_SysSt: id 0x1A7, to RDCU, frame-length=8, can-addressing-mode=STANDARD, can-fd-frame-support=true, can-frame-rx-behavior=CAN-FD  # IDS"
        carries pdu C_IPB_SysSt: packing-byte-order=big-endian, start-position=7
      frame C_LDCU_RTorqInfo: id 0x106, to RDCU, frame-length=8, can-addressing-mode=STANDARD, can-fd-frame-support=true, can-frame-rx-behavior=CAN-FD
        carries pdu C_LDCU_RTorqInfo: packing-byte-order=big-endian, start-position=7
      frame C_IPB_Accel: id 0x1A8, to RDCU, frame-length=8, can-addressing-mode=STANDARD, can-fd-frame-support=true, can-frame-rx-behavior=CAN-FD
        carries pdu C_IPB_Accel: packing-byte-order=big-endian, start-position=7
      frame C_LDCU_SysSt: id 0x117, to RDCU, frame-length=8, can-addressing-mode=STANDARD, can-fd-frame-support=true, can-frame-rx-behavior=CAN-FD  # IDS"
        carries pdu C_LDCU_SysSt: packing-byte-order=big-endian, start-position=7
      frame C_LDCU_FTorqInfo: id 0x107, to RDCU, frame-length=8, can-addressing-mode=STANDARD, can-fd-frame-support=true, can-frame-rx-behavior=CAN-FD  # E2E Profile1 Message"
        carries pdu C_LDCU_FTorqInfo: packing-byte-order=big-endian, start-position=7
      frame C_LDCU_APBSysSt: id 0x1B4, to RDCU, frame-length=8, can-addressing-mode=STANDARD, can-fd-frame-support=true, can-frame-rx-behavior=CAN-FD  # E2E Profile1 Message"
        carries pdu C_LDCU_APBSysSt: packing-byte-order=big-endian, start-position=7
      frame C_IPB_SysSt2: id 0x18A, to RDCU, frame-length=8, can-addressing-mode=STANDARD, can-fd-frame-support=true, can-frame-rx-behavior=CAN-FD
        carries pdu C_IPB_SysSt2: packing-byte-order=big-endian, start-position=7
      frame C_AS_SysSt3: id 0x293, to RDCU, frame-length=8, can-addressing-mode=STANDARD, can-fd-frame-support=true, can-frame-rx-behavior=CAN-FD
        carries pdu C_AS_SysSt3: packing-byte-order=big-endian, start-position=7
      frame C_IPB_APBSysSt: id 0x1B2, to RDCU, frame-length=8, can-addressing-mode=STANDARD, can-fd-frame-support=true, can-frame-rx-behavior=CAN-FD  # IDS"
        carries pdu C_IPB_APBSysSt: packing-byte-order=big-endian, start-position=7
      frame C_LDCU_IPB_FaxleRegen: id 0x10A, to RDCU, frame-length=8, can-addressing-mode=STANDARD, can-fd-frame-support=true, can-frame-rx-behavior=CAN-FD
        carries pdu C_LDCU_IPB_FaxleRegen: packing-byte-order=big-endian, start-position=7
      frame C_RDCU_IPB_APB_ROPP: id 0x118, from RDCU, frame-length=8, can-addressing-mode=STANDARD, can-fd-frame-support=true, can-frame-tx-behavior=CAN-FD  # E2E Profile1 Message"
        carries pdu C_RDCU_IPB_APB_ROPP: packing-byte-order=big-endian, start-position=7
      frame C_RDCU_RLIN3Info: id 0x23F, from RDCU, frame-length=24, can-addressing-mode=STANDARD, can-fd-frame-support=true, can-frame-tx-behavior=CAN-FD
        carries pdu C_RDCU_RLIN3Info: packing-byte-order=big-endian, start-position=7
      frame C_RDCU_BodyCtrl2: id 0x21D, from RDCU, frame-length=8, can-addressing-mode=STANDARD, can-fd-frame-support=true, can-frame-tx-behavior=CAN-FD
        carries pdu C_RDCU_BodyCtrl2: packing-byte-order=big-endian, start-position=7
      frame C_RDCU_APBSysSt: id 0x1B3, from RDCU, frame-length=8, can-addressing-mode=STANDARD, can-fd-frame-support=true, can-frame-tx-behavior=CAN-FD  # E2E Profile1 Message"
        carries pdu C_RDCU_APBSysSt: packing-byte-order=big-endian, start-position=7
package /DBC_SysDesc_Can_Network/Pkg_ISignal
  9 x i signal group:
    ISigGrp_C_XPU_IPB_ADASToqCtrl: i-signal=[C_XPU_IPB_ADASToqCtrl_Byte0, C_XPU_IPB_ADASToqCtrl_Byte1, C_XPU_IPB_ADASToqCtrl_Byte2, C_XPU_IPB_ADASToqCtrl_Byte3, C_XPU_IPB_ADASToqCtrl_Byte4, C_XPU_IPB_ADASToqCtrl_Byte5, C_XPU_IPB_ADASToqCtrl_Byte6, C_XPU_IPB_ADASToqCtrl_Byte7], system-signal-group=SysSigGrp_C_XPU_IPB_ADASToqCtrl
    ISigGrp_C_LDCU_FTorqInfo: i-signal=[C_LDCU_FTorqInfo_Byte0, C_LDCU_FTorqInfo_Byte1, C_LDCU_FTorqInfo_Byte2, C_LDCU_FTorqInfo_Byte3, C_LDCU_FTorqInfo_Byte4, C_LDCU_FTorqInfo_Byte5, C_LDCU_FTorqInfo_Byte6, C_LDCU_FTorqInfo_Byte7], system-signal-group=SysSigGrp_C_LDCU_FTorqInfo
    ISigGrp_C_RDCU_APBSysSt: i-signal=[C_RDCU_APBSysSt_Byte0, C_RDCU_APBSysSt_Byte1, C_RDCU_APBSysSt_Byte2, C_RDCU_APBSysSt_Byte3, C_RDCU_APBSysSt_Byte4, C_RDCU_APBSysSt_Byte5, C_RDCU_APBSysSt_Byte6, C_RDCU_APBSysSt_Byte7], system-signal-group=SysSigGrp_C_RDCU_APBSysSt
    ISigGrp_C_RDCU_IPB_APB_ROPP: i-signal=[C_RDCU_IPB_APB_ROPP_Byte0, C_RDCU_IPB_APB_ROPP_Byte1, C_RDCU_IPB_APB_ROPP_Byte2, C_RDCU_IPB_APB_ROPP_Byte3, C_RDCU_IPB_APB_ROPP_Byte4, C_RDCU_IPB_APB_ROPP_Byte5, C_RDCU_IPB_APB_ROPP_Byte6, C_RDCU_IPB_APB_ROPP_Byte7], system-signal-group=SysSigGrp_C_RDCU_IPB_APB_ROPP
    ISigGrp_C_LDCU_APBSysSt: i-signal=[C_LDCU_APBSysSt_Byte0, C_LDCU_APBSysSt_Byte1, C_LDCU_APBSysSt_Byte2, C_LDCU_APBSysSt_Byte3, C_LDCU_APBSysSt_Byte4, C_LDCU_APBSysSt_Byte5, C_LDCU_APBSysSt_Byte6, C_LDCU_APBSysSt_Byte7], system-signal-group=SysSigGrp_C_LDCU_APBSysSt
    ISigGrp_C_LDCU_EPB_APB_ROPP2: i-signal=[C_LDCU_EPB_APB_ROPP2_Byte0, C_LDCU_EPB_APB_ROPP2_Byte1, C_LDCU_EPB_APB_ROPP2_Byte2, C_LDCU_EPB_APB_ROPP2_Byte3, C_LDCU_EPB_APB_ROPP2_Byte4, C_LDCU_EPB_APB_ROPP2_Byte5, C_LDCU_EPB_APB_ROPP2_Byte6, C_LDCU_EPB_APB_ROPP2_Byte7], system-signal-group=SysSigGrp_C_LDCU_EPB_APB_ROPP2
    ISigGrp_C_MFS_Status: i-signal=[C_MFS_Status_Byte0, C_MFS_Status_Byte1, C_MFS_Status_Byte2, C_MFS_Status_Byte3, C_MFS_Status_Byte4, C_MFS_Status_Byte5, C_MFS_Status_Byte6, C_MFS_Status_Byte7], system-signal-group=SysSigGrp_C_MFS_Status
    ISigGrp_C_IPB_SpdInfo_E2E: i-signal=[C_IPB_SpdInfo_E2E_Byte0, C_IPB_SpdInfo_E2E_Byte1, C_IPB_SpdInfo_E2E_Byte2, C_IPB_SpdInfo_E2E_Byte3, C_IPB_SpdInfo_E2E_Byte4, C_IPB_SpdInfo_E2E_Byte5, C_IPB_SpdInfo_E2E_Byte6, C_IPB_SpdInfo_E2E_Byte7, C_IPB_SpdInfo_E2E_Byte8, C_IPB_SpdInfo_E2E_Byte9, C_IPB_SpdInfo_E2E_Byte10, C_IPB_SpdInfo_E2E_Byte11, C_IPB_SpdInfo_E2E_Byte12, C_IPB_SpdInfo_E2E_Byte13, C_IPB_SpdInfo_E2E_Byte14, C_IPB_SpdInfo_E2E_Byte15], system-signal-group=SysSigGrp_C_IPB_SpdInfo_E2E
    ISigGrp_C_IPB_SysSt_E2E: i-signal=[C_IPB_SysSt_E2E_Byte0, C_IPB_SysSt_E2E_Byte1, C_IPB_SysSt_E2E_Byte2, C_IPB_SysSt_E2E_Byte3, C_IPB_SysSt_E2E_Byte4, C_IPB_SysSt_E2E_Byte5, C_IPB_SysSt_E2E_Byte6, C_IPB_SysSt_E2E_Byte7, C_IPB_SysSt_E2E_Byte8, C_IPB_SysSt_E2E_Byte9, C_IPB_SysSt_E2E_Byte10, C_IPB_SysSt_E2E_Byte11], system-signal-group=SysSigGrp_C_IPB_SysSt_E2E
package /DBC_SysDesc_Can_Network/Pkg_Ecu
  ecu instance RDCU: com-configuration-gw-time-base=0.005, com-configuration-rx-time-base=0.01, com-configuration-tx-time-base=0.01, sleep-mode-supported=false, wake-up-over-bus-supported=false
    can communication controller Can_Network_CANNODE_0: can-controller-attributes=can-controller-configuration={can-controller-fd-requirements=max-sample-point=81.25, prop-seg=0, sync-jump-width=0, time-seg-1=10, time-seg-2=0}
    can communication controller Can_Network_0_CANNODE_0: can-controller-attributes=can-controller-configuration={can-controller-fd-requirements=max-sample-point=81.25, prop-seg=0, sync-jump-width=0, time-seg-1=10, time-seg-2=0}
    can communication connector Conn_Can_Network_CANNODE_0_RDCU: comm-controller=Can_Network_CANNODE_0
    can communication connector Conn_Can_Network_0_CANNODE_0_RDCU: comm-controller=Can_Network_0_CANNODE_0
package /DBC_SysDesc_Can_Network/Pkg_Units
  12 x unit:
    kmph
    LUX
    barps
    rpm
    bar
    mm
    Nm
    degps
    deg
    degC
    g
    percent
